VERSION ""

NS_ :

BS_:

BU_: WPC2 RLPSU DPSU APSU PSB SHVU_RR vHS_B2 FCS EMCU SLB ARS RCM CGW_CCU vDummy_HS_B ATS RLHV SGU PFSU ALBCU DSAU SWRC SHVU_FR RCS RRPSU BLTN_CAM SCM DLBCU OHCL RWPC RRHV WPC HOD ASAU

BO_ 1218 HU_USM_E_08: 8 CGW_CCU
 SG_ C_AVN_PTGHeightNValueSet : 13|3@1+ (1,0) [0|0] "" Vector__XXX
 SG_ CF_AVN_SCCMLReset : 16|2@1+ (1,0) [0|0] "" Vector__XXX
 SG_ C_TgltAwayCloseNValue : 18|2@1+ (1,0) [0|0] "" Vector__XXX
 SG_ C_HAnBNValueSet : 20|2@1+ (1,0) [0|0] "" Vector__XXX
 SG_ CF_AVN_RrSeatRemindNValueSet : 22|2@1+ (1,0) [0|0] "" Vector__XXX
 SG_ CF_AVN_DSWNValueSet : 24|2@1+ (1,0) [0|0] "" Vector__XXX
 SG_ CF_AVN_RRPSU_RLNValueSet : 26|3@1+ (1,0) [0|0] ""  APSU,RRPSU
 SG_ CF_AVN_APSUNValueSet : 29|3@1+ (1,0) [0|0] ""  APSU,ASAU
 SG_ CF_AVN_NCC_CameraNValueSet : 32|3@1+ (1,0) [0|0] "" Vector__XXX
 SG_ CF_AVN_RRPSU_RRNValueSet : 37|3@1+ (1,0) [0|0] ""  APSU,RRPSU
 SG_ CF_AVN_HtBlcAstNValueSet : 40|4@1+ (1,0) [0|0] ""  APSU,SHVU_FR
 SG_ CF_AVN_HtBlcDrvNValueSet : 44|4@1+ (1,0) [0|0] ""  APSU,SHVU_FR
 SG_ CF_AVN_SCCModeNValueSet : 48|2@1+ (1,0) [0|0] "" Vector__XXX
 SG_ CF_AVN_SCCMLChar1Set : 50|3@1+ (1,0) [0|0] "" Vector__XXX
 SG_ CF_AVN_UIPNValueSet : 54|2@1+ (1,0) [0|0] "" Vector__XXX
 SG_ CF_AVN_SCCMLChar2Set : 56|3@1+ (1,0) [0|0] "" Vector__XXX
 SG_ CF_AVN_SCCMLChar3Set : 59|3@1+ (1,0) [0|0] "" Vector__XXX
 SG_ CF_AVN_HDALCFuncNValueSet : 8|2@1+ (1,0) [0|0] "" Vector__XXX

BO_ 2323816451 CCU_CCS_01_00ms_3: 8 CGW_CCU

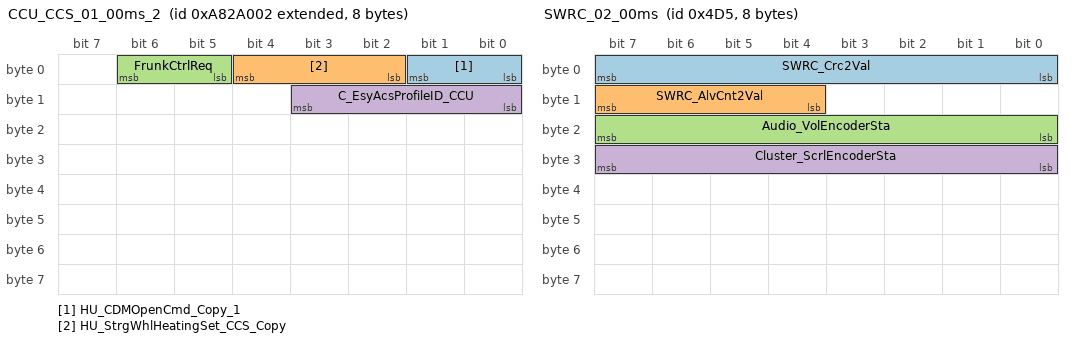
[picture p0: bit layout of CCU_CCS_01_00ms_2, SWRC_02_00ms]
BO_ 2323816450 CCU_CCS_01_00ms_2: 8 CGW_CCU
 SG_ HU_CDMOpenCmd_Copy_1 : 0|2@1+ (1,0) [0|0] "" Vector__XXX
 SG_ HU_StrgWhlHeatingSet_CCS_Copy : 2|3@1+ (1,0) [0|0] "" Vector__XXX
 SG_ FrunkCtrlReq : 5|2@1+ (1,0) [0|0] "" Vector__XXX
 SG_ C_EsyAcsProfileID_CCU : 8|4@1+ (1,0) [0|0] ""  DPSU

BO_ 2323816449 CCU_CCS_01_00ms_1: 8 CGW_CCU
 SG_ C_CtrlDrLockRlyCCS_Copy_2 : 0|2@1+ (1,0) [0|0] "" Vector__XXX
 SG_ C_TeleHeatingCmdIBOX_Copy_2 : 10|2@1+ (1,0) [0|0] "" Vector__XXX
 SG_ C_TeleStrgWhlHeatingCmdIBOX_Copy : 12|2@1+ (1,0) [0|0] "" Vector__XXX
 SG_ C_TeleDefoggerHeatingCmdIBOX_Cop : 14|2@1+ (1,0) [0|0] "" Vector__XXX
 SG_ C_TeleDrvSeatOpCmdIBOX_Copy_2 : 16|4@1+ (1,0) [0|0] ""  SHVU_FR,DPSU
 SG_ C_CtrlDrUnlockRlyCCS_Copy_2 : 2|2@1+ (1,0) [0|0] "" Vector__XXX
 SG_ C_TeleAstSeatOpCmdIBOX_Copy_2 : 20|4@1+ (1,0) [0|0] ""  APSU,SHVU_FR
 SG_ C_TeleRRSeatOpCmdIBOX_Copy_2 : 24|4@1+ (1,0) [0|0] ""  RRHV,SHVU_FR,SHVU_RR,RRPSU,ATS
 SG_ C_TeleRLSeatOpCmdIBOX_Copy_1 : 28|4@1+ (1,0) [0|0] ""  RLHV,SHVU_FR,SHVU_RR,RLPSU,ATS
 SG_ C_DrvWindowCmdAVN_Copy_2 : 38|4@1+ (1,0) [0|0] "" Vector__XXX
 SG_ C_HazardFromCCS_Copy_2 : 4|2@1+ (1,0) [0|0] "" Vector__XXX
 SG_ C_AstWindowCmdAVN_Copy_2 : 42|4@1+ (1,0) [0|0] "" Vector__XXX
 SG_ C_RRWindowCmdAVN_Copy_2 : 46|4@1+ (1,0) [0|0] "" Vector__XXX
 SG_ C_RLWindowCmdAVN_Copy_2 : 50|4@1+ (1,0) [0|0] "" Vector__XXX
 SG_ TailCtrlReq_Copy : 54|2@1+ (1,0) [0|0] "" Vector__XXX
 SG_ HazardCtrlReq_Copy : 56|2@1+ (1,0) [0|0] "" Vector__XXX
 SG_ HU_DATC_AirCleaningSet_Copy_1 : 58|2@1+ (1,0) [0|0] "" Vector__XXX
 SG_ C_PanicFromCCS_Copy_2 : 6|2@1+ (1,0) [0|0] "" Vector__XXX
 SG_ C_TeleFrontHeatingCmdIBOX_Copy_1 : 60|2@1+ (1,0) [0|0] "" Vector__XXX
 SG_ RAC_AirCleaningCtrlReq_Copy_1 : 62|2@1+ (1,0) [0|0] "" Vector__XXX
 SG_ C_PreCrankReq_Copy : 8|2@1+ (1,0) [0|0] "" Vector__XXX

BO_ 1227 PSM_01_00ms: 8 DPSU
 SG_ DrvIMS_MemoryP1Req : 0|2@1+ (1,0) [0|0] ""  CGW_CCU
 SG_ DrvIMS_PlyBckP2Req : 10|2@1+ (1,0) [0|0] ""  CGW_CCU
 SG_ DrvIMS_PlyBckP3Req : 12|2@1+ (1,0) [0|0] ""  CGW_CCU
 SG_ DrvIMS_PlyBckStpReq : 14|2@1+ (1,0) [0|0] ""  CGW_CCU
 SG_ SmrtIMS_PlyBckReq : 16|12@1+ (1,0) [0|0] ""  CGW_CCU
 SG_ DrvIMS_MemoryP2Req : 2|2@1+ (1,0) [0|0] ""  CGW_CCU
 SG_ PSM_IMSReq : 28|3@1+ (1,0) [0|0] ""  CGW_CCU
 SG_ SmrtIMS_ImgDBVal : 32|5@1+ (1,0) [0|0] ""  CGW_CCU
 SG_ SmrtIMS_PlyBckStpReq : 37|2@1+ (1,0) [0|0] ""  CGW_CCU
 SG_ DrvIMS_MemoryP3Req : 4|2@1+ (1,0) [0|0] ""  CGW_CCU
 SG_ SmrtIMS_EnterSwSta : 40|2@1+ (1,0) [0|0] ""  CGW_CCU
 SG_ DrvIMS_BzrReq : 42|2@1+ (1,0) [0|0] ""  CGW_CCU
 SG_ DrvIMS_ErrConWmgDis : 46|2@1+ (1,0) [0|0] ""  CGW_CCU
 SG_ PSM_DrvRlxReturn_Req : 48|3@1+ (1,0) [0|0] ""  CGW_CCU
 SG_ Drv_AutoRlxWrngDis : 51|3@1+ (1,0) [0|0] ""  CGW_CCU
 SG_ DrvIMS_MemorySetEnaSta : 6|2@1+ (1,0) [0|0] ""  CGW_CCU
 SG_ DrvIMS_PlyBckP1Req : 8|2@1+ (1,0) [0|0] ""  CGW_CCU

BO_ 2323816452 CCU_CCS_01_00ms_4: 8 CGW_CCU

BO_ 1237 SWRC_02_00ms: 8 SWRC
 SG_ SWRC_Crc2Val : 0|8@1+ (1,0) [0|0] "" Vector__XXX
 SG_ SWRC_AlvCnt2Val : 12|4@1+ (1,0) [0|0] "" Vector__XXX
 SG_ Audio_VolEncoderSta : 16|8@1+ (1,0) [0|0] ""  CGW_CCU
 SG_ Cluster_ScrlEncoderSta : 24|8@1+ (1,0) [0|0] ""  CGW_CCU

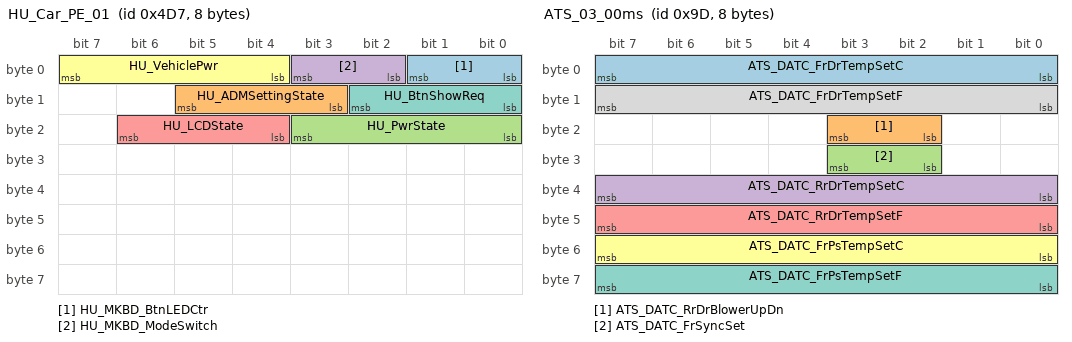
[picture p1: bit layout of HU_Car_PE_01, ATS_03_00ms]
BO_ 1239 HU_Car_PE_01: 8 CGW_CCU
 SG_ HU_MKBD_BtnLEDCtr : 0|2@1+ (1,0) [0|0] "" Vector__XXX
 SG_ HU_ADMSettingState : 11|3@1+ (1,0) [0|0] "" Vector__XXX
 SG_ HU_PwrState : 16|4@1+ (1,0) [0|0] ""  BLTN_CAM
 SG_ HU_MKBD_ModeSwitch : 2|2@1+ (1,0) [0|0] "" Vector__XXX
 SG_ HU_LCDState : 20|3@1+ (1,0) [0|0] "" Vector__XXX
 SG_ HU_VehiclePwr : 4|4@1+ (1,0) [0|0] ""  BLTN_CAM,SGU
 SG_ HU_BtnShowReq : 8|3@1+ (1,0) [0|0] ""  SWRC

BO_ 157 ATS_03_00ms: 8 ATS
 SG_ ATS_DATC_FrDrTempSetC : 0|8@1+ (0.5,14) [0|0] ""  CGW_CCU
 SG_ ATS_DATC_RrDrBlowerUpDn : 18|2@1+ (1,0) [0|0] ""  CGW_CCU
 SG_ ATS_DATC_FrSyncSet : 26|2@1+ (1,0) [0|0] ""  CGW_CCU
 SG_ ATS_DATC_RrDrTempSetC : 32|8@1+ (0.5,14) [0|0] ""  CGW_CCU
 SG_ ATS_DATC_RrDrTempSetF : 40|8@1+ (1,56) [0|0] ""  CGW_CCU
 SG_ ATS_DATC_FrPsTempSetC : 48|8@1+ (0.5,14) [0|0] ""  CGW_CCU
 SG_ ATS_DATC_FrPsTempSetF : 56|8@1+ (1,56) [0|0] ""  CGW_CCU
 SG_ ATS_DATC_FrDrTempSetF : 8|8@1+ (1,56) [0|0] ""  CGW_CCU

BO_ 158 ATS_02_00ms: 8 ATS
 SG_ ATS_DATC_FrDrBlowerSet : 12|4@1+ (1,0) [0|0] ""  CGW_CCU
 SG_ ATS_DATC_RrDrTempUpDn : 2|2@1+ (1,0) [0|0] ""  CGW_CCU
 SG_ ATS_DATC_RrDrBlowerSet : 20|4@1+ (1,0) [0|0] ""  CGW_CCU
 SG_ ATS_DATC_RrDrModeSet : 24|4@1+ (1,0) [0|0] ""  CGW_CCU
 SG_ ATS_DATC_FrDrModeSet : 28|4@1+ (1,0) [0|0] ""  CGW_CCU
 SG_ ATS_DATC_RrOnOffSet : 32|2@1+ (1,0) [0|0] "" Vector__XXX
 SG_ ATS_DATC_IntakeSet : 34|2@1+ (1,0) [0|0] ""  CGW_CCU
 SG_ ATS_DATC_OffReq : 36|2@1+ (1,0) [0|0] "" Vector__XXX
 SG_ ATS_DATC_FrDrAutoSet : 38|2@1+ (1,0) [0|0] ""  CGW_CCU
 SG_ ATS_DATC_FrPsTempUpDn : 4|2@1+ (1,0) [0|0] ""  CGW_CCU
 SG_ ATS_DATC_FrDefog : 42|2@1+ (1,0) [0|0] ""  CGW_CCU
 SG_ ATS_DATC_RrSyncSet : 44|2@1+ (1,0) [0|0] ""  CGW_CCU
 SG_ ATS_DATC_AcSet : 46|2@1+ (1,0) [0|0] ""  CGW_CCU
 SG_ ATS_DATC_AirCleaningSet : 56|2@1+ (1,0) [0|0] ""  CGW_CCU
 SG_ ATS_DATC_FrDrBlowerUpDn : 58|2@1+ (1,0) [0|0] ""  CGW_CCU
 SG_ ATS_DATC_FrDrTempUpDn : 6|2@1+ (1,0) [0|0] ""  CGW_CCU
 SG_ ATS_DATC_RrDrAutoSet : 62|2@1+ (1,0) [0|0] ""  CGW_CCU

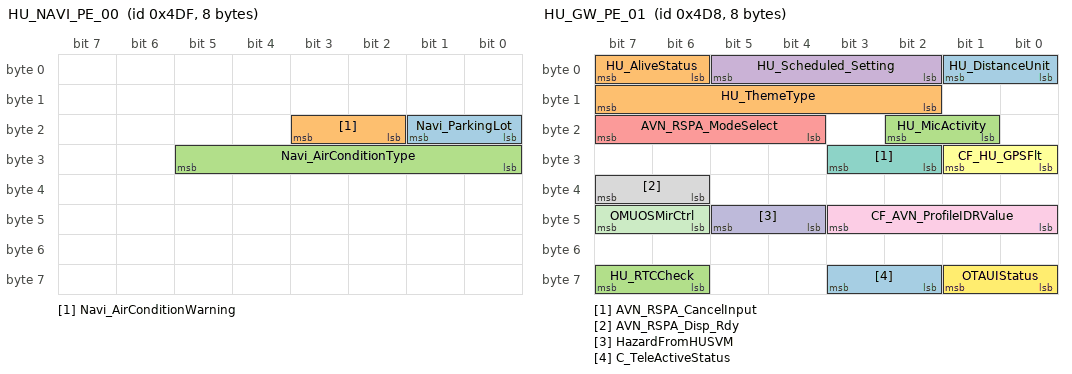
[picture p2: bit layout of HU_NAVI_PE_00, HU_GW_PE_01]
BO_ 1247 HU_NAVI_PE_00: 8 CGW_CCU
 SG_ Navi_ParkingLot : 16|2@1+ (1,0) [0|0] "" Vector__XXX
 SG_ Navi_AirConditionWarning : 18|2@1+ (1,0) [0|0] ""  RCM
 SG_ Navi_AirConditionType : 24|6@1+ (1,0) [0|0] "" Vector__XXX

BO_ 1240 HU_GW_PE_01: 8 CGW_CCU
 SG_ HU_DistanceUnit : 0|2@1+ (1,0) [0|0] "" Vector__XXX
 SG_ HU_ThemeType : 10|6@1+ (1,0) [0|0] ""  ATS,BLTN_CAM
 SG_ HU_MicActivity : 17|2@1+ (1,0) [0|0] "" Vector__XXX
 SG_ HU_Scheduled_Setting : 2|4@1+ (1,0) [0|0] "" Vector__XXX
 SG_ AVN_RSPA_ModeSelect : 20|4@1+ (1,0) [0|0] "" Vector__XXX
 SG_ CF_HU_GPSFlt : 24|2@1+ (1,0) [0|0] "" Vector__XXX
 SG_ AVN_RSPA_CancelInput : 26|2@1+ (1,0) [0|3] "" Vector__XXX
 SG_ AVN_RSPA_Disp_Rdy : 38|2@1+ (1,0) [0|0] "" Vector__XXX
 SG_ CF_AVN_ProfileIDRValue : 40|4@1+ (1,0) [0|0] ""  WPC,RWPC,DPSU,DLBCU,RCM,BLTN_CAM,SGU,WPC2
 SG_ HazardFromHUSVM : 44|2@1+ (1,0) [0|0] "" Vector__XXX
 SG_ OMUOSMirCtrl : 46|2@1+ (1,0) [0|0] "" Vector__XXX
 SG_ OTAUIStatus : 56|2@1+ (1,0) [0|0] "" Vector__XXX
 SG_ C_TeleActiveStatus : 58|2@1+ (1,0) [0|0] "" Vector__XXX
 SG_ HU_AliveStatus : 6|2@1+ (1,0) [0|0] "" Vector__XXX
 SG_ HU_RTCCheck : 62|2@1+ (1,0) [0|0] ""  APSU

BO_ 2424580353 DATC_12_200ms_1: 8 CGW_CCU
 SG_ DATC_Crc12Val : 0|16@1+ (1,0) [0|0] "" Vector__XXX
 SG_ DATC_AlvCnt12Val : 16|8@1+ (1,0) [0|0] "" Vector__XXX
 SG_ DATC_StrWhlHtrSwReq : 24|2@1+ (1,0) [0|0] "" Vector__XXX
 SG_ DATC_FRStHtrSwReq : 26|2@1+ (1,0) [0|0] ""  APSU,SHVU_FR,SHVU_RR,DPSU
 SG_ DATC_FRStVentSwReq : 28|2@1+ (1,0) [0|0] ""  APSU,SHVU_FR,SHVU_RR,DPSU
 SG_ DATC_RrDefSw : 30|2@1+ (1,0) [0|0] "" Vector__XXX
 SG_ DATC_FLStOpReq : 32|4@1+ (1,0) [0|0] ""  APSU,SHVU_FR,SHVU_RR,DPSU
 SG_ DATC_FRStOpReq : 36|4@1+ (1,0) [0|0] ""  APSU,SHVU_FR,SHVU_RR
 SG_ DATC_FLStHtrSwReq : 40|2@1+ (1,0) [0|0] ""  APSU,SHVU_FR,SHVU_RR,DPSU
 SG_ DATC_FLStVentSwReq : 42|2@1+ (1,0) [0|0] ""  APSU,SHVU_FR,SHVU_RR,DPSU
 SG_ DATC_FLStTmblrSwReq : 44|2@1+ (1,0) [0|0] ""  APSU,SHVU_FR
 SG_ DATC_FRStTmblrSwReq : 46|2@1+ (1,0) [0|0] ""  APSU,SHVU_FR
 SG_ DATC_RRStHtrSwReq : 48|2@1+ (1,0) [0|0] ""  RRHV,SHVU_FR,SHVU_RR,RRPSU
 SG_ DATC_RRStVentSwReq : 50|2@1+ (1,0) [0|0] ""  RRHV,SHVU_FR,SHVU_RR,RRPSU
 SG_ DATC_RLStHtrSwReq : 52|2@1+ (1,0) [0|0] ""  RLHV,SHVU_FR,SHVU_RR,RLPSU
 SG_ DATC_RLStVentSwReq : 54|2@1+ (1,0) [0|0] ""  RLHV,SHVU_FR,SHVU_RR,RLPSU
 SG_ DATC_FRWndShldHtSW : 56|2@1+ (1,0) [0|0] "" Vector__XXX
 SG_ DATC_WhistlelNoise : 58|2@1+ (1,0) [0|0] "" Vector__XXX
 SG_ DATC_WdwClsReq : 60|2@1+ (1,0) [0|0] "" Vector__XXX
 SG_ DATC_RRSyncDis : 62|2@1+ (1,0) [0|0] ""  ATS

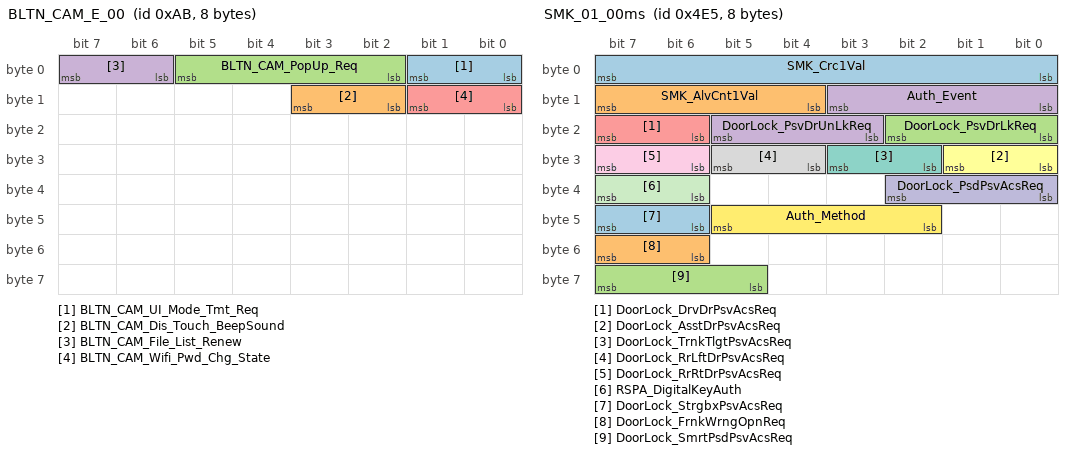
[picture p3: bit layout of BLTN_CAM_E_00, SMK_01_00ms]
BO_ 171 BLTN_CAM_E_00: 8 BLTN_CAM
 SG_ BLTN_CAM_UI_Mode_Tmt_Req : 0|2@1+ (1,0) [0|0] ""  CGW_CCU
 SG_ BLTN_CAM_Dis_Touch_BeepSound : 10|2@1+ (1,0) [0|0] "" Vector__XXX
 SG_ BLTN_CAM_PopUp_Req : 2|4@1+ (1,0) [0|0] ""  CGW_CCU
 SG_ BLTN_CAM_File_List_Renew : 6|2@1+ (1,0) [0|0] ""  CGW_CCU
 SG_ BLTN_CAM_Wifi_Pwd_Chg_State : 8|2@1+ (1,0) [0|0] ""  CGW_CCU

BO_ 1253 SMK_01_00ms: 8 CGW_CCU
 SG_ SMK_Crc1Val : 0|8@1+ (1,0) [0|0] "" Vector__XXX
 SG_ SMK_AlvCnt1Val : 12|4@1+ (1,0) [0|0] "" Vector__XXX
 SG_ DoorLock_PsvDrLkReq : 16|3@1+ (1,0) [0|0] "" Vector__XXX
 SG_ DoorLock_PsvDrUnLkReq : 19|3@1+ (1,0) [0|0] "" Vector__XXX
 SG_ DoorLock_DrvDrPsvAcsReq : 22|2@1+ (1,0) [0|0] "" Vector__XXX
 SG_ DoorLock_AsstDrPsvAcsReq : 24|2@1+ (1,0) [0|0] "" Vector__XXX
 SG_ DoorLock_TrnkTlgtPsvAcsReq : 26|2@1+ (1,0) [0|0] "" Vector__XXX
 SG_ DoorLock_RrLftDrPsvAcsReq : 28|2@1+ (1,0) [0|0] "" Vector__XXX
 SG_ DoorLock_RrRtDrPsvAcsReq : 30|2@1+ (1,0) [0|0] "" Vector__XXX
 SG_ DoorLock_PsdPsvAcsReq : 32|3@1+ (1,0) [0|0] "" Vector__XXX
 SG_ RSPA_DigitalKeyAuth : 38|2@1+ (1,0) [0|0] "" Vector__XXX
 SG_ Auth_Method : 42|4@1+ (1,0) [0|0] ""  DPSU
 SG_ DoorLock_StrgbxPsvAcsReq : 46|2@1+ (1,0) [0|0] "" Vector__XXX
 SG_ DoorLock_FrnkWrngOpnReq : 54|2@1+ (1,0) [0|0] "" Vector__XXX
 SG_ DoorLock_SmrtPsdPsvAcsReq : 61|3@1+ (1,0) [0|0] "" Vector__XXX
 SG_ Auth_Event : 8|4@1+ (1,0) [0|0] ""  DPSU

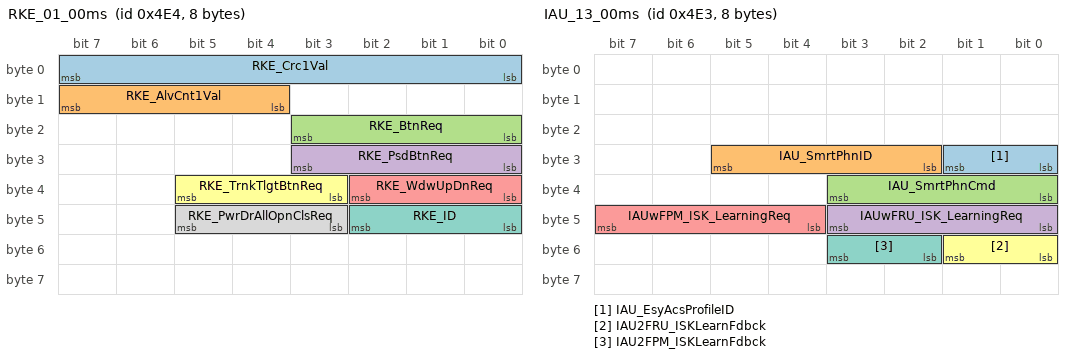
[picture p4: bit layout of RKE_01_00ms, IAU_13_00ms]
BO_ 1252 RKE_01_00ms: 8 CGW_CCU
 SG_ RKE_Crc1Val : 0|8@1+ (1,0) [0|0] "" Vector__XXX
 SG_ RKE_AlvCnt1Val : 12|4@1+ (1,0) [0|0] "" Vector__XXX
 SG_ RKE_BtnReq : 16|4@1+ (1,0) [0|0] ""  ATS
 SG_ RKE_PsdBtnReq : 24|4@1+ (1,0) [0|0] "" Vector__XXX
 SG_ RKE_WdwUpDnReq : 32|3@1+ (1,0) [0|0] ""  RCM
 SG_ RKE_TrnkTlgtBtnReq : 35|3@1+ (1,0) [0|0] "" Vector__XXX
 SG_ RKE_ID : 40|3@1+ (1,0) [0|0] "" Vector__XXX
 SG_ RKE_PwrDrAllOpnClsReq : 43|3@1+ (1,0) [0|0] "" Vector__XXX

BO_ 1251 IAU_13_00ms: 8 CGW_CCU
 SG_ IAU_EsyAcsProfileID : 24|2@1+ (1,0) [0|0] ""  DPSU
 SG_ IAU_SmrtPhnID : 26|4@1+ (1,0) [0|0] "" Vector__XXX
 SG_ IAU_SmrtPhnCmd : 32|4@1+ (1,0) [0|0] "" Vector__XXX
 SG_ IAUwFRU_ISK_LearningReq : 40|4@1+ (1,0) [0|0] "" Vector__XXX
 SG_ IAUwFPM_ISK_LearningReq : 44|4@1+ (1,0) [0|0] "" Vector__XXX
 SG_ IAU2FRU_ISKLearnFdbck : 48|2@1+ (1,0) [0|0] "" Vector__XXX
 SG_ IAU2FPM_ISKLearnFdbck : 50|2@1+ (1,0) [0|0] "" Vector__XXX

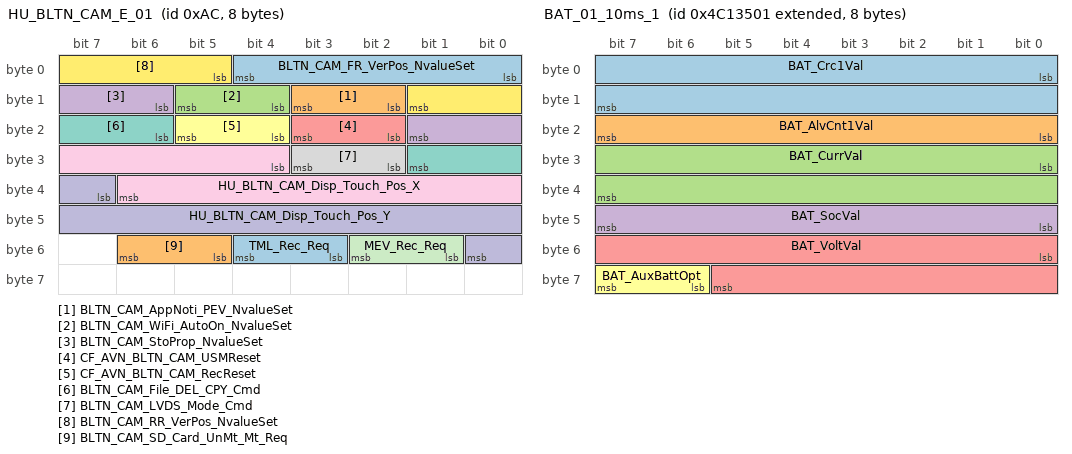
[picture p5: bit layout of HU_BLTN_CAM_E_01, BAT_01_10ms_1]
BO_ 172 HU_BLTN_CAM_E_01: 8 CGW_CCU
 SG_ BLTN_CAM_FR_VerPos_NvalueSet : 0|5@1+ (1,0) [0|0] ""  BLTN_CAM
 SG_ BLTN_CAM_AppNoti_PEV_NvalueSet : 10|2@1+ (1,0) [0|0] ""  BLTN_CAM
 SG_ BLTN_CAM_WiFi_AutoOn_NvalueSet : 12|2@1+ (1,0) [0|0] ""  BLTN_CAM
 SG_ BLTN_CAM_StoProp_NvalueSet : 14|4@1+ (1,0) [0|0] ""  BLTN_CAM
 SG_ CF_AVN_BLTN_CAM_USMReset : 18|2@1+ (1,0) [0|0] ""  BLTN_CAM
 SG_ CF_AVN_BLTN_CAM_RecReset : 20|2@1+ (1,0) [0|0] ""  BLTN_CAM
 SG_ BLTN_CAM_File_DEL_CPY_Cmd : 22|4@1+ (1,0) [0|0] ""  BLTN_CAM
 SG_ BLTN_CAM_LVDS_Mode_Cmd : 26|2@1+ (1,0) [0|0] ""  BLTN_CAM
 SG_ HU_BLTN_CAM_Disp_Touch_Pos_X : 28|11@1+ (1,0) [0|0] ""  BLTN_CAM
 SG_ HU_BLTN_CAM_Disp_Touch_Pos_Y : 39|10@1+ (1,0) [0|0] ""  BLTN_CAM
 SG_ MEV_Rec_Req : 49|2@1+ (1,0) [0|0] ""  BLTN_CAM
 SG_ BLTN_CAM_RR_VerPos_NvalueSet : 5|5@1+ (1,0) [0|0] ""  BLTN_CAM
 SG_ TML_Rec_Req : 51|2@1+ (1,0) [0|0] ""  BLTN_CAM
 SG_ BLTN_CAM_SD_Card_UnMt_Mt_Req : 53|2@1+ (1,0) [0|0] ""  BLTN_CAM

BO_ 2227254529 BAT_01_10ms_1: 8 CGW_CCU
 SG_ BAT_Crc1Val : 0|16@1+ (1,0) [0|0] "" Vector__XXX
 SG_ BAT_AlvCnt1Val : 16|8@1+ (1,0) [0|0] "" Vector__XXX
 SG_ BAT_CurrVal : 24|16@1+ (0.01,-327) [0|0] "A" Vector__XXX
 SG_ BAT_SocVal : 40|8@1+ (1,0) [0|0] "%"  BLTN_CAM
 SG_ BAT_VoltVal : 48|14@1+ (0.001,6) [0|0] "V" Vector__XXX
 SG_ BAT_AuxBattOpt : 62|2@1+ (1,0) [0|0] "" Vector__XXX

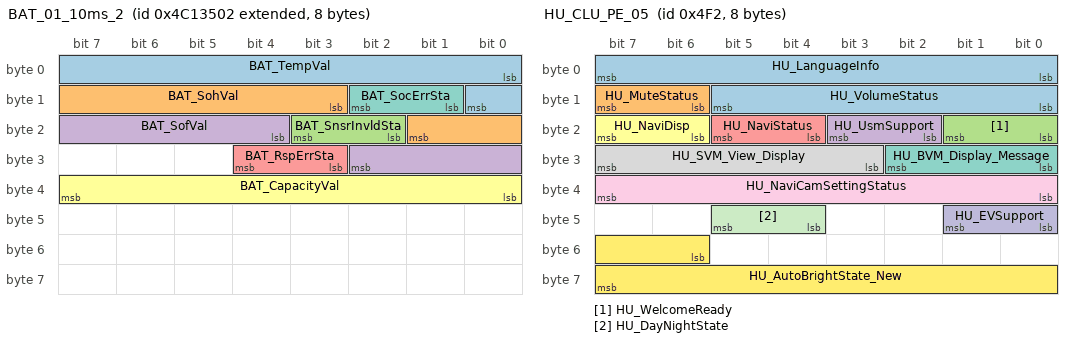
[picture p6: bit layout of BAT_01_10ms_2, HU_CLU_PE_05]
BO_ 2227254530 BAT_01_10ms_2: 8 CGW_CCU
 SG_ BAT_TempVal : 0|9@1+ (0.5,-40) [0|0] "¡É" Vector__XXX
 SG_ BAT_SohVal : 11|7@1+ (1,0) [0|0] "%" Vector__XXX
 SG_ BAT_SnsrInvldSta : 18|2@1+ (1,0) [0|0] "" Vector__XXX
 SG_ BAT_SofVal : 20|7@1+ (0.1,0) [0|0] "V" Vector__XXX
 SG_ BAT_RspErrSta : 27|2@1+ (1,0) [0|0] "" Vector__XXX
 SG_ BAT_CapacityVal : 32|8@1+ (1,0) [0|0] "" Vector__XXX
 SG_ BAT_SocErrSta : 9|2@1+ (1,0) [0|0] "" Vector__XXX

BO_ 1266 HU_CLU_PE_05: 8 CGW_CCU
 SG_ HU_LanguageInfo : 0|8@1+ (1,0) [0|0] ""  ATS,BLTN_CAM
 SG_ HU_MuteStatus : 14|2@1+ (1,0) [0|0] "" Vector__XXX
 SG_ HU_WelcomeReady : 16|2@1+ (1,0) [0|0] "" Vector__XXX
 SG_ HU_UsmSupport : 18|2@1+ (1,0) [0|0] "" Vector__XXX
 SG_ HU_NaviStatus : 20|2@1+ (1,0) [0|0] "" Vector__XXX
 SG_ HU_NaviDisp : 22|2@1+ (1,0) [0|0] "" Vector__XXX
 SG_ HU_BVM_Display_Message : 24|3@1+ (1,0) [0|0] "" Vector__XXX
 SG_ HU_SVM_View_Display : 27|5@1+ (1,0) [0|0] "" Vector__XXX
 SG_ HU_NaviCamSettingStatus : 32|8@1+ (1,0) [0|0] "" Vector__XXX
 SG_ HU_EVSupport : 40|2@1+ (1,0) [0|0] "" Vector__XXX
 SG_ HU_DayNightState : 44|2@1+ (1,0) [0|0] "" Vector__XXX
 SG_ HU_AutoBrightState_New : 54|10@1+ (1,0) [0|0] "" Vector__XXX
 SG_ HU_VolumeStatus : 8|6@1+ (1,0) [0|0] "" Vector__XXX

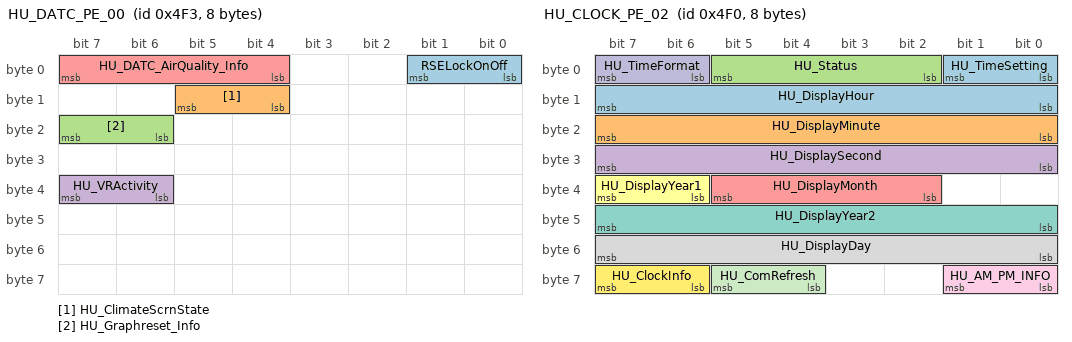
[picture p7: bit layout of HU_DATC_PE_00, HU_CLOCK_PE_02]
BO_ 1267 HU_DATC_PE_00: 8 CGW_CCU
 SG_ RSELockOnOff : 0|2@1+ (1,0) [0|0] ""  APSU,ATS
 SG_ HU_ClimateScrnState : 12|2@1+ (1,0) [0|0] "" Vector__XXX
 SG_ HU_Graphreset_Info : 22|2@1+ (1,0) [0|0] "" Vector__XXX
 SG_ HU_VRActivity : 38|2@1+ (1,0) [0|0] "" Vector__XXX
 SG_ HU_DATC_AirQuality_Info : 4|4@1+ (1,0) [0|0] "" Vector__XXX

BO_ 191 RL_SHVU_03_200ms: 8 RLHV
 SG_ RL_SHVU_DTCdisplay : 0|8@1+ (1,0) [0|0] ""  ATS
 SG_ RL_SHVU_DiagMode : 8|2@1+ (1,0) [0|0] ""  ATS

BO_ 1264 HU_CLOCK_PE_02: 8 CGW_CCU
 SG_ HU_TimeSetting : 0|2@1+ (1,0) [0|0] ""  ATS,BLTN_CAM
 SG_ HU_DisplayMinute : 16|8@1+ (1,0) [0|0] ""  ATS,BLTN_CAM
 SG_ HU_Status : 2|4@1+ (1,0) [0|0] ""  ATS,BLTN_CAM
 SG_ HU_DisplaySecond : 24|8@1+ (1,0) [0|0] ""  ATS,BLTN_CAM
 SG_ HU_DisplayMonth : 34|4@1+ (1,0) [0|0] ""  ATS,BLTN_CAM
 SG_ HU_DisplayYear1 : 38|2@1+ (1,0) [0|0] ""  ATS,BLTN_CAM
 SG_ HU_DisplayYear2 : 40|8@1+ (1,0) [0|0] ""  ATS,BLTN_CAM
 SG_ HU_DisplayDay : 48|8@1+ (1,0) [0|0] ""  ATS,BLTN_CAM
 SG_ HU_AM_PM_INFO : 56|2@1+ (1,0) [0|0] ""  ATS,BLTN_CAM
 SG_ HU_TimeFormat : 6|2@1+ (1,0) [0|0] ""  ATS,BLTN_CAM
 SG_ HU_ComRefresh : 60|2@1+ (1,0) [0|0] ""  ATS,BLTN_CAM
 SG_ HU_ClockInfo : 62|2@1+ (1,0) [0|0] ""  ATS,BLTN_CAM
 SG_ HU_DisplayHour : 8|8@1+ (1,0) [0|0] ""  ATS,BLTN_CAM

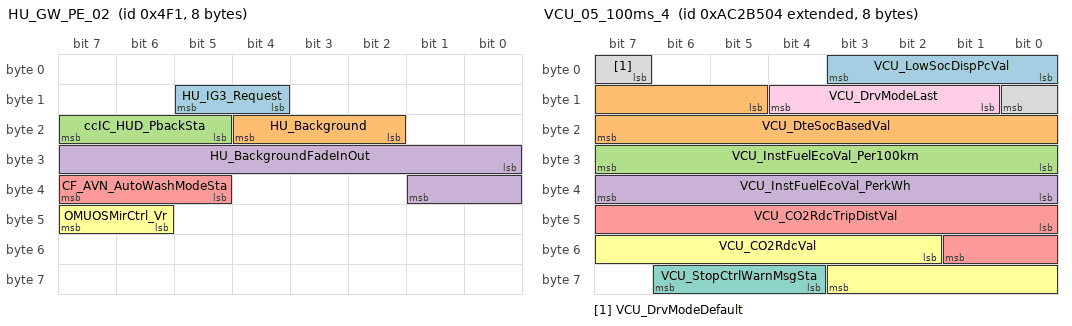
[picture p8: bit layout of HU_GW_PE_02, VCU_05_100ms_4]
BO_ 1265 HU_GW_PE_02: 8 CGW_CCU
 SG_ HU_IG3_Request : 12|2@1+ (1,0) [0|0] "" Vector__XXX
 SG_ HU_Background : 18|3@1+ (1,0) [0|0] ""  ATS,BLTN_CAM
 SG_ ccIC_HUD_PbackSta : 21|3@1+ (1,0) [0|0] ""  DPSU
 SG_ HU_BackgroundFadeInOut : 24|10@1+ (0.1,0) [0|0] "%"  ATS,BLTN_CAM
 SG_ CF_AVN_AutoWashModeSta : 37|3@1+ (1,0) [0|0] "" Vector__XXX
 SG_ OMUOSMirCtrl_Vr : 46|2@1+ (1,0) [0|0] "" Vector__XXX

BO_ 2328016132 VCU_05_100ms_4: 8 CGW_CCU
 SG_ VCU_LowSocDispPcVal : 0|4@1+ (1,0) [0|0] "" Vector__XXX
 SG_ VCU_DteSocBasedVal : 13|11@1+ (1,0) [0|0] "km" Vector__XXX
 SG_ VCU_InstFuelEcoVal_Per100km : 24|8@1+ (0.5,0) [0|126.5] "kWh/100km" Vector__XXX
 SG_ VCU_InstFuelEcoVal_PerkWh : 32|8@1+ (0.1,0) [0|25.5] "km/kWh" Vector__XXX
 SG_ VCU_CO2RdcTripDistVal : 40|10@1+ (1,0) [0|1023] "km" Vector__XXX
 SG_ VCU_CO2RdcVal : 50|10@1+ (100,0) [0|102300] "g" Vector__XXX
 SG_ VCU_StopCtrlWarnMsgSta : 60|3@1+ (1,0) [0|0] "" Vector__XXX
 SG_ VCU_DrvModeDefault : 7|2@1+ (1,0) [0|0] "" Vector__XXX
 SG_ VCU_DrvModeLast : 9|4@1+ (1,0) [0|0] "" Vector__XXX

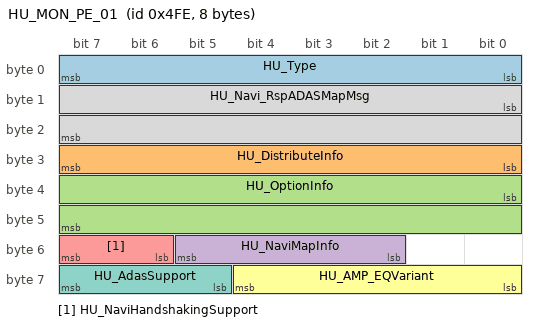
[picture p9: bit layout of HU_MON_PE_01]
BO_ 1278 HU_MON_PE_01: 8 CGW_CCU
 SG_ HU_Type : 0|8@1+ (1,0) [0|0] ""  BLTN_CAM
 SG_ HU_DistributeInfo : 24|8@1+ (1,0) [0|0] ""  BLTN_CAM
 SG_ HU_OptionInfo : 32|16@1+ (1,0) [0|0] ""  RCM,BLTN_CAM,WPC2
 SG_ HU_NaviMapInfo : 50|4@1+ (1,0) [0|0] "" Vector__XXX
 SG_ HU_NaviHandshakingSupport : 54|2@1+ (1,0) [0|0] "" Vector__XXX
 SG_ HU_AMP_EQVariant : 56|5@1+ (1,0) [0|0] "" Vector__XXX
 SG_ HU_AdasSupport : 61|3@1+ (1,0) [0|0] "" Vector__XXX
 SG_ HU_Navi_RspADASMapMsg : 8|16@1+ (1,0) [0|0] "" Vector__XXX

BO_TX_BU_ 191 : RLHV,SHVU_FR,SHVU_RR;
CM_ BO_ 1218 "[EC] On Event and On Change";
CM_ SG_ 1218 C_AVN_PTGHeightNValueSet "Power Tailgate(Trunk) Height Request Signal";
CM_ SG_ 1218 CF_AVN_SCCMLReset "Request for SCC-ML reset";
CM_ SG_ 1218 C_HAnBNValueSet "USM Request for Horn Feedback";
CM_ SG_ 1218 CF_AVN_RrSeatRemindNValueSet "USM Request for Rear Seat Remind function";
CM_ SG_ 1218 CF_AVN_DSWNValueSet "Request for driver state warning";
CM_ SG_ 1218 CF_AVN_RRPSU_RLNValueSet "Request for Seat easy access of rear left seat";
CM_ SG_ 1218 CF_AVN_APSUNValueSet "Request for easy access of passenger seat";
CM_ SG_ 1218 CF_AVN_NCC_CameraNValueSet "Request for Eco Vehicle NCC";
CM_ SG_ 1218 CF_AVN_RRPSU_RRNValueSet "Request for seat easy access of rear right seat";
CM_ SG_ 1218 CF_AVN_HtBlcAstNValueSet "Request for Passenger seat heater balance";
CM_ SG_ 1218 CF_AVN_HtBlcDrvNValueSet "Request for Driver seat heater balance";
CM_ SG_ 1218 CF_AVN_SCCModeNValueSet "This signal request for scc setting(Whether sccml or following driving mode)";
CM_ SG_ 1218 CF_AVN_SCCMLChar1Set "Request for scc-ml acceleration learning result change";
CM_ SG_ 1218 CF_AVN_UIPNValueSet "USM Request for Ultrasonic Intrusion Protection function";
CM_ SG_ 1218 CF_AVN_SCCMLChar2Set "Request for scc-ml distnace learning result change";
CM_ SG_ 1218 CF_AVN_SCCMLChar3Set "Request for scc-ml reaction learning result change";
CM_ SG_ 1218 CF_AVN_HDALCFuncNValueSet "Request for highway lane change assist";
CM_ BO_ 2323816451 "[EC] On Event and On Change";
CM_ BO_ 2323816450 "[EC] On Event and On Change";
CM_ SG_ 2323816450 HU_CDMOpenCmd_Copy_1 "Command for CDM open/close";
CM_ SG_ 2323816450 FrunkCtrlReq "This signal is request for controling Frunk.";
CM_ SG_ 2323816450 C_EsyAcsProfileID_CCU "This signal indicates the current detected profile ID by smartphone APP.
(The drv seat move to the easy access position of the detected profile ID when receive the signal)";
CM_ BO_ 2323816449 "[EC] On Event and On Change";
CM_ SG_ 2323816449 C_CtrlDrLockRlyCCS_Copy_2 "Command for Remote Door Lock";
CM_ SG_ 2323816449 C_TeleHeatingCmdIBOX_Copy_2 "'Command for Remote Heating

(Steering Wheel, Rear Window, Side Mirror)";
CM_ SG_ 2323816449 C_TeleStrgWhlHeatingCmdIBOX_Copy "'Command for Remote Heating
(Steering Wheel)";
CM_ SG_ 2323816449 C_TeleDefoggerHeatingCmdIBOX_Cop "'Command for Remote Heating
(Rear Window, Side Mirror)";
CM_ SG_ 2323816449 C_TeleDrvSeatOpCmdIBOX_Copy_2 "Command for Remote Seat Heat/Vent control (Driver)";
CM_ SG_ 2323816449 C_CtrlDrUnlockRlyCCS_Copy_2 "Command for Remote Door UnLock";
CM_ SG_ 2323816449 C_TeleAstSeatOpCmdIBOX_Copy_2 "Command for Remote Seat Heat/Vent control (Passenger)";
CM_ SG_ 2323816449 C_TeleRRSeatOpCmdIBOX_Copy_2 "Command for Remote Seat Heat/Vent control (Rear Right)";
CM_ SG_ 2323816449 C_TeleRLSeatOpCmdIBOX_Copy_1 "Command for Remote Seat Heat/Vent control (Rear Left)";
CM_ SG_ 2323816449 C_DrvWindowCmdAVN_Copy_2 "This signal indicates DRV Window Open/Close Command";
CM_ SG_ 2323816449 C_HazardFromCCS_Copy_2 "Command for Remote Hazard";
CM_ SG_ 2323816449 C_AstWindowCmdAVN_Copy_2 "This signal indicates AST Window Open/Close Command";
CM_ SG_ 2323816449 C_RRWindowCmdAVN_Copy_2 "This signal indicates RR Window Open/Close Command";
CM_ SG_ 2323816449 C_RLWindowCmdAVN_Copy_2 "This signal indicates RL Window Open/Close Command";
CM_ SG_ 2323816449 TailCtrlReq_Copy "This signal is for cotroling Tail lamp.";
CM_ SG_ 2323816449 HazardCtrlReq_Copy "This signal is request for controling Hazard lamp.";
CM_ SG_ 2323816449 HU_DATC_AirCleaningSet_Copy_1 "Air Cleaning System set";
CM_ SG_ 2323816449 C_PanicFromCCS_Copy_2 "Command for Remote Panic (Only for USA)";
CM_ SG_ 2323816449 C_TeleFrontHeatingCmdIBOX_Copy_1 "Command for Remote Heating (Front Window)";
CM_ SG_ 2323816449 RAC_AirCleaningCtrlReq_Copy_1 "RAC_Air Cleaning Control Request";
CM_ SG_ 2323816449 C_PreCrankReq_Copy "Command for B-CAN wake up singal (Need to send this signal before other remote commands)";
CM_ BO_ 1227 "[EC] On Event and On Change";
CM_ SG_ 1227 DrvIMS_MemoryP1Req "PSM_DriverSeatPositionMemoryP1Request";
CM_ SG_ 1227 DrvIMS_PlyBckP2Req "PSM_PlayBackP2Request";
CM_ SG_ 1227 DrvIMS_PlyBckP3Req "PSM_PlayBackP3Request";
CM_ SG_ 1227 DrvIMS_PlyBckStpReq "PSM_PlayBackStopRequest";
CM_ SG_ 1227 SmrtIMS_PlyBckReq "HCIMS_PlayBackRequest";
CM_ SG_ 1227 DrvIMS_MemoryP2Req "PSM_DriverSeatPositionMemoryP2Request";
CM_ SG_ 1227 SmrtIMS_ImgDBVal "Smart IMS image DB number";
CM_ SG_ 1227 SmrtIMS_PlyBckStpReq "HCIMS_Status";
CM_ SG_ 1227 DrvIMS_MemoryP3Req "PSM_DriverSeatPositionMemoryP3Request";
CM_ SG_ 1227 SmrtIMS_EnterSwSta "Smart IMS switch on using IMS switch";
CM_ SG_ 1227 DrvIMS_BzrReq "PSM_DriverSeatImsBuzzerRequest";
CM_ SG_ 1227 DrvIMS_ErrConWmgDis "Warning about IMS Mem/Play Error Condition";
CM_ SG_ 1227 Drv_AutoRlxWrngDis "Drive seat auto relax warning information for AVN display";
CM_ SG_ 1227 DrvIMS_MemorySetEnaSta "PSM_MemorySetEnableStatus";
CM_ SG_ 1227 DrvIMS_PlyBckP1Req "PSM_PlayBackP1Request";
CM_ BO_ 2323816452 "[EC] On Event and On Change";
CM_ BO_ 1237 "[EC] On Event and On Change";
CM_ SG_ 1237 SWRC_Crc2Val "SWRC_CyclicRedundancyCheck2Value";
CM_ SG_ 1237 SWRC_AlvCnt2Val "SWRC_AliveCounter2Value";
CM_ SG_ 1237 Audio_VolEncoderSta "Audio_VolumeScrollSwitchStatus";
CM_ SG_ 1237 Cluster_ScrlEncoderSta "Cluster_ScrollSwitchStatus";
CM_ BO_ 1239 "[PE] Periodic and On Event";
CM_ SG_ 1239 HU_ADMSettingState "Information for ADM(Accessry Delay Mode) Setting Vaule in HU / Made at 2021.1.25";
CM_ SG_ 1239 HU_MKBD_ModeSwitch "This signal is used for the 'AVNT/Climate Switching Keyboard' to switch the display of buttons.";
CM_ SG_ 1239 HU_VehiclePwr "Information for the H/U power status for ADM(Accessary Delay Mode)";
CM_ BO_ 157 "[EC] On Event and On Change";
CM_ SG_ 157 ATS_DATC_FrDrTempSetC "Front Driver side Temp Set (Celsius)";
CM_ SG_ 157 ATS_DATC_RrDrBlowerUpDn "Rear Driver side Blower Up Down";
CM_ SG_ 157 ATS_DATC_FrSyncSet "Front Sync Set";
CM_ SG_ 157 ATS_DATC_RrDrTempSetC "Rear Driver side Temp Set (Celsius)";
CM_ SG_ 157 ATS_DATC_RrDrTempSetF "Rear Driver side Temp Set (Fahrenheit)";
CM_ SG_ 157 ATS_DATC_FrPsTempSetC "Front Passenger side Temp Set (Celsius)";
CM_ SG_ 157 ATS_DATC_FrPsTempSetF "Front Passenger side Temp Set (Fahrenheit)";
CM_ SG_ 157 ATS_DATC_FrDrTempSetF "Front Driver side Temp Set (Fahrenheit)";
CM_ BO_ 158 "[EC] On Event and On Change";
CM_ SG_ 158 ATS_DATC_FrDrBlowerSet "Front Driver side Blower Set";
CM_ SG_ 158 ATS_DATC_RrDrTempUpDn "Rear Driver side Temp Up Down";
CM_ SG_ 158 ATS_DATC_RrDrBlowerSet "Rear Driver side Blower Up Down";
CM_ SG_ 158 ATS_DATC_RrDrModeSet "Rear Driver side Mode Set";
CM_ SG_ 158 ATS_DATC_FrDrModeSet "Front Driver side Mode Set";
CM_ SG_ 158 ATS_DATC_RrOnOffSet "Rear Climate On/Off Set";
CM_ SG_ 158 ATS_DATC_IntakeSet "Intake Set";
CM_ SG_ 158 ATS_DATC_OffReq "Front Climate Off Set";
CM_ SG_ 158 ATS_DATC_FrDrAutoSet "Front Driver side Auto Set";
CM_ SG_ 158 ATS_DATC_FrPsTempUpDn "Front Passenger side Temp Up Down";
CM_ SG_ 158 ATS_DATC_FrDefog "Front Defog set";
CM_ SG_ 158 ATS_DATC_RrSyncSet "Rear Sync Set";
CM_ SG_ 158 ATS_DATC_AcSet "Ac Set";
CM_ SG_ 158 ATS_DATC_AirCleaningSet "AirCleaning Set";
CM_ SG_ 158 ATS_DATC_FrDrBlowerUpDn "Front Driver Blower Up Down";
CM_ SG_ 158 ATS_DATC_FrDrTempUpDn "Front Driver side Temp Up Down";
CM_ SG_ 158 ATS_DATC_RrDrAutoSet "Rear Driver side Auto Set";
CM_ BO_ 1247 "[PE] Periodic and On Event";
CM_ SG_ 1247 Navi_ParkingLot "Parking Lot Information";
CM_ SG_ 1247 Navi_AirConditionWarning "this signal describe the circumstance and window state.";
CM_ SG_ 1247 Navi_AirConditionType "bit1 : Odour(On : 1, Off : 0)
bit2 : Tunnel(On : 1, Off : 0)
bit3 ~ 5 : Reserved";
CM_ BO_ 1240 "[PE] Periodic and On Event";
CM_ SG_ 1240 HU_DistanceUnit "Request to set CLU Distance Unit";
CM_ SG_ 1240 HU_MicActivity "HU send this signal to eCall for MIC using status.
eCall unit stop the diagonosis when received 0x1:Activated from HU
Otherwise, eCall unit keep diagnosis every 1 sec. and HU can not use MIC";
CM_ SG_ 1240 CF_HU_GPSFlt "Information of GPS Fault 

0x0: Normal
0x1 : Fault operation
0x2 : Reserved
0x3:Invalid";
CM_ SG_ 1240 AVN_RSPA_CancelInput "Request Signal to cancel RSPA function";
CM_ SG_ 1240 AVN_RSPA_Disp_Rdy "Signal to inform RSPA of AVN's display ready status
(RSPA È­¸é Ç¥½Ã °¡´É/ºÒ°¡´É »óÅÂ¸¦ ¾Ë¸®±â À§ÇÑ ½ÅÈ£)";
CM_ SG_ 1240 CF_AVN_ProfileIDRValue "This signal is User ID value in H/Unit.";
CM_ SG_ 1240 HazardFromHUSVM "This signal is for Hazard control";
CM_ SG_ 1240 OMUOSMirCtrl "This signal is for the OutSide Mirror Control (Fold or Unfold)";
CM_ SG_ 1240 OTAUIStatus "Information of the status of Head Unit";
CM_ SG_ 1240 C_TeleActiveStatus "This signal is for check TMS active status";
CM_ SG_ 1240 HU_AliveStatus "Information of the status of Head Unit
0x00 : Headunit is booting so, Headunit cant display any state
0x01 : Headunit is normal state, Headunit could display according to MM CAN  command.
0x02 : Headunit is doing their internal process, so Headunit cant communicate with other node.
For CLU/SCC/eCall
-AVN System transmission signal";
CM_ SG_ 1240 HU_RTCCheck "Checking whether RTC of AVN and HCU is operationg normally.";
CM_ BO_ 2424580353 "[PE] Periodic and On Event";
CM_ SG_ 2424580353 DATC_Crc12Val "DATC_CyclicRedundancyCheck12Value";
CM_ SG_ 2424580353 DATC_AlvCnt12Val "DATC_AliveCounter12Value";
CM_ SG_ 2424580353 DATC_StrWhlHtrSwReq "DATC_SteeringWheelHeaterSwitchRequest";
CM_ SG_ 2424580353 DATC_FRStHtrSwReq "DATC_FrontRightSeatHeaterSwitchRequest";
CM_ SG_ 2424580353 DATC_FRStVentSwReq "DATC_FrontRightSeatVentilationSwitchRequest";
CM_ SG_ 2424580353 DATC_RrDefSw "Rear Defog Switch";
CM_ SG_ 2424580353 DATC_FLStOpReq "DATC_FrontLeftSeatOperationRequest";
CM_ SG_ 2424580353 DATC_FRStOpReq "DATC_FrontRightSeatOperationRequest";
CM_ SG_ 2424580353 DATC_FLStHtrSwReq "DATC_FrontLeftSeatHeaterSwitchRequest";
CM_ SG_ 2424580353 DATC_FLStVentSwReq "DATC_FrontLefttSeatVentilationSwitchRequest";
CM_ SG_ 2424580353 DATC_FLStTmblrSwReq "DATC_FrontLefttSeatTumblerSwitchRequest";
CM_ SG_ 2424580353 DATC_FRStTmblrSwReq "DATC_FrontRightSeatTumblerSwitchRequest";
CM_ SG_ 2424580353 DATC_RRStHtrSwReq "DATC_RearRightSeatHeaterSwitchRequest";
CM_ SG_ 2424580353 DATC_RRStVentSwReq "DATC_RearRightSeatVentilationSwitchRequest";
CM_ SG_ 2424580353 DATC_RLStHtrSwReq "DATC_RearLeftSeatHeaterSwitchRequest";
CM_ SG_ 2424580353 DATC_RLStVentSwReq "DATC_RearLefttSeatVentilationSwitchRequest";
CM_ SG_ 2424580353 DATC_WdwClsReq "DATC_WindowCloseRequest";
CM_ SG_ 2424580353 DATC_RRSyncDis "DATC_RRSyncDisplay";
CM_ BO_ 171 "[EC] On Event and On Change";
CM_ SG_ 171 BLTN_CAM_UI_Mode_Tmt_Req "Built-in Cam UI Mode terminate request.";
CM_ SG_ 171 BLTN_CAM_Dis_Touch_BeepSound "Display Touch Beep Sound of valid space touch.";
CM_ SG_ 171 BLTN_CAM_PopUp_Req "Built-in Cam Operating and SD Card related Popup Request on HU Display.";
CM_ SG_ 171 BLTN_CAM_File_List_Renew "The Storage information is renewed inform to HU.";
CM_ SG_ 171 BLTN_CAM_Wifi_Pwd_Chg_State "The Response, when HU change Wifi Passowrd via SOME/IP";
CM_ BO_ 1253 "[EC] On Event and On Change";
CM_ SG_ 1253 SMK_Crc1Val "SMK_CyclicRedundancyCheck1Value";
CM_ SG_ 1253 SMK_AlvCnt1Val "SMK_AliveCounter1Value";
CM_ SG_ 1253 DoorLock_PsvDrLkReq "DoorLock_PassiveDoorLockRequest ##2G##SMK - SMKmsg01 - C_PassiveAccessLock";
CM_ SG_ 1253 DoorLock_PsvDrUnLkReq "DoorLock_PassiveDoorUnLockRequest ##2G##SMK - SMKmsg01 - C_PassiveAccessUnlock";
CM_ SG_ 1253 DoorLock_DrvDrPsvAcsReq "DoorLock_DriverDoorPassiveAccessRequest ##2G##SMK - SMKmsg01 - C_PassiveFrtDrv";
CM_ SG_ 1253 DoorLock_AsstDrPsvAcsReq "DoorLock_AssistDoorPassiveAccessRequest ##2G##SMK - SMKmsg01 - C_PassiveFrtAst";
CM_ SG_ 1253 DoorLock_TrnkTlgtPsvAcsReq "DoorLock_TrunkTailgatePassiveAccessRequest ##2G##SMK - SMKmsg01 - C_PassiveTrunkTg";
CM_ SG_ 1253 DoorLock_RrLftDrPsvAcsReq "DoorLock_RearLeftDoorPassiveAccessRequest ##2G##SMK - SMKmsg01 - C_PassiveRrDrv";
CM_ SG_ 1253 DoorLock_RrRtDrPsvAcsReq "DoorLock_RearRightDoorPassiveAccessRequest ##2G##SMK - SMKmsg01 - C_PassiveRrAst";
CM_ SG_ 1253 DoorLock_PsdPsvAcsReq "DoorLock_PowerSlidingDoorPassiveAccessRequest ##2G##SMK - SMKmsg01 - C_PassivePSD";
CM_ SG_ 1253 RSPA_DigitalKeyAuth "2G##SMK - SMKmsg01 - C_RSPADigitalKeyAuth";
CM_ SG_ 1253 Auth_Method "Authentication_Request ##2G##SMK - SMKmsg01 -C_SMK_AuthMethod";
CM_ SG_ 1253 DoorLock_StrgbxPsvAcsReq "DoorLock_StorageBoxPassiveAccessRequest";
CM_ BO_ 1252 "[EC] On Event and On Change";
CM_ SG_ 1252 RKE_Crc1Val "RKE_CyclicRedundancyCheck1Value";
CM_ SG_ 1252 RKE_AlvCnt1Val "RKE_AliveCounter1Value";
CM_ SG_ 1252 RKE_BtnReq "RemoteKey_ButtonRequest ##2G##BCM - BCMmsg01 - C_RKECmd";
CM_ SG_ 1252 RKE_PsdBtnReq "RemoteKey_PowerSlindingDoorButtonRequest ##2G##BCM - BCMmsg01 - C_RKEPSDCmd";
CM_ SG_ 1252 RKE_WdwUpDnReq "RemoteKey_WindowUpDownRequest ##2G##BCM - BCMmsg01 - C_WdwComfortCMDBCM";
CM_ SG_ 1252 RKE_TrnkTlgtBtnReq "RemoteKey_Trunk/TailgateButtonRequest ##2G##BCM - BCMmsg01 - C_TailgateTrunkRKECMD";
CM_ SG_ 1252 RKE_ID "RemoteKey_ID ##2G##BCM - BCMmsg01 - C_BCMRKEID";
CM_ BO_ 1251 "[EC] On Event and On Change";
CM_ BO_ 172 "[EC] On Event and On Change";
CM_ SG_ 172 BLTN_CAM_FR_VerPos_NvalueSet "Front Camera Vertical position setting value.";
CM_ SG_ 172 BLTN_CAM_AppNoti_PEV_NvalueSet "Parked Event notification to Connectivity Phone App. On/Off";
CM_ SG_ 172 BLTN_CAM_WiFi_AutoOn_NvalueSet "Wifi On/Off User setting";
CM_ SG_ 172 BLTN_CAM_StoProp_NvalueSet "Propotion of built-in Cam SD card Propotion set of the Recording Categories";
CM_ SG_ 172 CF_AVN_BLTN_CAM_USMReset "Buit-in Cam USM Reset Request.";
CM_ SG_ 172 CF_AVN_BLTN_CAM_RecReset "Buit-in Cam format(all file delete/Reset) Request.";
CM_ SG_ 172 BLTN_CAM_File_DEL_CPY_Cmd "Buit-in Cam operation control of copying and deleting.";
CM_ SG_ 172 BLTN_CAM_LVDS_Mode_Cmd "This Signal is for LVDS output commend to BLTN_CAM";
CM_ SG_ 172 HU_BLTN_CAM_Disp_Touch_Pos_X "X position of touch of display when BLTN-in CAM Engineer mode in";
CM_ SG_ 172 HU_BLTN_CAM_Disp_Touch_Pos_Y "Y position of touch of display when BLTN-in CAM Engineer mode in";
CM_ SG_ 172 MEV_Rec_Req "0x1(On) : MEV Record Request.";
CM_ SG_ 172 BLTN_CAM_RR_VerPos_NvalueSet "Rear Camera Vertical position setting value.";
CM_ SG_ 172 TML_Rec_Req "0x1 : Start Request, 0x2 : End Request";
CM_ SG_ 172 BLTN_CAM_SD_Card_UnMt_Mt_Req "0x0(Default), 0x1(UnMount Request), 0x2(Mount Request), 0x3(Invalid)";
CM_ BO_ 2227254529 "[P] Periodic";
CM_ SG_ 2227254529 BAT_Crc1Val "BAT_CyclicRedundancyCheck1Value";
CM_ SG_ 2227254529 BAT_AlvCnt1Val "BAT_AliveCounter1Value";
CM_ SG_ 2227254529 BAT_CurrVal "BAT_CurrentValue";
CM_ SG_ 2227254529 BAT_SocVal "BAT_StateOfChargeValue";
CM_ SG_ 2227254529 BAT_VoltVal "BAT_VoltageValue";
CM_ SG_ 2227254529 BAT_AuxBattOpt "12V Battery Option Value(LFP 12V Battery)";
CM_ BO_ 2227254530 "[P] Periodic";
CM_ SG_ 2227254530 BAT_TempVal "BAT_TemperatureValue";
CM_ SG_ 2227254530 BAT_SohVal "BAT_StateOfHealthValue";
CM_ SG_ 2227254530 BAT_SnsrInvldSta "BAT_SensorInvalidStatus";
CM_ SG_ 2227254530 BAT_SofVal "BAT_StateOfFunctionValue";
CM_ SG_ 2227254530 BAT_RspErrSta "BAT_ResponseErrorStatus";
CM_ SG_ 2227254530 BAT_CapacityVal "12V Battery Capacity Value";
CM_ SG_ 2227254530 BAT_SocErrSta "BAT_SoCErrorStatus";
CM_ BO_ 1266 "[PE] Periodic and On Event";
CM_ SG_ 1266 HU_LanguageInfo "Information for System Language (for Display Font)";
CM_ SG_ 1266 HU_MuteStatus "Information for System Mute Display";
CM_ SG_ 1266 HU_WelcomeReady "H/U playback ready signal to play welcome/goodbye animation video.";
CM_ SG_ 1266 HU_UsmSupport "Information whether HU can support USM or not";
CM_ SG_ 1266 HU_NaviStatus "Information for Navigation Status (Booting, Normal Operation, No SD card)
-AVN NAVI Transmission Signal";
CM_ SG_ 1266 HU_NaviDisp "Information for Navi Display status on Front Monitor";
CM_ SG_ 1266 HU_BVM_Display_Message "BVM Operation Message";
CM_ SG_ 1266 HU_SVM_View_Display "BVM View display to cluster";
CM_ SG_ 1266 HU_NaviCamSettingStatus "Information for Navi Camera alert setting status

+ Bit-coded field (On 1, Off 0)
   - bit 0 : Fixed Camera
   - bit 1 : Signal/Speed Violation Camera
   - bit 2 : Movable Camera
   - bit 3 : User Registration Fixed Camera
   - bit 4 : User Registration Signal/Speed Violation Camera
   - bit 5~6 : Reserved
-AVN NAVI Transmission Signal";
CM_ SG_ 1266 HU_EVSupport "Notification whether EV function support or not.";
CM_ SG_ 1266 HU_AutoBrightState_New "HU Display Brightness State(When automatically adjusted)";
CM_ SG_ 1266 HU_VolumeStatus "Information for AVN Volume";
CM_ BO_ 1267 "[PE] Periodic and On Event";
CM_ SG_ 1267 RSELockOnOff "Command for RSE Lock Requst from Head Unit";
CM_ SG_ 1267 HU_ClimateScrnState "AVNT Climate screen state";
CM_ SG_ 1267 HU_Graphreset_Info "Command for Hybrid Vehicle Fuel Economy Graph Reset Information
-Transmitting to Cluster when drivers agree 'Graph Reset'
-Keep the Value of Avergae Fuel Consumption and Line on the Graph";
CM_ SG_ 1267 HU_VRActivity "Information for Acitivity of VR (For All area)";
CM_ SG_ 1267 HU_DATC_AirQuality_Info "AirQuality Information";
CM_ BO_ 191 "[PE] Periodic and On Event";
CM_ SG_ 191 RL_SHVU_DTCdisplay "0x00: DTC is not exist(Fail is not exist)/0x01:IGN2 Fuse Open Detection/0x02:Switch Input Detection at Same Time/0x03:NTC/Heating wire Open Detection/0x04:NTC+/NTC- Terminal Short Detection/0x05:NTC+/Heater+ Terminal Short Detection/0x06:NTC+/Heater-, Heater+/Heater-, Heater+/NTC- Terminal Short Detection/0x07:NTC+/Heater- Wiring Short Detection/0x08:NTC+/Heater-, Heater+/Heater-, Heater+/NTC- Wiring Short Detection/0x09:Target Temperature Dissatisfied/0x0A:Blower+/Blower- Short, Blower+/Blower Speed, Blower-/Blower Speed Wiring Short Detection/0x0B:Blower+/Blower RPM, Blower-/Blower RPM, Blower Speed/Blower RPM Short Detection/0x0C:Blower+, Blower-, Blower Speed Signal open Detection/0x0D:Blower RPM signal Open Detection/0x0E~0xFD:Unused/0xFE:No Display/0xFF:Invalid";
CM_ SG_ 191 RL_SHVU_DiagMode "0x0:Default/0x1:DTC Mode/0x2:Normal Mode/0x3:Invalid";
CM_ BO_ 1264 "[PE] Periodic and On Event";
CM_ SG_ 1264 HU_TimeSetting "Information for current time setting";
CM_ SG_ 1264 HU_DisplayMinute "Information for time display in Minute unit";
CM_ SG_ 1264 HU_Status "Information for H/U status
Transmitted on H/U status changing";
CM_ SG_ 1264 HU_DisplaySecond "Information for time display in Second unit";
CM_ SG_ 1264 HU_DisplayMonth "Information for Month";
CM_ SG_ 1264 HU_DisplayYear1 "Information for Year (XXOO)
XX : HU_DisplayYear1
OO: HU_DisplayYear2";
CM_ SG_ 1264 HU_DisplayYear2 "Information for Year (XXOO)
XX : HU_DisplayYear1
OO: HU_DisplayYear2";
CM_ SG_ 1264 HU_DisplayDay "Information for Day";
CM_ SG_ 1264 HU_AM_PM_INFO "Information for AM/PM";
CM_ SG_ 1264 HU_TimeFormat "Information for time format
Digital CLOCK only";
CM_ SG_ 1264 HU_DisplayHour "Information for time display in Hour unit";
CM_ BO_ 1265 "[PE] Periodic and On Event";
CM_ SG_ 1265 HU_IG3_Request "IG3 wake up and sleep request for EV/PHEV";
CM_ SG_ 1265 HU_Background "HU Backgound image info";
CM_ SG_ 1265 ccIC_HUD_PbackSta "Status signal for HUD interoperation with IMS";
CM_ SG_ 1265 HU_BackgroundFadeInOut "HU Background Fade in/out info - (HEX * Factor) %";
CM_ SG_ 1265 OMUOSMirCtrl_Vr "This signal is for the OutSide Mirror Control (Fold or Unfold)";
CM_ BO_ 2328016132 "[P] Periodic";
CM_ SG_ 2328016132 VCU_LowSocDispPcVal "VCU_LowSocDisplayPercentValue";
CM_ SG_ 2328016132 VCU_DteSocBasedVal "VCU_DteSocBasedValue";
CM_ SG_ 2328016132 VCU_InstFuelEcoVal_Per100km "VCU_InstantFuelEconomy(kWh/100km) ##2G##VCU - VCU5 - CR_Vcu_FuelEco_KP100km";
CM_ SG_ 2328016132 VCU_InstFuelEcoVal_PerkWh "VCU_InstantFuelEconomyValue_(km/kWh) ##2G##VCU - VCU5 - CR_Vcu_FuelEco_KPK";
CM_ SG_ 2328016132 VCU_CO2RdcTripDistVal "VCU_CO2ReductionTripDistanceValue ##2G##VCU - VCU4 - CF_Vcu_CO2RdcTripDist";
CM_ SG_ 2328016132 VCU_CO2RdcVal "VCU_CO2ReductionValue ##2G##VCU - VCU4 - CF_Vcu_CO2Rdc";
CM_ SG_ 2328016132 VCU_StopCtrlWarnMsgSta "i-Pedal Warning Message Status";
CM_ SG_ 2328016132 VCU_DrvModeDefault "Drive Mode(Default Mode) Value for Cluster Display(EV)";
CM_ SG_ 2328016132 VCU_DrvModeLast "This signal is the drive mode that needs to maintain on restart";
CM_ BO_ 1278 "[PE] Periodic and On Event";
CM_ SG_ 1278 HU_Type "Information for H/U Platform type
- Integrated AVN 1.0 use different value depends on development company (Mobis:0x68/LG:0x70)
- Integrated AVN 1.0 Mobis is developed based on Display Audio
- Integrated AVN 1.0 LG is developed based on Compact AVN

Information for China OPIO Platform
- 0xFC: China OPIO w/o CLU interface (most of phase1)
- 0xFD: China OPIO w/CLU interface (parts of phase1, phase2)

Information for Audio Platform Type
- 0x43 : Audio 4.0 Value";
CM_ SG_ 1278 HU_DistributeInfo "Region :Europe/North America/
Vehicle Type : RHD/LHD
Positionning information";
CM_ SG_ 1278 HU_OptionInfo "Information of H/U functions";
CM_ SG_ 1278 HU_NaviMapInfo "Information about map data  used in Navigation";
CM_ SG_ 1278 HU_NaviHandshakingSupport "This is a signal to send whether handshaking logic is applied related to Navigation's 'Map based ADAS' specification";
CM_ SG_ 1278 HU_AMP_EQVariant "Set EQ Variant for various vehicle cases.
During the AMP initializing process, This signal should be sent before AMP unmute.
This signal is only needed for models that have variant EQ for vehicle types. (Hatchback, Wagon, Hybrid etc..)
Models that doesn¡¯t have variant EQ for vehicle types shouldn¡¯t have this signal.";
CM_ SG_ 1278 HU_AdasSupport "Information about ADAS support
-Classify between General Map and Precise Map Transmission Function
-AVN System Transmission Signal";
CM_ SG_ 1278 HU_Navi_RspADASMapMsg "HU_ResponseADASMapMessage";
BA_DEF_ BO_  "DiagState" ENUM  "No","Yes";
BA_DEF_ BO_  "DiagResponse" ENUM  "No","Yes";
BA_DEF_ BO_  "DiagRequest" ENUM  "No","Yes";
BA_DEF_ BO_  "TpMessage" ENUM  "No","Yes";
BA_DEF_ BO_  "UsrMsgIDSforwardDeviation" INT 0 100;
BA_DEF_ BO_  "UsrMsgIDSbackwardDeviation" INT 50 1000;
BA_DEF_ BO_  "GenMsgCycleTime" INT 0 2000;
BA_DEF_ BO_  "GenMsgStartDelayTime" INT 0 2000;
BA_DEF_ BO_  "GenMsgSendType" ENUM  "Cyclic","NoMsgSendType";
BA_DEF_ BO_  "GenMsgCycleTimeFast" INT 0 500;
BA_DEF_ BO_  "GenMsgDelayTime" INT 0 20;
BA_DEF_ BO_  "GenMsgILSupport" ENUM  "No","Yes";
BA_DEF_ BO_  "GenMsgNrOfRepetition" INT 0 3;
BA_DEF_ BO_  "NmMessage" ENUM  "No","Yes";
BA_DEF_ BO_  "NWM-Botschaft" ENUM  "No","Yes";
BA_DEF_ BO_  "TpTxIndex" INT 0 65535;
BA_DEF_ BO_  "VFrameFormat" ENUM  "StandardCAN","ExtendedCAN","reserved","reserved","reserved","reserved","reserved","reserved","reserved","reserved","reserved","reserved","reserved","reserved","StandardCAN_FD","ExtendedCAN_FD";
BA_DEF_ SG_  "UserSigValidity" ENUM  "B+","ACC","IG","IG1","IG2","IG3","IG1 or IG2","IG1 or IG3","Undef";
BA_DEF_ SG_  "TimeoutValue" STRING ;
BA_DEF_ SG_  "UsrSigPurpose" ENUM  "Undef","FN","DIAG","DIAG(Req)","DIAG(Res)","DIAG(Phy)","DEV","CCP(Req)","CCP(Res)","NM","TP";
BA_DEF_ SG_  "GenSigStartValue" INT 0 1215752192;
BA_DEF_ SG_  "NetworkRequest" ENUM  "Yes","No";
BA_DEF_ SG_  "NetworkRequestHoldingTime" INT 0 65535;
BA_DEF_ SG_  "Description" STRING ;
BA_DEF_ SG_  "Version" STRING ;
BA_DEF_ SG_  "GenSigEnvVarType" ENUM  "Int","Float","Undef";
BA_DEF_ SG_  "GenSigSendType" ENUM  "Cyclic","OnWrite","OnWriteWithRepetition","OnChange","OnChangeWithRepetition","IfActive","IfActiveWithRepetition","NoSigSendType","OnChangeAndIfActive","OnChangeAndIfActiveWithRepetition";
BA_DEF_ SG_  "GwSigLatencyTime" INT 0 65536;
BA_DEF_ SG_  "GwSigMissingSourceType" ENUM  "Undef","OldValue","DefaultValue","InitialValue";
BA_DEF_ SG_  "NWM-WakeupAllowed" ENUM  "<n.a.>";
BA_DEF_ SG_  "RoutingFactor" INT 1 1215752192;
BA_DEF_ SG_  "SystemSignalLongSymbol" STRING ;
BA_DEF_REL_ BU_SG_REL_  "GenSigTimeoutTime" INT 0 7000;
BA_DEF_DEF_  "DiagState" "No";
BA_DEF_DEF_  "DiagResponse" "No";
BA_DEF_DEF_  "DiagRequest" "No";
BA_DEF_DEF_  "TpMessage" "No";
BA_DEF_DEF_  "UsrMsgIDSforwardDeviation" 10;
BA_DEF_DEF_  "UsrMsgIDSbackwardDeviation" 100;
BA_DEF_DEF_  "GenMsgCycleTime" 200;
BA_DEF_DEF_  "GenMsgStartDelayTime" 0;
BA_DEF_DEF_  "GenMsgSendType" "NoMsgSendType";
BA_DEF_DEF_  "GenMsgCycleTimeFast" 40;
BA_DEF_DEF_  "GenMsgDelayTime" 20;
BA_DEF_DEF_  "GenMsgILSupport" "Yes";
BA_DEF_DEF_  "GenMsgNrOfRepetition" 3;
BA_DEF_DEF_  "NmMessage" "No";
BA_DEF_DEF_  "NWM-Botschaft" "No";
BA_DEF_DEF_  "TpTxIndex" 0;
BA_DEF_DEF_  "VFrameFormat" "StandardCAN";
BA_DEF_DEF_  "UserSigValidity" "IG";
BA_DEF_DEF_  "TimeoutValue" "";
BA_DEF_DEF_  "UsrSigPurpose" "FN";
BA_DEF_DEF_  "GenSigStartValue" 0;
BA_DEF_DEF_  "NetworkRequest" "No";
BA_DEF_DEF_  "NetworkRequestHoldingTime" 0;
BA_DEF_DEF_  "Description" "";
BA_DEF_DEF_  "Version" "";
BA_DEF_DEF_  "GenSigEnvVarType" "Undef";
BA_DEF_DEF_  "GenSigSendType" "NoSigSendType";
BA_DEF_DEF_  "GwSigLatencyTime" 40;
BA_DEF_DEF_  "GwSigMissingSourceType" "Undef";
BA_DEF_DEF_  "NWM-WakeupAllowed" "<n.a.>";
BA_DEF_DEF_  "RoutingFactor" 1;
BA_DEF_DEF_REL_ "GenSigTimeoutTime" 500;
BA_DEF_DEF_  "SystemSignalLongSymbol" "";
BA_ "GenMsgCycleTime" BO_ 1218 0;
BA_ "VFrameFormat" BO_ 2323816451 1;
BA_ "GenMsgCycleTime" BO_ 2323816451 0;
BA_ "VFrameFormat" BO_ 2323816450 1;
BA_ "GenMsgCycleTime" BO_ 2323816450 0;
BA_ "VFrameFormat" BO_ 2323816449 1;
BA_ "GenMsgCycleTime" BO_ 2323816449 0;
BA_ "GenMsgCycleTime" BO_ 1227 0;
BA_ "VFrameFormat" BO_ 2323816452 1;
BA_ "GenMsgCycleTime" BO_ 2323816452 0;
BA_ "GenMsgCycleTime" BO_ 1237 0;
BA_ "GenMsgSendType" BO_ 1239 0;
BA_ "GenMsgCycleTime" BO_ 157 0;
BA_ "GenMsgCycleTime" BO_ 158 0;
BA_ "GenMsgSendType" BO_ 1247 0;
BA_ "GenMsgSendType" BO_ 1240 0;
BA_ "VFrameFormat" BO_ 2424580353 1;
BA_ "GenMsgSendType" BO_ 2424580353 0;
BA_ "GenMsgCycleTime" BO_ 171 0;
BA_ "GenMsgCycleTime" BO_ 1253 0;
BA_ "GenMsgCycleTime" BO_ 1252 0;
BA_ "GenMsgCycleTime" BO_ 1251 0;
BA_ "GenMsgCycleTime" BO_ 172 0;
BA_ "VFrameFormat" BO_ 2227254529 1;
BA_ "GenMsgNrOfRepetition" BO_ 2227254529 0;
BA_ "GenMsgCycleTimeFast" BO_ 2227254529 0;
BA_ "GenMsgCycleTime" BO_ 2227254529 50;
BA_ "GenMsgSendType" BO_ 2227254529 0;
BA_ "VFrameFormat" BO_ 2227254530 1;
BA_ "GenMsgNrOfRepetition" BO_ 2227254530 0;
BA_ "GenMsgCycleTimeFast" BO_ 2227254530 0;
BA_ "GenMsgCycleTime" BO_ 2227254530 50;
BA_ "GenMsgSendType" BO_ 2227254530 0;
BA_ "GenMsgCycleTime" BO_ 1266 1000;
BA_ "GenMsgSendType" BO_ 1266 0;
BA_ "GenMsgCycleTime" BO_ 1267 1000;
BA_ "GenMsgSendType" BO_ 1267 0;
BA_ "GenMsgSendType" BO_ 191 0;
BA_ "GenMsgCycleTime" BO_ 1264 1000;
BA_ "GenMsgSendType" BO_ 1264 0;
BA_ "GenMsgCycleTime" BO_ 1265 1000;
BA_ "GenMsgSendType" BO_ 1265 0;
BA_ "VFrameFormat" BO_ 2328016132 1;
BA_ "GenMsgNrOfRepetition" BO_ 2328016132 0;
BA_ "GenMsgCycleTimeFast" BO_ 2328016132 0;
BA_ "GenMsgSendType" BO_ 2328016132 0;
BA_ "GenMsgCycleTime" BO_ 1278 2000;
BA_ "GenMsgSendType" BO_ 1278 0;
BA_ "Version" SG_ 1218 C_AVN_PTGHeightNValueSet "19.02.07";
BA_ "UserSigValidity" SG_ 1218 C_AVN_PTGHeightNValueSet 3;
BA_ "GenSigSendType" SG_ 1218 C_AVN_PTGHeightNValueSet 4;
BA_ "Description" SG_ 1218 C_AVN_PTGHeightNValueSet "18.08.09_";
BA_ "Version" SG_ 1218 CF_AVN_SCCMLReset "18.09.04";
BA_ "UserSigValidity" SG_ 1218 CF_AVN_SCCMLReset 3;
BA_ "GenSigSendType" SG_ 1218 CF_AVN_SCCMLReset 4;
BA_ "Description" SG_ 1218 CF_AVN_SCCMLReset "18.08.09_";
BA_ "Version" SG_ 1218 C_TgltAwayCloseNValue "19.01.10";
BA_ "UserSigValidity" SG_ 1218 C_TgltAwayCloseNValue 3;
BA_ "GenSigSendType" SG_ 1218 C_TgltAwayCloseNValue 4;
BA_ "Description" SG_ 1218 C_TgltAwayCloseNValue "USM Request for Tailgate Away Close";
BA_ "Version" SG_ 1218 C_HAnBNValueSet "18.09.04";
BA_ "UserSigValidity" SG_ 1218 C_HAnBNValueSet 3;
BA_ "GenSigSendType" SG_ 1218 C_HAnBNValueSet 4;
BA_ "Description" SG_ 1218 C_HAnBNValueSet "18.08.09_";
BA_ "Version" SG_ 1218 CF_AVN_RrSeatRemindNValueSet "18.09.04";
BA_ "UserSigValidity" SG_ 1218 CF_AVN_RrSeatRemindNValueSet 3;
BA_ "GenSigSendType" SG_ 1218 CF_AVN_RrSeatRemindNValueSet 4;
BA_ "Description" SG_ 1218 CF_AVN_RrSeatRemindNValueSet "18.08.09_";
BA_ "Version" SG_ 1218 CF_AVN_DSWNValueSet "18.09.04";
BA_ "UserSigValidity" SG_ 1218 CF_AVN_DSWNValueSet 3;
BA_ "GenSigSendType" SG_ 1218 CF_AVN_DSWNValueSet 4;
BA_ "Description" SG_ 1218 CF_AVN_DSWNValueSet "18.08.09_";
BA_ "Version" SG_ 1218 CF_AVN_RRPSU_RLNValueSet "18.09.04";
BA_ "UserSigValidity" SG_ 1218 CF_AVN_RRPSU_RLNValueSet 3;
BA_ "GenSigSendType" SG_ 1218 CF_AVN_RRPSU_RLNValueSet 4;
BA_ "Description" SG_ 1218 CF_AVN_RRPSU_RLNValueSet "18.08.09_";
BA_ "Version" SG_ 1218 CF_AVN_APSUNValueSet "18.09.04";
BA_ "UserSigValidity" SG_ 1218 CF_AVN_APSUNValueSet 3;
BA_ "GenSigSendType" SG_ 1218 CF_AVN_APSUNValueSet 4;
BA_ "Description" SG_ 1218 CF_AVN_APSUNValueSet "18.08.09_";
BA_ "Version" SG_ 1218 CF_AVN_NCC_CameraNValueSet "18.09.04";
BA_ "UserSigValidity" SG_ 1218 CF_AVN_NCC_CameraNValueSet 3;
BA_ "GenSigSendType" SG_ 1218 CF_AVN_NCC_CameraNValueSet 4;
BA_ "Description" SG_ 1218 CF_AVN_NCC_CameraNValueSet "18.08.09_";
BA_ "Version" SG_ 1218 CF_AVN_RRPSU_RRNValueSet "18.09.04";
BA_ "UserSigValidity" SG_ 1218 CF_AVN_RRPSU_RRNValueSet 3;
BA_ "GenSigSendType" SG_ 1218 CF_AVN_RRPSU_RRNValueSet 4;
BA_ "Description" SG_ 1218 CF_AVN_RRPSU_RRNValueSet "18.08.09_";
BA_ "Version" SG_ 1218 CF_AVN_HtBlcAstNValueSet "18.09.04";
BA_ "UserSigValidity" SG_ 1218 CF_AVN_HtBlcAstNValueSet 3;
BA_ "GenSigSendType" SG_ 1218 CF_AVN_HtBlcAstNValueSet 4;
BA_ "Description" SG_ 1218 CF_AVN_HtBlcAstNValueSet "18.08.09_";
BA_ "Version" SG_ 1218 CF_AVN_HtBlcDrvNValueSet "18.09.04";
BA_ "UserSigValidity" SG_ 1218 CF_AVN_HtBlcDrvNValueSet 3;
BA_ "GenSigSendType" SG_ 1218 CF_AVN_HtBlcDrvNValueSet 4;
BA_ "Description" SG_ 1218 CF_AVN_HtBlcDrvNValueSet "18.08.09_";
BA_ "Version" SG_ 1218 CF_AVN_SCCModeNValueSet "18.12.03";
BA_ "UserSigValidity" SG_ 1218 CF_AVN_SCCModeNValueSet 3;
BA_ "GenSigStartValue" SG_ 1218 CF_AVN_SCCModeNValueSet 3;
BA_ "GenSigSendType" SG_ 1218 CF_AVN_SCCModeNValueSet 4;
BA_ "Description" SG_ 1218 CF_AVN_SCCModeNValueSet "18.12.03_";
BA_ "Version" SG_ 1218 CF_AVN_SCCMLChar1Set "19.11.05";
BA_ "UserSigValidity" SG_ 1218 CF_AVN_SCCMLChar1Set 3;
BA_ "GenSigSendType" SG_ 1218 CF_AVN_SCCMLChar1Set 4;
BA_ "Version" SG_ 1218 CF_AVN_UIPNValueSet "18.10.06";
BA_ "UserSigValidity" SG_ 1218 CF_AVN_UIPNValueSet 3;
BA_ "GenSigSendType" SG_ 1218 CF_AVN_UIPNValueSet 4;
BA_ "Description" SG_ 1218 CF_AVN_UIPNValueSet "18.10.01_";
BA_ "Version" SG_ 1218 CF_AVN_SCCMLChar2Set "19.11.05";
BA_ "UserSigValidity" SG_ 1218 CF_AVN_SCCMLChar2Set 3;
BA_ "GenSigSendType" SG_ 1218 CF_AVN_SCCMLChar2Set 4;
BA_ "Version" SG_ 1218 CF_AVN_SCCMLChar3Set "19.11.05";
BA_ "UserSigValidity" SG_ 1218 CF_AVN_SCCMLChar3Set 3;
BA_ "GenSigSendType" SG_ 1218 CF_AVN_SCCMLChar3Set 4;
BA_ "Version" SG_ 1218 CF_AVN_HDALCFuncNValueSet "18.09.04";
BA_ "UserSigValidity" SG_ 1218 CF_AVN_HDALCFuncNValueSet 3;
BA_ "GenSigSendType" SG_ 1218 CF_AVN_HDALCFuncNValueSet 4;
BA_ "Description" SG_ 1218 CF_AVN_HDALCFuncNValueSet "18.08.09_";
BA_ "Version" SG_ 2323816450 HU_CDMOpenCmd_Copy_1 "20.09.00";
BA_ "UserSigValidity" SG_ 2323816450 HU_CDMOpenCmd_Copy_1 7;
BA_ "GenSigSendType" SG_ 2323816450 HU_CDMOpenCmd_Copy_1 4;
BA_ "Description" SG_ 2323816450 HU_CDMOpenCmd_Copy_1 "Command for CDM open/close";
BA_ "Version" SG_ 2323816450 HU_StrgWhlHeatingSet_CCS_Copy "21.05.02";
BA_ "UserSigValidity" SG_ 2323816450 HU_StrgWhlHeatingSet_CCS_Copy 0;
BA_ "GenSigStartValue" SG_ 2323816450 HU_StrgWhlHeatingSet_CCS_Copy 7;
BA_ "GenSigSendType" SG_ 2323816450 HU_StrgWhlHeatingSet_CCS_Copy 4;
BA_ "Description" SG_ 2323816450 HU_StrgWhlHeatingSet_CCS_Copy "steering wheel heating control by step1/2";
BA_ "Version" SG_ 2323816450 FrunkCtrlReq "22.03.02";
BA_ "NetworkRequestHoldingTime" SG_ 2323816450 FrunkCtrlReq 2000;
BA_ "NetworkRequest" SG_ 2323816450 FrunkCtrlReq 0;
BA_ "UserSigValidity" SG_ 2323816450 FrunkCtrlReq 0;
BA_ "GenSigSendType" SG_ 2323816450 FrunkCtrlReq 4;
BA_ "Description" SG_ 2323816450 FrunkCtrlReq "This signal is request for controling Frunk.";
BA_ "Version" SG_ 2323816450 C_EsyAcsProfileID_CCU "20.09.00";
BA_ "UserSigValidity" SG_ 2323816450 C_EsyAcsProfileID_CCU 0;
BA_ "GenSigSendType" SG_ 2323816450 C_EsyAcsProfileID_CCU 4;
BA_ "Version" SG_ 2323816449 C_CtrlDrLockRlyCCS_Copy_2 "20.08.07";
BA_ "NetworkRequestHoldingTime" SG_ 2323816449 C_CtrlDrLockRlyCCS_Copy_2 2000;
BA_ "NetworkRequest" SG_ 2323816449 C_CtrlDrLockRlyCCS_Copy_2 0;
BA_ "UserSigValidity" SG_ 2323816449 C_CtrlDrLockRlyCCS_Copy_2 0;
BA_ "GenSigSendType" SG_ 2323816449 C_CtrlDrLockRlyCCS_Copy_2 4;
BA_ "Version" SG_ 2323816449 C_TeleHeatingCmdIBOX_Copy_2 "20.08.07";
BA_ "NetworkRequestHoldingTime" SG_ 2323816449 C_TeleHeatingCmdIBOX_Copy_2 2000;
BA_ "NetworkRequest" SG_ 2323816449 C_TeleHeatingCmdIBOX_Copy_2 0;
BA_ "UserSigValidity" SG_ 2323816449 C_TeleHeatingCmdIBOX_Copy_2 0;
BA_ "GenSigStartValue" SG_ 2323816449 C_TeleHeatingCmdIBOX_Copy_2 3;
BA_ "GenSigSendType" SG_ 2323816449 C_TeleHeatingCmdIBOX_Copy_2 4;
BA_ "Version" SG_ 2323816449 C_TeleStrgWhlHeatingCmdIBOX_Copy "20.08.07";
BA_ "NetworkRequestHoldingTime" SG_ 2323816449 C_TeleStrgWhlHeatingCmdIBOX_Copy 2000;
BA_ "NetworkRequest" SG_ 2323816449 C_TeleStrgWhlHeatingCmdIBOX_Copy 0;
BA_ "UserSigValidity" SG_ 2323816449 C_TeleStrgWhlHeatingCmdIBOX_Copy 0;
BA_ "GenSigStartValue" SG_ 2323816449 C_TeleStrgWhlHeatingCmdIBOX_Copy 3;
BA_ "GenSigSendType" SG_ 2323816449 C_TeleStrgWhlHeatingCmdIBOX_Copy 4;
BA_ "SystemSignalLongSymbol" SG_ 2323816449 C_TeleStrgWhlHeatingCmdIBOX_Copy "C_TeleStrgWhlHeatingCmdIBOX_Copy_2";
BA_ "Version" SG_ 2323816449 C_TeleDefoggerHeatingCmdIBOX_Cop "20.08.07";
BA_ "NetworkRequestHoldingTime" SG_ 2323816449 C_TeleDefoggerHeatingCmdIBOX_Cop 2000;
BA_ "NetworkRequest" SG_ 2323816449 C_TeleDefoggerHeatingCmdIBOX_Cop 0;
BA_ "UserSigValidity" SG_ 2323816449 C_TeleDefoggerHeatingCmdIBOX_Cop 0;
BA_ "GenSigStartValue" SG_ 2323816449 C_TeleDefoggerHeatingCmdIBOX_Cop 3;
BA_ "GenSigSendType" SG_ 2323816449 C_TeleDefoggerHeatingCmdIBOX_Cop 4;
BA_ "SystemSignalLongSymbol" SG_ 2323816449 C_TeleDefoggerHeatingCmdIBOX_Cop "C_TeleDefoggerHeatingCmdIBOX_Copy_2";
BA_ "Version" SG_ 2323816449 C_TeleDrvSeatOpCmdIBOX_Copy_2 "20.08.07";
BA_ "UserSigValidity" SG_ 2323816449 C_TeleDrvSeatOpCmdIBOX_Copy_2 3;
BA_ "GenSigSendType" SG_ 2323816449 C_TeleDrvSeatOpCmdIBOX_Copy_2 4;
BA_ "Version" SG_ 2323816449 C_CtrlDrUnlockRlyCCS_Copy_2 "20.08.07";
BA_ "NetworkRequestHoldingTime" SG_ 2323816449 C_CtrlDrUnlockRlyCCS_Copy_2 2000;
BA_ "NetworkRequest" SG_ 2323816449 C_CtrlDrUnlockRlyCCS_Copy_2 0;
BA_ "UserSigValidity" SG_ 2323816449 C_CtrlDrUnlockRlyCCS_Copy_2 0;
BA_ "GenSigSendType" SG_ 2323816449 C_CtrlDrUnlockRlyCCS_Copy_2 4;
BA_ "Version" SG_ 2323816449 C_TeleAstSeatOpCmdIBOX_Copy_2 "20.08.07";
BA_ "UserSigValidity" SG_ 2323816449 C_TeleAstSeatOpCmdIBOX_Copy_2 3;
BA_ "GenSigSendType" SG_ 2323816449 C_TeleAstSeatOpCmdIBOX_Copy_2 4;
BA_ "Version" SG_ 2323816449 C_TeleRRSeatOpCmdIBOX_Copy_2 "20.08.07";
BA_ "UserSigValidity" SG_ 2323816449 C_TeleRRSeatOpCmdIBOX_Copy_2 3;
BA_ "GenSigSendType" SG_ 2323816449 C_TeleRRSeatOpCmdIBOX_Copy_2 4;
BA_ "Version" SG_ 2323816449 C_TeleRLSeatOpCmdIBOX_Copy_1 "20.08.07";
BA_ "UserSigValidity" SG_ 2323816449 C_TeleRLSeatOpCmdIBOX_Copy_1 3;
BA_ "GenSigSendType" SG_ 2323816449 C_TeleRLSeatOpCmdIBOX_Copy_1 4;
BA_ "Version" SG_ 2323816449 C_DrvWindowCmdAVN_Copy_2 "20.08.07";
BA_ "UserSigValidity" SG_ 2323816449 C_DrvWindowCmdAVN_Copy_2 0;
BA_ "GenSigStartValue" SG_ 2323816449 C_DrvWindowCmdAVN_Copy_2 15;
BA_ "GenSigSendType" SG_ 2323816449 C_DrvWindowCmdAVN_Copy_2 4;
BA_ "Version" SG_ 2323816449 C_HazardFromCCS_Copy_2 "20.08.07";
BA_ "NetworkRequestHoldingTime" SG_ 2323816449 C_HazardFromCCS_Copy_2 2000;
BA_ "NetworkRequest" SG_ 2323816449 C_HazardFromCCS_Copy_2 0;
BA_ "UserSigValidity" SG_ 2323816449 C_HazardFromCCS_Copy_2 0;
BA_ "GenSigSendType" SG_ 2323816449 C_HazardFromCCS_Copy_2 4;
BA_ "Version" SG_ 2323816449 C_AstWindowCmdAVN_Copy_2 "20.08.07";
BA_ "UserSigValidity" SG_ 2323816449 C_AstWindowCmdAVN_Copy_2 0;
BA_ "GenSigStartValue" SG_ 2323816449 C_AstWindowCmdAVN_Copy_2 15;
BA_ "GenSigSendType" SG_ 2323816449 C_AstWindowCmdAVN_Copy_2 4;
BA_ "Version" SG_ 2323816449 C_RRWindowCmdAVN_Copy_2 "20.08.07";
BA_ "UserSigValidity" SG_ 2323816449 C_RRWindowCmdAVN_Copy_2 0;
BA_ "GenSigStartValue" SG_ 2323816449 C_RRWindowCmdAVN_Copy_2 15;
BA_ "GenSigSendType" SG_ 2323816449 C_RRWindowCmdAVN_Copy_2 4;
BA_ "Version" SG_ 2323816449 C_RLWindowCmdAVN_Copy_2 "20.08.07";
BA_ "UserSigValidity" SG_ 2323816449 C_RLWindowCmdAVN_Copy_2 0;
BA_ "GenSigStartValue" SG_ 2323816449 C_RLWindowCmdAVN_Copy_2 15;
BA_ "GenSigSendType" SG_ 2323816449 C_RLWindowCmdAVN_Copy_2 4;
BA_ "Version" SG_ 2323816449 TailCtrlReq_Copy "20.08.07";
BA_ "UserSigValidity" SG_ 2323816449 TailCtrlReq_Copy 0;
BA_ "GenSigSendType" SG_ 2323816449 TailCtrlReq_Copy 4;
BA_ "Description" SG_ 2323816449 TailCtrlReq_Copy "This signal is for cotroling Tail lamp.";
BA_ "Version" SG_ 2323816449 HazardCtrlReq_Copy "20.08.07";
BA_ "UserSigValidity" SG_ 2323816449 HazardCtrlReq_Copy 0;
BA_ "GenSigSendType" SG_ 2323816449 HazardCtrlReq_Copy 4;
BA_ "Description" SG_ 2323816449 HazardCtrlReq_Copy "This signal is request for controling Hazard lamp.";
BA_ "Version" SG_ 2323816449 HU_DATC_AirCleaningSet_Copy_1 "20.08.07";
BA_ "UserSigValidity" SG_ 2323816449 HU_DATC_AirCleaningSet_Copy_1 3;
BA_ "GenSigStartValue" SG_ 2323816449 HU_DATC_AirCleaningSet_Copy_1 3;
BA_ "GenSigSendType" SG_ 2323816449 HU_DATC_AirCleaningSet_Copy_1 4;
BA_ "Version" SG_ 2323816449 C_PanicFromCCS_Copy_2 "20.08.07";
BA_ "NetworkRequestHoldingTime" SG_ 2323816449 C_PanicFromCCS_Copy_2 2000;
BA_ "NetworkRequest" SG_ 2323816449 C_PanicFromCCS_Copy_2 0;
BA_ "UserSigValidity" SG_ 2323816449 C_PanicFromCCS_Copy_2 0;
BA_ "GenSigSendType" SG_ 2323816449 C_PanicFromCCS_Copy_2 4;
BA_ "Version" SG_ 2323816449 C_TeleFrontHeatingCmdIBOX_Copy_1 "20.08.07";
BA_ "NetworkRequestHoldingTime" SG_ 2323816449 C_TeleFrontHeatingCmdIBOX_Copy_1 2000;
BA_ "NetworkRequest" SG_ 2323816449 C_TeleFrontHeatingCmdIBOX_Copy_1 0;
BA_ "UserSigValidity" SG_ 2323816449 C_TeleFrontHeatingCmdIBOX_Copy_1 0;
BA_ "GenSigStartValue" SG_ 2323816449 C_TeleFrontHeatingCmdIBOX_Copy_1 3;
BA_ "GenSigSendType" SG_ 2323816449 C_TeleFrontHeatingCmdIBOX_Copy_1 4;
BA_ "Description" SG_ 2323816449 C_TeleFrontHeatingCmdIBOX_Copy_1 "Command for Remote Heating (Front Window)";
BA_ "Version" SG_ 2323816449 RAC_AirCleaningCtrlReq_Copy_1 "20.09.00";
BA_ "UserSigValidity" SG_ 2323816449 RAC_AirCleaningCtrlReq_Copy_1 3;
BA_ "GenSigSendType" SG_ 2323816449 RAC_AirCleaningCtrlReq_Copy_1 4;
BA_ "Description" SG_ 2323816449 RAC_AirCleaningCtrlReq_Copy_1 "CCS Module(Telematics unit) transmits this signal to control the air cleaning when the remote air-condition is request.";
BA_ "Version" SG_ 2323816449 C_PreCrankReq_Copy "20.08.07";
BA_ "NetworkRequest" SG_ 2323816449 C_PreCrankReq_Copy 0;
BA_ "UserSigValidity" SG_ 2323816449 C_PreCrankReq_Copy 0;
BA_ "GenSigSendType" SG_ 2323816449 C_PreCrankReq_Copy 4;
BA_ "Version" SG_ 1227 DrvIMS_MemoryP1Req "17.11.00";
BA_ "NetworkRequestHoldingTime" SG_ 1227 DrvIMS_MemoryP1Req 5000;
BA_ "NetworkRequest" SG_ 1227 DrvIMS_MemoryP1Req 0;
BA_ "UserSigValidity" SG_ 1227 DrvIMS_MemoryP1Req 0;
BA_ "GenSigSendType" SG_ 1227 DrvIMS_MemoryP1Req 4;
BA_ "Description" SG_ 1227 DrvIMS_MemoryP1Req "-(Old)C_MEMP1CMD";
BA_ "Version" SG_ 1227 DrvIMS_PlyBckP2Req "17.11.00";
BA_ "NetworkRequestHoldingTime" SG_ 1227 DrvIMS_PlyBckP2Req 5000;
BA_ "NetworkRequest" SG_ 1227 DrvIMS_PlyBckP2Req 0;
BA_ "UserSigValidity" SG_ 1227 DrvIMS_PlyBckP2Req 0;
BA_ "GenSigSendType" SG_ 1227 DrvIMS_PlyBckP2Req 4;
BA_ "Version" SG_ 1227 DrvIMS_PlyBckP3Req "17.11.00";
BA_ "NetworkRequestHoldingTime" SG_ 1227 DrvIMS_PlyBckP3Req 5000;
BA_ "NetworkRequest" SG_ 1227 DrvIMS_PlyBckP3Req 0;
BA_ "UserSigValidity" SG_ 1227 DrvIMS_PlyBckP3Req 0;
BA_ "GenSigSendType" SG_ 1227 DrvIMS_PlyBckP3Req 4;
BA_ "Description" SG_ 1227 DrvIMS_PlyBckP3Req "PLAY IMS3";
BA_ "Version" SG_ 1227 DrvIMS_PlyBckStpReq "17.11.00";
BA_ "NetworkRequestHoldingTime" SG_ 1227 DrvIMS_PlyBckStpReq 5000;
BA_ "NetworkRequest" SG_ 1227 DrvIMS_PlyBckStpReq 0;
BA_ "UserSigValidity" SG_ 1227 DrvIMS_PlyBckStpReq 0;
BA_ "GenSigSendType" SG_ 1227 DrvIMS_PlyBckStpReq 4;
BA_ "Description" SG_ 1227 DrvIMS_PlyBckStpReq "This signal is used to stop during playback";
BA_ "Version" SG_ 1227 SmrtIMS_PlyBckReq "21.07.05";
BA_ "NetworkRequestHoldingTime" SG_ 1227 SmrtIMS_PlyBckReq 5000;
BA_ "NetworkRequest" SG_ 1227 SmrtIMS_PlyBckReq 0;
BA_ "UserSigValidity" SG_ 1227 SmrtIMS_PlyBckReq 0;
BA_ "GenSigSendType" SG_ 1227 SmrtIMS_PlyBckReq 4;
BA_ "Description" SG_ 1227 SmrtIMS_PlyBckReq "Signal for Health Care IMS Playback DB Number";
BA_ "Version" SG_ 1227 DrvIMS_MemoryP2Req "17.11.00";
BA_ "NetworkRequestHoldingTime" SG_ 1227 DrvIMS_MemoryP2Req 5000;
BA_ "NetworkRequest" SG_ 1227 DrvIMS_MemoryP2Req 0;
BA_ "UserSigValidity" SG_ 1227 DrvIMS_MemoryP2Req 0;
BA_ "GenSigSendType" SG_ 1227 DrvIMS_MemoryP2Req 4;
BA_ "Description" SG_ 1227 DrvIMS_MemoryP2Req "-(Old)C_MEMP2CMD";
BA_ "Version" SG_ 1227 PSM_IMSReq "21.02.02";
BA_ "NetworkRequestHoldingTime" SG_ 1227 PSM_IMSReq 5000;
BA_ "NetworkRequest" SG_ 1227 PSM_IMSReq 0;
BA_ "UserSigValidity" SG_ 1227 PSM_IMSReq 0;
BA_ "GenSigSendType" SG_ 1227 PSM_IMSReq 4;
BA_ "Description" SG_ 1227 PSM_IMSReq "IMS request";
BA_ "Version" SG_ 1227 SmrtIMS_ImgDBVal "17.11.00";
BA_ "NetworkRequestHoldingTime" SG_ 1227 SmrtIMS_ImgDBVal 5000;
BA_ "NetworkRequest" SG_ 1227 SmrtIMS_ImgDBVal 0;
BA_ "UserSigValidity" SG_ 1227 SmrtIMS_ImgDBVal 0;
BA_ "GenSigSendType" SG_ 1227 SmrtIMS_ImgDBVal 4;
BA_ "Description" SG_ 1227 SmrtIMS_ImgDBVal "-(Old)C_SmartIMSImageDB";
BA_ "Version" SG_ 1227 SmrtIMS_PlyBckStpReq "17.11.00";
BA_ "NetworkRequestHoldingTime" SG_ 1227 SmrtIMS_PlyBckStpReq 5000;
BA_ "NetworkRequest" SG_ 1227 SmrtIMS_PlyBckStpReq 0;
BA_ "UserSigValidity" SG_ 1227 SmrtIMS_PlyBckStpReq 0;
BA_ "GenSigSendType" SG_ 1227 SmrtIMS_PlyBckStpReq 4;
BA_ "Description" SG_ 1227 SmrtIMS_PlyBckStpReq "Health Care IMS On/Off Flag";
BA_ "Version" SG_ 1227 DrvIMS_MemoryP3Req "17.11.00";
BA_ "NetworkRequestHoldingTime" SG_ 1227 DrvIMS_MemoryP3Req 5000;
BA_ "NetworkRequest" SG_ 1227 DrvIMS_MemoryP3Req 0;
BA_ "UserSigValidity" SG_ 1227 DrvIMS_MemoryP3Req 0;
BA_ "GenSigSendType" SG_ 1227 DrvIMS_MemoryP3Req 4;
BA_ "Description" SG_ 1227 DrvIMS_MemoryP3Req "Memory IMS3";
BA_ "Version" SG_ 1227 SmrtIMS_EnterSwSta "17.11.00";
BA_ "NetworkRequestHoldingTime" SG_ 1227 SmrtIMS_EnterSwSta 5000;
BA_ "NetworkRequest" SG_ 1227 SmrtIMS_EnterSwSta 0;
BA_ "UserSigValidity" SG_ 1227 SmrtIMS_EnterSwSta 0;
BA_ "GenSigSendType" SG_ 1227 SmrtIMS_EnterSwSta 4;
BA_ "Description" SG_ 1227 SmrtIMS_EnterSwSta "-(Old)C_SmartIMSOn";
BA_ "Version" SG_ 1227 DrvIMS_BzrReq "17.11.00";
BA_ "NetworkRequestHoldingTime" SG_ 1227 DrvIMS_BzrReq 5000;
BA_ "NetworkRequest" SG_ 1227 DrvIMS_BzrReq 0;
BA_ "UserSigValidity" SG_ 1227 DrvIMS_BzrReq 0;
BA_ "GenSigSendType" SG_ 1227 DrvIMS_BzrReq 4;
BA_ "Description" SG_ 1227 DrvIMS_BzrReq "IMS ºÎÁ®À½À» Å¬·¯½ºÅÍ ½ºÇÇÄ¿¿¡¼­ Ãâ·ÂÇÏ±â À§ÇÑ ½Ã±×³Î";
BA_ "Version" SG_ 1227 DrvIMS_ErrConWmgDis "18.07.01";
BA_ "NetworkRequestHoldingTime" SG_ 1227 DrvIMS_ErrConWmgDis 5000;
BA_ "NetworkRequest" SG_ 1227 DrvIMS_ErrConWmgDis 0;
BA_ "UserSigValidity" SG_ 1227 DrvIMS_ErrConWmgDis 0;
BA_ "GenSigSendType" SG_ 1227 DrvIMS_ErrConWmgDis 4;
BA_ "Description" SG_ 1227 DrvIMS_ErrConWmgDis "IMS ±â¾ï/Àç»ý Á¶°Ç ¿¡·¯ Ãâ·Â ½Ã±×³Î";
BA_ "Version" SG_ 1227 PSM_DrvRlxReturn_Req "20.07.02";
BA_ "NetworkRequestHoldingTime" SG_ 1227 PSM_DrvRlxReturn_Req 5000;
BA_ "NetworkRequest" SG_ 1227 PSM_DrvRlxReturn_Req 0;
BA_ "UserSigValidity" SG_ 1227 PSM_DrvRlxReturn_Req 0;
BA_ "GenSigSendType" SG_ 1227 PSM_DrvRlxReturn_Req 4;
BA_ "Description" SG_ 1227 PSM_DrvRlxReturn_Req "one touch relax play and return";
BA_ "Version" SG_ 1227 Drv_AutoRlxWrngDis "21.06.10";
BA_ "NetworkRequestHoldingTime" SG_ 1227 Drv_AutoRlxWrngDis 5000;
BA_ "NetworkRequest" SG_ 1227 Drv_AutoRlxWrngDis 0;
BA_ "UserSigValidity" SG_ 1227 Drv_AutoRlxWrngDis 1;
BA_ "GenSigSendType" SG_ 1227 Drv_AutoRlxWrngDis 4;
BA_ "Version" SG_ 1227 DrvIMS_MemorySetEnaSta "17.11.00";
BA_ "NetworkRequestHoldingTime" SG_ 1227 DrvIMS_MemorySetEnaSta 5000;
BA_ "NetworkRequest" SG_ 1227 DrvIMS_MemorySetEnaSta 0;
BA_ "UserSigValidity" SG_ 1227 DrvIMS_MemorySetEnaSta 0;
BA_ "GenSigSendType" SG_ 1227 DrvIMS_MemorySetEnaSta 4;
BA_ "Description" SG_ 1227 DrvIMS_MemorySetEnaSta "-(Old)C_MEMENB";
BA_ "Version" SG_ 1227 DrvIMS_PlyBckP1Req "17.11.00";
BA_ "NetworkRequestHoldingTime" SG_ 1227 DrvIMS_PlyBckP1Req 5000;
BA_ "NetworkRequest" SG_ 1227 DrvIMS_PlyBckP1Req 0;
BA_ "UserSigValidity" SG_ 1227 DrvIMS_PlyBckP1Req 0;
BA_ "GenSigSendType" SG_ 1227 DrvIMS_PlyBckP1Req 4;
BA_ "Version" SG_ 1237 SWRC_Crc2Val "19.11.02";
BA_ "UserSigValidity" SG_ 1237 SWRC_Crc2Val 0;
BA_ "GenSigStartValue" SG_ 1237 SWRC_Crc2Val 255;
BA_ "GenSigSendType" SG_ 1237 SWRC_Crc2Val 4;
BA_ "Description" SG_ 1237 SWRC_Crc2Val "The data area for CRC calculation is based on the data length (DLC) of the message DB.

The CRC shall be calculated over the entire data block (excluding the CRC bytes) including the user data, alive counter and Data ID 

 

- CRC Polynomial (0x1D) , Ini";
BA_ "Version" SG_ 1237 SWRC_AlvCnt2Val "19.11.02";
BA_ "UserSigValidity" SG_ 1237 SWRC_AlvCnt2Val 0;
BA_ "GenSigSendType" SG_ 1237 SWRC_AlvCnt2Val 4;
BA_ "Description" SG_ 1237 SWRC_AlvCnt2Val "For the first transmission request for a data element the counter shall be initialized with 0 and shall be incremented by 1

for every subsequent send request. When the counter reaches the maximum value(0xE), then it shall restart with 0 for the next sen";
BA_ "Version" SG_ 1237 Audio_VolEncoderSta "19.11.02";
BA_ "NetworkRequestHoldingTime" SG_ 1237 Audio_VolEncoderSta 5000;
BA_ "NetworkRequest" SG_ 1237 Audio_VolEncoderSta 0;
BA_ "UserSigValidity" SG_ 1237 Audio_VolEncoderSta 0;
BA_ "GenSigSendType" SG_ 1237 Audio_VolEncoderSta 4;
BA_ "Description" SG_ 1237 Audio_VolEncoderSta "Audio Volume switch

MM-CAN Gateway needed";
BA_ "Version" SG_ 1237 Cluster_ScrlEncoderSta "19.11.02";
BA_ "NetworkRequestHoldingTime" SG_ 1237 Cluster_ScrlEncoderSta 5000;
BA_ "NetworkRequest" SG_ 1237 Cluster_ScrlEncoderSta 0;
BA_ "UserSigValidity" SG_ 1237 Cluster_ScrlEncoderSta 0;
BA_ "GenSigSendType" SG_ 1237 Cluster_ScrlEncoderSta 4;
BA_ "Description" SG_ 1237 Cluster_ScrlEncoderSta "Cluster Trip Switch";
BA_ "Version" SG_ 1239 HU_MKBD_BtnLEDCtr "19.07.05";
BA_ "UserSigValidity" SG_ 1239 HU_MKBD_BtnLEDCtr 0;
BA_ "GenSigStartValue" SG_ 1239 HU_MKBD_BtnLEDCtr 3;
BA_ "GenSigSendType" SG_ 1239 HU_MKBD_BtnLEDCtr 4;
BA_ "Description" SG_ 1239 HU_MKBD_BtnLEDCtr "MKBD Button LED Backlight control signal (Hidden Light Button)";
BA_ "Version" SG_ 1239 HU_ADMSettingState "21.01.07";
BA_ "NetworkRequestHoldingTime" SG_ 1239 HU_ADMSettingState 5000;
BA_ "NetworkRequest" SG_ 1239 HU_ADMSettingState 0;
BA_ "UserSigValidity" SG_ 1239 HU_ADMSettingState 0;
BA_ "GenSigSendType" SG_ 1239 HU_ADMSettingState 4;
BA_ "Description" SG_ 1239 HU_ADMSettingState "The signal transfers ADM Setting Value(On/Off) from HU to other module.";
BA_ "Version" SG_ 1239 HU_PwrState "22.05.02";
BA_ "UserSigValidity" SG_ 1239 HU_PwrState 0;
BA_ "GenSigSendType" SG_ 1239 HU_PwrState 4;
BA_ "Description" SG_ 1239 HU_PwrState "Information for the H/U power status



* Do not use HU_VehiclePwr (@HU_Car_PE_01) in new ECU or Logic related with HU power state";
BA_ "Version" SG_ 1239 HU_MKBD_ModeSwitch "20.12.04";
BA_ "UserSigValidity" SG_ 1239 HU_MKBD_ModeSwitch 1;
BA_ "GenSigStartValue" SG_ 1239 HU_MKBD_ModeSwitch 3;
BA_ "GenSigSendType" SG_ 1239 HU_MKBD_ModeSwitch 4;
BA_ "Description" SG_ 1239 HU_MKBD_ModeSwitch "This signal is used for the 'AVNT/Climate Switching Keyboard' to switch the display of buttons.";
BA_ "Version" SG_ 1239 HU_LCDState "22.05.02";
BA_ "UserSigValidity" SG_ 1239 HU_LCDState 0;
BA_ "GenSigSendType" SG_ 1239 HU_LCDState 4;
BA_ "Description" SG_ 1239 HU_LCDState "Information for H/U LCD (Monitor) On/Off Status";
BA_ "Version" SG_ 1239 HU_VehiclePwr "21.01.01";
BA_ "NetworkRequestHoldingTime" SG_ 1239 HU_VehiclePwr 5000;
BA_ "NetworkRequest" SG_ 1239 HU_VehiclePwr 0;
BA_ "UserSigValidity" SG_ 1239 HU_VehiclePwr 0;
BA_ "GenSigSendType" SG_ 1239 HU_VehiclePwr 4;
BA_ "Version" SG_ 1239 HU_BtnShowReq "19.11.01";
BA_ "NetworkRequestHoldingTime" SG_ 1239 HU_BtnShowReq 5000;
BA_ "NetworkRequest" SG_ 1239 HU_BtnShowReq 0;
BA_ "UserSigValidity" SG_ 1239 HU_BtnShowReq 0;
BA_ "GenSigStartValue" SG_ 1239 HU_BtnShowReq 7;
BA_ "GenSigSendType" SG_ 1239 HU_BtnShowReq 4;
BA_ "Description" SG_ 1239 HU_BtnShowReq "This signal indicates requesting turn on/off button light for H/Unit related buttons.";
BA_ "Version" SG_ 157 ATS_DATC_FrDrTempSetC "19.12.08";
BA_ "UserSigValidity" SG_ 157 ATS_DATC_FrDrTempSetC 3;
BA_ "GenSigStartValue" SG_ 157 ATS_DATC_FrDrTempSetC 255;
BA_ "GenSigSendType" SG_ 157 ATS_DATC_FrDrTempSetC 4;
BA_ "Description" SG_ 157 ATS_DATC_FrDrTempSetC "Àü¼® ¿îÀü¼® Ãø ¼³Á¤¿Âµµ°ª(¼·¾¾) ¼³Á¤";
BA_ "Version" SG_ 157 ATS_DATC_RrDrBlowerUpDn "19.12.08";
BA_ "UserSigValidity" SG_ 157 ATS_DATC_RrDrBlowerUpDn 3;
BA_ "GenSigSendType" SG_ 157 ATS_DATC_RrDrBlowerUpDn 4;
BA_ "Description" SG_ 157 ATS_DATC_RrDrBlowerUpDn "ÈÄ¼® ¿îÀü¼® Ãø ºí·Î¿ö Áõ°¨ ¼³Á¤";
BA_ "Version" SG_ 157 ATS_DATC_FrSyncSet "19.12.08";
BA_ "UserSigValidity" SG_ 157 ATS_DATC_FrSyncSet 3;
BA_ "GenSigSendType" SG_ 157 ATS_DATC_FrSyncSet 4;
BA_ "Description" SG_ 157 ATS_DATC_FrSyncSet "Àü¼® SYNC ¼³Á¤";
BA_ "Version" SG_ 157 ATS_DATC_RrDrTempSetC "19.12.08";
BA_ "UserSigValidity" SG_ 157 ATS_DATC_RrDrTempSetC 3;
BA_ "GenSigStartValue" SG_ 157 ATS_DATC_RrDrTempSetC 255;
BA_ "GenSigSendType" SG_ 157 ATS_DATC_RrDrTempSetC 4;
BA_ "Description" SG_ 157 ATS_DATC_RrDrTempSetC "ÈÄ¼® ¿îÀü¼® Ãø ¼³Á¤¿Âµµ°ª(¼·¾¾) ¼³Á¤";
BA_ "Version" SG_ 157 ATS_DATC_RrDrTempSetF "19.12.08";
BA_ "UserSigValidity" SG_ 157 ATS_DATC_RrDrTempSetF 3;
BA_ "GenSigStartValue" SG_ 157 ATS_DATC_RrDrTempSetF 255;
BA_ "GenSigSendType" SG_ 157 ATS_DATC_RrDrTempSetF 4;
BA_ "Description" SG_ 157 ATS_DATC_RrDrTempSetF "ÈÄ¼® ¿îÀü¼® Ãø ¼³Á¤¿Âµµ°ª(È­¾¾) ¼³Á¤";
BA_ "Version" SG_ 157 ATS_DATC_FrPsTempSetC "19.12.08";
BA_ "UserSigValidity" SG_ 157 ATS_DATC_FrPsTempSetC 3;
BA_ "GenSigStartValue" SG_ 157 ATS_DATC_FrPsTempSetC 255;
BA_ "GenSigSendType" SG_ 157 ATS_DATC_FrPsTempSetC 4;
BA_ "Description" SG_ 157 ATS_DATC_FrPsTempSetC "Àü¼® Á¶¼ö¼® Ãø ¼³Á¤¿Âµµ°ª(¼·¾¾) ¼³Á¤";
BA_ "Version" SG_ 157 ATS_DATC_FrPsTempSetF "19.12.08";
BA_ "UserSigValidity" SG_ 157 ATS_DATC_FrPsTempSetF 3;
BA_ "GenSigStartValue" SG_ 157 ATS_DATC_FrPsTempSetF 255;
BA_ "GenSigSendType" SG_ 157 ATS_DATC_FrPsTempSetF 4;
BA_ "Description" SG_ 157 ATS_DATC_FrPsTempSetF "Àü¼® Á¶¼ö¼® Ãø ¼³Á¤¿Âµµ°ª(È­¾¾) ¼³Á¤";
BA_ "Version" SG_ 157 ATS_DATC_FrDrTempSetF "19.12.08";
BA_ "UserSigValidity" SG_ 157 ATS_DATC_FrDrTempSetF 3;
BA_ "GenSigStartValue" SG_ 157 ATS_DATC_FrDrTempSetF 255;
BA_ "GenSigSendType" SG_ 157 ATS_DATC_FrDrTempSetF 4;
BA_ "Description" SG_ 157 ATS_DATC_FrDrTempSetF "Àü¼® ¿îÀü¼® Ãø ¼³Á¤¿Âµµ°ª(È­¾¾) ¼³Á¤";
BA_ "Version" SG_ 158 ATS_DATC_FrDrBlowerSet "19.12.08";
BA_ "UserSigValidity" SG_ 158 ATS_DATC_FrDrBlowerSet 3;
BA_ "GenSigStartValue" SG_ 158 ATS_DATC_FrDrBlowerSet 15;
BA_ "GenSigSendType" SG_ 158 ATS_DATC_FrDrBlowerSet 4;
BA_ "Description" SG_ 158 ATS_DATC_FrDrBlowerSet "Àü¼® ¿îÀü¼® Ãø ºí·Î¿ö ´Ü¼ö ¼³Á¤";
BA_ "Version" SG_ 158 ATS_DATC_RrDrTempUpDn "19.12.08";
BA_ "UserSigValidity" SG_ 158 ATS_DATC_RrDrTempUpDn 3;
BA_ "GenSigSendType" SG_ 158 ATS_DATC_RrDrTempUpDn 4;
BA_ "Description" SG_ 158 ATS_DATC_RrDrTempUpDn "ÈÄ¼® ¿îÀü¼® Ãø ¼³Á¤¿Âµµ Áõ°¨ ¼³Á¤";
BA_ "Version" SG_ 158 ATS_DATC_RrDrBlowerSet "19.12.08";
BA_ "UserSigValidity" SG_ 158 ATS_DATC_RrDrBlowerSet 3;
BA_ "GenSigStartValue" SG_ 158 ATS_DATC_RrDrBlowerSet 15;
BA_ "GenSigSendType" SG_ 158 ATS_DATC_RrDrBlowerSet 4;
BA_ "Description" SG_ 158 ATS_DATC_RrDrBlowerSet "ÈÄ¼® ¿îÀü¼® Ãø ºí·Î¿ö Áõ°¨ ¼³Á¤";
BA_ "Version" SG_ 158 ATS_DATC_RrDrModeSet "19.12.08";
BA_ "UserSigValidity" SG_ 158 ATS_DATC_RrDrModeSet 3;
BA_ "GenSigStartValue" SG_ 158 ATS_DATC_RrDrModeSet 15;
BA_ "GenSigSendType" SG_ 158 ATS_DATC_RrDrModeSet 4;
BA_ "Description" SG_ 158 ATS_DATC_RrDrModeSet "ÈÄ¼® ¿îÀü¼® Ãø ¸ðµå ¼³Á¤";
BA_ "Version" SG_ 158 ATS_DATC_FrDrModeSet "19.12.08";
BA_ "UserSigValidity" SG_ 158 ATS_DATC_FrDrModeSet 3;
BA_ "GenSigSendType" SG_ 158 ATS_DATC_FrDrModeSet 4;
BA_ "Description" SG_ 158 ATS_DATC_FrDrModeSet "Àü¼® ¿îÀü¼® Ãø ¸ðµå ¼³Á¤";
BA_ "Version" SG_ 158 ATS_DATC_RrOnOffSet "19.12.08";
BA_ "UserSigValidity" SG_ 158 ATS_DATC_RrOnOffSet 3;
BA_ "GenSigStartValue" SG_ 158 ATS_DATC_RrOnOffSet 3;
BA_ "GenSigSendType" SG_ 158 ATS_DATC_RrOnOffSet 4;
BA_ "Description" SG_ 158 ATS_DATC_RrOnOffSet "ÈÄ¼® °øÁ¶ ¿Â¿ÀÇÁ ¼³Á¤";
BA_ "Version" SG_ 158 ATS_DATC_IntakeSet "19.12.08";
BA_ "UserSigValidity" SG_ 158 ATS_DATC_IntakeSet 3;
BA_ "GenSigStartValue" SG_ 158 ATS_DATC_IntakeSet 3;
BA_ "GenSigSendType" SG_ 158 ATS_DATC_IntakeSet 4;
BA_ "Description" SG_ 158 ATS_DATC_IntakeSet "³»¿Ü±â ¼³Á¤";
BA_ "Version" SG_ 158 ATS_DATC_OffReq "19.12.08";
BA_ "UserSigValidity" SG_ 158 ATS_DATC_OffReq 3;
BA_ "GenSigSendType" SG_ 158 ATS_DATC_OffReq 4;
BA_ "Description" SG_ 158 ATS_DATC_OffReq "Àü¼® °øÁ¶ ¿ÀÇÁ ¼³Á¤";
BA_ "Version" SG_ 158 ATS_DATC_FrDrAutoSet "19.12.08";
BA_ "UserSigValidity" SG_ 158 ATS_DATC_FrDrAutoSet 3;
BA_ "GenSigSendType" SG_ 158 ATS_DATC_FrDrAutoSet 4;
BA_ "Description" SG_ 158 ATS_DATC_FrDrAutoSet "Àü¼® ¿îÀü¼® Ãø AUTO ¼³Á¤";
BA_ "Version" SG_ 158 ATS_DATC_FrPsTempUpDn "19.12.08";
BA_ "UserSigValidity" SG_ 158 ATS_DATC_FrPsTempUpDn 3;
BA_ "GenSigSendType" SG_ 158 ATS_DATC_FrPsTempUpDn 4;
BA_ "Description" SG_ 158 ATS_DATC_FrPsTempUpDn "Àü¼® Á¶¼ö¼® Ãø ¼³Á¤¿Âµµ Áõ°¨ ¼³Á¤";
BA_ "Version" SG_ 158 ATS_DATC_FrDefog "19.12.08";
BA_ "UserSigValidity" SG_ 158 ATS_DATC_FrDefog 3;
BA_ "GenSigStartValue" SG_ 158 ATS_DATC_FrDefog 3;
BA_ "GenSigSendType" SG_ 158 ATS_DATC_FrDefog 4;
BA_ "Description" SG_ 158 ATS_DATC_FrDefog "Àü¼® DEF ¼³Á¤";
BA_ "Version" SG_ 158 ATS_DATC_RrSyncSet "19.12.08";
BA_ "UserSigValidity" SG_ 158 ATS_DATC_RrSyncSet 3;
BA_ "GenSigSendType" SG_ 158 ATS_DATC_RrSyncSet 4;
BA_ "Description" SG_ 158 ATS_DATC_RrSyncSet "ÈÄ¼® SYNC ¼³Á¤";
BA_ "Version" SG_ 158 ATS_DATC_AcSet "19.12.08";
BA_ "UserSigValidity" SG_ 158 ATS_DATC_AcSet 3;
BA_ "GenSigStartValue" SG_ 158 ATS_DATC_AcSet 3;
BA_ "GenSigSendType" SG_ 158 ATS_DATC_AcSet 4;
BA_ "Description" SG_ 158 ATS_DATC_AcSet "AC ¼³Á¤";
BA_ "Version" SG_ 158 ATS_DATC_AirCleaningSet "19.12.08";
BA_ "UserSigValidity" SG_ 158 ATS_DATC_AirCleaningSet 3;
BA_ "GenSigStartValue" SG_ 158 ATS_DATC_AirCleaningSet 3;
BA_ "GenSigSendType" SG_ 158 ATS_DATC_AirCleaningSet 4;
BA_ "Description" SG_ 158 ATS_DATC_AirCleaningSet "°ø±âÃ»Á¤¸ðµå ¼³Á¤";
BA_ "Version" SG_ 158 ATS_DATC_FrDrBlowerUpDn "19.12.08";
BA_ "UserSigValidity" SG_ 158 ATS_DATC_FrDrBlowerUpDn 3;
BA_ "GenSigSendType" SG_ 158 ATS_DATC_FrDrBlowerUpDn 4;
BA_ "Description" SG_ 158 ATS_DATC_FrDrBlowerUpDn "Àü¼® ¿îÀü¼® Ãø ºí·Î¿ö Áõ°¨ ¼³Á¤";
BA_ "Version" SG_ 158 ATS_DATC_FrDrTempUpDn "19.12.08";
BA_ "UserSigValidity" SG_ 158 ATS_DATC_FrDrTempUpDn 3;
BA_ "GenSigSendType" SG_ 158 ATS_DATC_FrDrTempUpDn 4;
BA_ "Description" SG_ 158 ATS_DATC_FrDrTempUpDn "Àü¼® ¿îÀü¼® Ãø ¼³Á¤¿Âµµ Áõ°¨ ¼³Á¤";
BA_ "Version" SG_ 158 ATS_DATC_RrDrAutoSet "19.12.08";
BA_ "UserSigValidity" SG_ 158 ATS_DATC_RrDrAutoSet 3;
BA_ "GenSigStartValue" SG_ 158 ATS_DATC_RrDrAutoSet 3;
BA_ "GenSigSendType" SG_ 158 ATS_DATC_RrDrAutoSet 4;
BA_ "Description" SG_ 158 ATS_DATC_RrDrAutoSet "ÈÄ¼® ¿îÀü¼® Ãø AUTO ¼³Á¤";
BA_ "Version" SG_ 1247 Navi_ParkingLot "18.09.04";
BA_ "UserSigValidity" SG_ 1247 Navi_ParkingLot 3;
BA_ "GenSigSendType" SG_ 1247 Navi_ParkingLot 4;
BA_ "Description" SG_ 1247 Navi_ParkingLot "18.08.09_";
BA_ "Version" SG_ 1247 Navi_AirConditionWarning "18.09.04";
BA_ "UserSigValidity" SG_ 1247 Navi_AirConditionWarning 3;
BA_ "GenSigStartValue" SG_ 1247 Navi_AirConditionWarning 3;
BA_ "GenSigSendType" SG_ 1247 Navi_AirConditionWarning 4;
BA_ "Description" SG_ 1247 Navi_AirConditionWarning "18.08.09_";
BA_ "Version" SG_ 1247 Navi_AirConditionType "18.09.04";
BA_ "UserSigValidity" SG_ 1247 Navi_AirConditionType 3;
BA_ "GenSigStartValue" SG_ 1247 Navi_AirConditionType 63;
BA_ "GenSigSendType" SG_ 1247 Navi_AirConditionType 4;
BA_ "Description" SG_ 1247 Navi_AirConditionType "18.08.09_";
BA_ "Version" SG_ 1240 HU_DistanceUnit "19.02.08";
BA_ "NetworkRequest" SG_ 1240 HU_DistanceUnit 0;
BA_ "UserSigValidity" SG_ 1240 HU_DistanceUnit 1;
BA_ "GenSigStartValue" SG_ 1240 HU_DistanceUnit 3;
BA_ "GenSigSendType" SG_ 1240 HU_DistanceUnit 4;
BA_ "Description" SG_ 1240 HU_DistanceUnit "16.12.02_J.H.J. DR Request";
BA_ "Version" SG_ 1240 HU_ThemeType "20.09.00";
BA_ "UserSigValidity" SG_ 1240 HU_ThemeType 0;
BA_ "GenSigStartValue" SG_ 1240 HU_ThemeType 15;
BA_ "GenSigSendType" SG_ 1240 HU_ThemeType 4;
BA_ "Description" SG_ 1240 HU_ThemeType "This signal indicates current H/Unit GUI theme value. 

 

Detail value -GUI Theme matching table, refer to attachement and ES SPEC";
BA_ "Version" SG_ 1240 HU_MicActivity "19.02.08";
BA_ "UserSigValidity" SG_ 1240 HU_MicActivity 0;
BA_ "GenSigStartValue" SG_ 1240 HU_MicActivity 3;
BA_ "GenSigSendType" SG_ 1240 HU_MicActivity 4;
BA_ "Description" SG_ 1240 HU_MicActivity "16.06.02_";
BA_ "Version" SG_ 1240 HU_Scheduled_Setting "19.05.02";
BA_ "UserSigValidity" SG_ 1240 HU_Scheduled_Setting 3;
BA_ "GenSigSendType" SG_ 1240 HU_Scheduled_Setting 4;
BA_ "Description" SG_ 1240 HU_Scheduled_Setting "Information of scheduled update charge setting

The signal means that scheduled update charaging information send to BMS for BMS SOC control";
BA_ "Version" SG_ 1240 AVN_RSPA_ModeSelect "19.08.08";
BA_ "UserSigValidity" SG_ 1240 AVN_RSPA_ModeSelect 0;
BA_ "GenSigStartValue" SG_ 1240 AVN_RSPA_ModeSelect 15;
BA_ "GenSigSendType" SG_ 1240 AVN_RSPA_ModeSelect 4;
BA_ "Description" SG_ 1240 AVN_RSPA_ModeSelect "Signal for User's RSPA¥± mode setting

RSPA¥± ¸ðµå ¼±ÅÃ ¸Þ´º CCP Focus ¹× CCP Confirm or Touch °á°ú";
BA_ "Version" SG_ 1240 CF_HU_GPSFlt "20.02.02";
BA_ "UserSigValidity" SG_ 1240 CF_HU_GPSFlt 0;
BA_ "TimeoutValue" SG_ 1240 CF_HU_GPSFlt "0x2";
BA_ "GenSigStartValue" SG_ 1240 CF_HU_GPSFlt 2;
BA_ "GenSigSendType" SG_ 1240 CF_HU_GPSFlt 4;
BA_ "Version" SG_ 1240 AVN_RSPA_CancelInput "19.05.03";
BA_ "UserSigValidity" SG_ 1240 AVN_RSPA_CancelInput 0;
BA_ "GenSigSendType" SG_ 1240 AVN_RSPA_CancelInput 4;
BA_ "Version" SG_ 1240 AVN_RSPA_Disp_Rdy "19.05.03";
BA_ "UserSigValidity" SG_ 1240 AVN_RSPA_Disp_Rdy 0;
BA_ "GenSigStartValue" SG_ 1240 AVN_RSPA_Disp_Rdy 3;
BA_ "GenSigSendType" SG_ 1240 AVN_RSPA_Disp_Rdy 4;
BA_ "Version" SG_ 1240 CF_AVN_ProfileIDRValue "18.09.04";
BA_ "UserSigValidity" SG_ 1240 CF_AVN_ProfileIDRValue 0;
BA_ "GenSigStartValue" SG_ 1240 CF_AVN_ProfileIDRValue 15;
BA_ "GenSigSendType" SG_ 1240 CF_AVN_ProfileIDRValue 4;
BA_ "Description" SG_ 1240 CF_AVN_ProfileIDRValue "18.08.22_This signal is only used in User Profile applied H/Unit";
BA_ "Version" SG_ 1240 HazardFromHUSVM "18.09.04";
BA_ "UserSigValidity" SG_ 1240 HazardFromHUSVM 0;
BA_ "GenSigStartValue" SG_ 1240 HazardFromHUSVM 3;
BA_ "GenSigSendType" SG_ 1240 HazardFromHUSVM 4;
BA_ "Description" SG_ 1240 HazardFromHUSVM "18.08.22_This signal is for the 'Premium AVNT6 && SVM&& ConnectedCarService' vehicle only";
BA_ "Version" SG_ 1240 OMUOSMirCtrl "18.09.04";
BA_ "UserSigValidity" SG_ 1240 OMUOSMirCtrl 0;
BA_ "GenSigStartValue" SG_ 1240 OMUOSMirCtrl 3;
BA_ "GenSigSendType" SG_ 1240 OMUOSMirCtrl 4;
BA_ "Description" SG_ 1240 OMUOSMirCtrl "18.08.22_This signal is for the 'Premium AVNT 6.0&&SVM&&ConnectedCarService' vehicle only";
BA_ "Version" SG_ 1240 OTAUIStatus "21.03.02";
BA_ "UserSigValidity" SG_ 1240 OTAUIStatus 0;
BA_ "GenSigSendType" SG_ 1240 OTAUIStatus 4;
BA_ "Description" SG_ 1240 OTAUIStatus "0x00 : Headunit is booting so, Headunit can't display any state

0x01 : Headunit is normal state, Headunit could display according to CCU command.";
BA_ "Version" SG_ 1240 C_TeleActiveStatus "19.04.06";
BA_ "UserSigValidity" SG_ 1240 C_TeleActiveStatus 0;
BA_ "GenSigStartValue" SG_ 1240 C_TeleActiveStatus 3;
BA_ "GenSigSendType" SG_ 1240 C_TeleActiveStatus 4;
BA_ "Version" SG_ 1240 HU_AliveStatus "19.02.08";
BA_ "NetworkRequest" SG_ 1240 HU_AliveStatus 0;
BA_ "UserSigValidity" SG_ 1240 HU_AliveStatus 0;
BA_ "GenSigStartValue" SG_ 1240 HU_AliveStatus 3;
BA_ "GenSigSendType" SG_ 1240 HU_AliveStatus 4;
BA_ "Description" SG_ 1240 HU_AliveStatus "18.08.22_";
BA_ "Version" SG_ 1240 HU_RTCCheck "20.02.02";
BA_ "UserSigValidity" SG_ 1240 HU_RTCCheck 3;
BA_ "TimeoutValue" SG_ 1240 HU_RTCCheck "0x3";
BA_ "GenSigStartValue" SG_ 1240 HU_RTCCheck 3;
BA_ "GenSigSendType" SG_ 1240 HU_RTCCheck 4;
BA_ "Version" SG_ 2424580353 DATC_Crc12Val "21.09.03";
BA_ "UserSigValidity" SG_ 2424580353 DATC_Crc12Val 3;
BA_ "GenSigStartValue" SG_ 2424580353 DATC_Crc12Val 65535;
BA_ "GenSigSendType" SG_ 2424580353 DATC_Crc12Val 4;
BA_ "Description" SG_ 2424580353 DATC_Crc12Val "The data area for CRC calculation is based on the data length (DLC) of the message DB.

The CRC shall be calculated over the entire data block (excluding the CRC bytes) including the user data, alive counter and Data ID



- CRC Polynomial (0x1021) , Ini";
BA_ "Version" SG_ 2424580353 DATC_AlvCnt12Val "21.09.03";
BA_ "UserSigValidity" SG_ 2424580353 DATC_AlvCnt12Val 3;
BA_ "GenSigSendType" SG_ 2424580353 DATC_AlvCnt12Val 4;
BA_ "Description" SG_ 2424580353 DATC_AlvCnt12Val "For the first transmission request for a data element the counter shall be initialized with 0 and shall be incremented by 1 for every subsequent send request. 

When the counter reaches the maximum value(0xFF), then it shall restart with 0 for the next s";
BA_ "Version" SG_ 2424580353 DATC_StrWhlHtrSwReq "17.11.00";
BA_ "UserSigValidity" SG_ 2424580353 DATC_StrWhlHtrSwReq 7;
BA_ "GenSigSendType" SG_ 2424580353 DATC_StrWhlHtrSwReq 4;
BA_ "Description" SG_ 2424580353 DATC_StrWhlHtrSwReq "Steering Wheel heater S/W";
BA_ "Version" SG_ 2424580353 DATC_FRStHtrSwReq "17.11.00";
BA_ "UserSigValidity" SG_ 2424580353 DATC_FRStHtrSwReq 7;
BA_ "GenSigSendType" SG_ 2424580353 DATC_FRStHtrSwReq 4;
BA_ "Description" SG_ 2424580353 DATC_FRStHtrSwReq "Front Right Seat heater S/W";
BA_ "Version" SG_ 2424580353 DATC_FRStVentSwReq "17.11.00";
BA_ "UserSigValidity" SG_ 2424580353 DATC_FRStVentSwReq 7;
BA_ "GenSigSendType" SG_ 2424580353 DATC_FRStVentSwReq 4;
BA_ "Description" SG_ 2424580353 DATC_FRStVentSwReq "Front Right Seat cooler S/W";
BA_ "Version" SG_ 2424580353 DATC_RrDefSw "19.04.06";
BA_ "UserSigValidity" SG_ 2424580353 DATC_RrDefSw 3;
BA_ "GenSigSendType" SG_ 2424580353 DATC_RrDefSw 4;
BA_ "Description" SG_ 2424580353 DATC_RrDefSw "Rear Defog Switch";
BA_ "Version" SG_ 2424580353 DATC_FLStOpReq "17.11.00";
BA_ "UserSigValidity" SG_ 2424580353 DATC_FLStOpReq 7;
BA_ "GenSigSendType" SG_ 2424580353 DATC_FLStOpReq 4;
BA_ "Description" SG_ 2424580353 DATC_FLStOpReq "Left Seat warmer / Ventilation Operation request";
BA_ "Version" SG_ 2424580353 DATC_FRStOpReq "17.11.00";
BA_ "UserSigValidity" SG_ 2424580353 DATC_FRStOpReq 7;
BA_ "GenSigSendType" SG_ 2424580353 DATC_FRStOpReq 4;
BA_ "Description" SG_ 2424580353 DATC_FRStOpReq "Right Seat Warmer / Ventilation Operation request";
BA_ "Version" SG_ 2424580353 DATC_FLStHtrSwReq "17.11.00";
BA_ "UserSigValidity" SG_ 2424580353 DATC_FLStHtrSwReq 7;
BA_ "GenSigSendType" SG_ 2424580353 DATC_FLStHtrSwReq 4;
BA_ "Description" SG_ 2424580353 DATC_FLStHtrSwReq "Front Left Seat heater S/W";
BA_ "Version" SG_ 2424580353 DATC_FLStVentSwReq "17.11.00";
BA_ "UserSigValidity" SG_ 2424580353 DATC_FLStVentSwReq 7;
BA_ "GenSigSendType" SG_ 2424580353 DATC_FLStVentSwReq 4;
BA_ "Description" SG_ 2424580353 DATC_FLStVentSwReq "Front Left Seat cooler S/W";
BA_ "Version" SG_ 2424580353 DATC_FLStTmblrSwReq "18.01.07";
BA_ "UserSigValidity" SG_ 2424580353 DATC_FLStTmblrSwReq 3;
BA_ "GenSigSendType" SG_ 2424580353 DATC_FLStTmblrSwReq 4;
BA_ "Description" SG_ 2424580353 DATC_FLStTmblrSwReq "Front Left Seat cooler S/W";
BA_ "Version" SG_ 2424580353 DATC_FRStTmblrSwReq "18.01.07";
BA_ "UserSigValidity" SG_ 2424580353 DATC_FRStTmblrSwReq 3;
BA_ "GenSigSendType" SG_ 2424580353 DATC_FRStTmblrSwReq 4;
BA_ "Description" SG_ 2424580353 DATC_FRStTmblrSwReq "Front Left Seat cooler S/W";
BA_ "Version" SG_ 2424580353 DATC_RRStHtrSwReq "18.03.05";
BA_ "UserSigValidity" SG_ 2424580353 DATC_RRStHtrSwReq 7;
BA_ "GenSigSendType" SG_ 2424580353 DATC_RRStHtrSwReq 4;
BA_ "Description" SG_ 2424580353 DATC_RRStHtrSwReq "This signal indicate DATC Rear Right Seat Heater Switch Request";
BA_ "Version" SG_ 2424580353 DATC_RRStVentSwReq "18.03.05";
BA_ "UserSigValidity" SG_ 2424580353 DATC_RRStVentSwReq 7;
BA_ "GenSigSendType" SG_ 2424580353 DATC_RRStVentSwReq 4;
BA_ "Description" SG_ 2424580353 DATC_RRStVentSwReq "This signal indicates DATC Rear Right Seat Ventilation Switch Request";
BA_ "Version" SG_ 2424580353 DATC_RLStHtrSwReq "19.06.00";
BA_ "UserSigValidity" SG_ 2424580353 DATC_RLStHtrSwReq 7;
BA_ "GenSigSendType" SG_ 2424580353 DATC_RLStHtrSwReq 4;
BA_ "Description" SG_ 2424580353 DATC_RLStHtrSwReq "This signal indicates DATC Rear Left Seat Heater Switch Request";
BA_ "Version" SG_ 2424580353 DATC_RLStVentSwReq "18.03.05";
BA_ "UserSigValidity" SG_ 2424580353 DATC_RLStVentSwReq 7;
BA_ "GenSigSendType" SG_ 2424580353 DATC_RLStVentSwReq 4;
BA_ "Description" SG_ 2424580353 DATC_RLStVentSwReq "This signal indicates DATC Rear Left Seat Ventilation Switch Request";
BA_ "Version" SG_ 2424580353 DATC_FRWndShldHtSW "19.04.06";
BA_ "UserSigValidity" SG_ 2424580353 DATC_FRWndShldHtSW 3;
BA_ "GenSigSendType" SG_ 2424580353 DATC_FRWndShldHtSW 4;
BA_ "Description" SG_ 2424580353 DATC_FRWndShldHtSW "Front windshield glass heating switch

(Russia / Canada regions applied)";
BA_ "Version" SG_ 2424580353 DATC_WhistlelNoise "19.04.06";
BA_ "UserSigValidity" SG_ 2424580353 DATC_WhistlelNoise 3;
BA_ "GenSigSendType" SG_ 2424580353 DATC_WhistlelNoise 4;
BA_ "Description" SG_ 2424580353 DATC_WhistlelNoise "This signal is to prevent whistle noise from the door glass

(Fresh & Blower more than 4 Step condition)";
BA_ "Version" SG_ 2424580353 DATC_WdwClsReq "19.07.06";
BA_ "UserSigValidity" SG_ 2424580353 DATC_WdwClsReq 7;
BA_ "GenSigSendType" SG_ 2424580353 DATC_WdwClsReq 4;
BA_ "Description" SG_ 2424580353 DATC_WdwClsReq "This signal indicates Window Close Request.

(This signal is used for Closing Control of Window when AirClean Switch is selecting)";
BA_ "Version" SG_ 2424580353 DATC_RRSyncDis "19.12.00";
BA_ "UserSigValidity" SG_ 2424580353 DATC_RRSyncDis 7;
BA_ "GenSigSendType" SG_ 2424580353 DATC_RRSyncDis 4;
BA_ "Description" SG_ 2424580353 DATC_RRSyncDis "This signal indicates SYNC Graphic On & Off.

This signal occurs when Rear SYNC switch(button) is selected either manually or automatically.";
BA_ "Version" SG_ 171 BLTN_CAM_UI_Mode_Tmt_Req "21.05.02";
BA_ "UserSigValidity" SG_ 171 BLTN_CAM_UI_Mode_Tmt_Req 1;
BA_ "GenSigSendType" SG_ 171 BLTN_CAM_UI_Mode_Tmt_Req 4;
BA_ "Description" SG_ 171 BLTN_CAM_UI_Mode_Tmt_Req "Built-in Cam UI Mode terminate request.";
BA_ "Version" SG_ 171 BLTN_CAM_Dis_Touch_BeepSound "21.05.02";
BA_ "UserSigValidity" SG_ 171 BLTN_CAM_Dis_Touch_BeepSound 1;
BA_ "GenSigSendType" SG_ 171 BLTN_CAM_Dis_Touch_BeepSound 4;
BA_ "Description" SG_ 171 BLTN_CAM_Dis_Touch_BeepSound "Display Touch Beep Sound of valid space touch.";
BA_ "Version" SG_ 171 BLTN_CAM_PopUp_Req "22.05.02";
BA_ "UserSigValidity" SG_ 171 BLTN_CAM_PopUp_Req 0;
BA_ "GenSigSendType" SG_ 171 BLTN_CAM_PopUp_Req 4;
BA_ "Description" SG_ 171 BLTN_CAM_PopUp_Req "Built-in Cam Operating and SD Card related Popup Request on HU Display.";
BA_ "Version" SG_ 171 BLTN_CAM_File_List_Renew "21.05.02";
BA_ "UserSigValidity" SG_ 171 BLTN_CAM_File_List_Renew 1;
BA_ "GenSigSendType" SG_ 171 BLTN_CAM_File_List_Renew 4;
BA_ "Description" SG_ 171 BLTN_CAM_File_List_Renew "The Storage information is renewed inform to HU.";
BA_ "Version" SG_ 171 BLTN_CAM_Wifi_Pwd_Chg_State "21.05.04";
BA_ "UserSigValidity" SG_ 171 BLTN_CAM_Wifi_Pwd_Chg_State 1;
BA_ "GenSigSendType" SG_ 171 BLTN_CAM_Wifi_Pwd_Chg_State 4;
BA_ "Description" SG_ 171 BLTN_CAM_Wifi_Pwd_Chg_State "The Response, when HU change Wifi Passowrd via SOME/IP";
BA_ "Version" SG_ 1253 SMK_Crc1Val "21.09.03";
BA_ "UserSigValidity" SG_ 1253 SMK_Crc1Val 0;
BA_ "GenSigSendType" SG_ 1253 SMK_Crc1Val 4;
BA_ "Description" SG_ 1253 SMK_Crc1Val "The data area for CRC calculation is based on the data length (DLC) of the message DB.

The CRC shall be calculated over the entire data block (excluding the CRC bytes) including the user data, alive counter and Data ID 

 

- CRC Polynomial (0x1D) , Ini";
BA_ "Version" SG_ 1253 SMK_AlvCnt1Val "21.09.03";
BA_ "UserSigValidity" SG_ 1253 SMK_AlvCnt1Val 0;
BA_ "GenSigSendType" SG_ 1253 SMK_AlvCnt1Val 4;
BA_ "Description" SG_ 1253 SMK_AlvCnt1Val "For the first transmission request for a data element the counter shall be initialized with 0 and shall be incremented by 1

for every subsequent send request. When the counter reaches the maximum value(0xE), then it shall restart with 0 for the next sen";
BA_ "Version" SG_ 1253 DoorLock_PsvDrLkReq "17.12.00";
BA_ "UserSigValidity" SG_ 1253 DoorLock_PsvDrLkReq 0;
BA_ "GenSigSendType" SG_ 1253 DoorLock_PsvDrLkReq 4;
BA_ "Version" SG_ 1253 DoorLock_PsvDrUnLkReq "17.12.00";
BA_ "UserSigValidity" SG_ 1253 DoorLock_PsvDrUnLkReq 0;
BA_ "GenSigSendType" SG_ 1253 DoorLock_PsvDrUnLkReq 4;
BA_ "Version" SG_ 1253 DoorLock_DrvDrPsvAcsReq "17.12.00";
BA_ "UserSigValidity" SG_ 1253 DoorLock_DrvDrPsvAcsReq 0;
BA_ "GenSigSendType" SG_ 1253 DoorLock_DrvDrPsvAcsReq 4;
BA_ "Description" SG_ 1253 DoorLock_DrvDrPsvAcsReq "-(Old)C_P_FL";
BA_ "Version" SG_ 1253 DoorLock_AsstDrPsvAcsReq "17.12.00";
BA_ "UserSigValidity" SG_ 1253 DoorLock_AsstDrPsvAcsReq 0;
BA_ "GenSigSendType" SG_ 1253 DoorLock_AsstDrPsvAcsReq 4;
BA_ "Description" SG_ 1253 DoorLock_AsstDrPsvAcsReq "-(Old)C_P_FR";
BA_ "Version" SG_ 1253 DoorLock_TrnkTlgtPsvAcsReq "17.12.00";
BA_ "UserSigValidity" SG_ 1253 DoorLock_TrnkTlgtPsvAcsReq 0;
BA_ "GenSigSendType" SG_ 1253 DoorLock_TrnkTlgtPsvAcsReq 4;
BA_ "Description" SG_ 1253 DoorLock_TrnkTlgtPsvAcsReq "-(Old)C_PassiveTrunk_TG";
BA_ "Version" SG_ 1253 DoorLock_RrLftDrPsvAcsReq "17.12.00";
BA_ "UserSigValidity" SG_ 1253 DoorLock_RrLftDrPsvAcsReq 0;
BA_ "GenSigSendType" SG_ 1253 DoorLock_RrLftDrPsvAcsReq 4;
BA_ "Description" SG_ 1253 DoorLock_RrLftDrPsvAcsReq "-(Old)C_P_RL";
BA_ "Version" SG_ 1253 DoorLock_RrRtDrPsvAcsReq "17.12.00";
BA_ "UserSigValidity" SG_ 1253 DoorLock_RrRtDrPsvAcsReq 0;
BA_ "GenSigSendType" SG_ 1253 DoorLock_RrRtDrPsvAcsReq 4;
BA_ "Description" SG_ 1253 DoorLock_RrRtDrPsvAcsReq "-(Old)C_P_RR";
BA_ "Version" SG_ 1253 DoorLock_PsdPsvAcsReq "17.12.00";
BA_ "UserSigValidity" SG_ 1253 DoorLock_PsdPsvAcsReq 0;
BA_ "GenSigSendType" SG_ 1253 DoorLock_PsdPsvAcsReq 4;
BA_ "Description" SG_ 1253 DoorLock_PsdPsvAcsReq "-Fob Asnswer for each LH/RH PSD LF searching";
BA_ "Version" SG_ 1253 RSPA_DigitalKeyAuth "19.07.02";
BA_ "UserSigValidity" SG_ 1253 RSPA_DigitalKeyAuth 0;
BA_ "GenSigSendType" SG_ 1253 RSPA_DigitalKeyAuth 4;
BA_ "Description" SG_ 1253 RSPA_DigitalKeyAuth "Authenticaion by Digital key in RSPA mode";
BA_ "Version" SG_ 1253 Auth_Method "20.03.07";
BA_ "NetworkRequestHoldingTime" SG_ 1253 Auth_Method 5000;
BA_ "NetworkRequest" SG_ 1253 Auth_Method 0;
BA_ "UserSigValidity" SG_ 1253 Auth_Method 0;
BA_ "GenSigSendType" SG_ 1253 Auth_Method 4;
BA_ "Description" SG_ 1253 Auth_Method "This signal is for a send Authentication result and authentication method.

- Fob, TP, Fingerprint, NFC(Digital Key, Card Key), BLE, Face Recognition, Digital key Passive";
BA_ "Version" SG_ 1253 DoorLock_StrgbxPsvAcsReq "20.07.05";
BA_ "UserSigValidity" SG_ 1253 DoorLock_StrgbxPsvAcsReq 0;
BA_ "GenSigSendType" SG_ 1253 DoorLock_StrgbxPsvAcsReq 4;
BA_ "Version" SG_ 1253 DoorLock_FrnkWrngOpnReq "21.09.07";
BA_ "UserSigValidity" SG_ 1253 DoorLock_FrnkWrngOpnReq 0;
BA_ "GenSigSendType" SG_ 1253 DoorLock_FrnkWrngOpnReq 4;
BA_ "Description" SG_ 1253 DoorLock_FrnkWrngOpnReq "This signal is SMK Frunk Warning Open request";
BA_ "Version" SG_ 1253 DoorLock_SmrtPsdPsvAcsReq "19.01.10";
BA_ "UserSigValidity" SG_ 1253 DoorLock_SmrtPsdPsvAcsReq 0;
BA_ "GenSigSendType" SG_ 1253 DoorLock_SmrtPsdPsvAcsReq 4;
BA_ "Description" SG_ 1253 DoorLock_SmrtPsdPsvAcsReq "Smart Sliding Door Open Command";
BA_ "Version" SG_ 1253 Auth_Event "20.03.07";
BA_ "NetworkRequestHoldingTime" SG_ 1253 Auth_Event 5000;
BA_ "NetworkRequest" SG_ 1253 Auth_Event 0;
BA_ "UserSigValidity" SG_ 1253 Auth_Event 0;
BA_ "GenSigSendType" SG_ 1253 Auth_Event 4;
BA_ "Description" SG_ 1253 Auth_Event "This signal is for a send Authentication event";
BA_ "Version" SG_ 1252 RKE_Crc1Val "21.09.03";
BA_ "UserSigValidity" SG_ 1252 RKE_Crc1Val 0;
BA_ "GenSigSendType" SG_ 1252 RKE_Crc1Val 4;
BA_ "Description" SG_ 1252 RKE_Crc1Val "The data area for CRC calculation is based on the data length (DLC) of the message DB.

The CRC shall be calculated over the entire data block (excluding the CRC bytes) including the user data, alive counter and Data ID 

 

- CRC Polynomial (0x1D) , Ini";
BA_ "Version" SG_ 1252 RKE_AlvCnt1Val "21.09.03";
BA_ "UserSigValidity" SG_ 1252 RKE_AlvCnt1Val 0;
BA_ "GenSigSendType" SG_ 1252 RKE_AlvCnt1Val 4;
BA_ "Description" SG_ 1252 RKE_AlvCnt1Val "For the first transmission request for a data element the counter shall be initialized with 0 and shall be incremented by 1

for every subsequent send request. When the counter reaches the maximum value(0xE), then it shall restart with 0 for the next sen";
BA_ "Version" SG_ 1252 RKE_BtnReq "20.12.00";
BA_ "NetworkRequestHoldingTime" SG_ 1252 RKE_BtnReq 5000;
BA_ "NetworkRequest" SG_ 1252 RKE_BtnReq 0;
BA_ "UserSigValidity" SG_ 1252 RKE_BtnReq 0;
BA_ "GenSigSendType" SG_ 1252 RKE_BtnReq 4;
BA_ "Description" SG_ 1252 RKE_BtnReq "Remote Key Button Request from Folding Key or Smart Key";
BA_ "Version" SG_ 1252 RKE_PsdBtnReq "17.12.00";
BA_ "NetworkRequestHoldingTime" SG_ 1252 RKE_PsdBtnReq 5000;
BA_ "NetworkRequest" SG_ 1252 RKE_PsdBtnReq 0;
BA_ "UserSigValidity" SG_ 1252 RKE_PsdBtnReq 0;
BA_ "GenSigSendType" SG_ 1252 RKE_PsdBtnReq 4;
BA_ "Description" SG_ 1252 RKE_PsdBtnReq "Remote Key Power Sliding Door Button Request from Folding Key or Smart Key";
BA_ "Version" SG_ 1252 RKE_WdwUpDnReq "17.12.00";
BA_ "NetworkRequestHoldingTime" SG_ 1252 RKE_WdwUpDnReq 5000;
BA_ "NetworkRequest" SG_ 1252 RKE_WdwUpDnReq 0;
BA_ "UserSigValidity" SG_ 1252 RKE_WdwUpDnReq 0;
BA_ "GenSigSendType" SG_ 1252 RKE_WdwUpDnReq 4;
BA_ "Description" SG_ 1252 RKE_WdwUpDnReq "Remote Key Window Up and Down Request from Folding Key or Smart Key";
BA_ "Version" SG_ 1252 RKE_TrnkTlgtBtnReq "18.07.01";
BA_ "NetworkRequestHoldingTime" SG_ 1252 RKE_TrnkTlgtBtnReq 5000;
BA_ "NetworkRequest" SG_ 1252 RKE_TrnkTlgtBtnReq 0;
BA_ "UserSigValidity" SG_ 1252 RKE_TrnkTlgtBtnReq 0;
BA_ "GenSigSendType" SG_ 1252 RKE_TrnkTlgtBtnReq 4;
BA_ "Description" SG_ 1252 RKE_TrnkTlgtBtnReq "This signal for Tailgate or Trunk open CMD

While RKE Tailgate(Trunk) Button push, This Signal Tx On

While Tailgate(Trunk) Button released, This Signal Tx Off";
BA_ "Version" SG_ 1252 RKE_ID "17.12.00";
BA_ "UserSigValidity" SG_ 1252 RKE_ID 0;
BA_ "GenSigSendType" SG_ 1252 RKE_ID 4;
BA_ "Description" SG_ 1252 RKE_ID "Remote Key Window Up and Down Request from Folding Key or Smart Key



Folding key or smart key ID for recently received RF frame";
BA_ "Version" SG_ 1252 RKE_PwrDrAllOpnClsReq "19.04.04";
BA_ "NetworkRequestHoldingTime" SG_ 1252 RKE_PwrDrAllOpnClsReq 5000;
BA_ "NetworkRequest" SG_ 1252 RKE_PwrDrAllOpnClsReq 0;
BA_ "UserSigValidity" SG_ 1252 RKE_PwrDrAllOpnClsReq 0;
BA_ "GenSigSendType" SG_ 1252 RKE_PwrDrAllOpnClsReq 4;
BA_ "Description" SG_ 1252 RKE_PwrDrAllOpnClsReq "Remote Key Button Signal for PSD and PTG opening or closing together";
BA_ "Version" SG_ 1251 IAU_EsyAcsProfileID "18.08.12";
BA_ "NetworkRequestHoldingTime" SG_ 1251 IAU_EsyAcsProfileID 5;
BA_ "NetworkRequest" SG_ 1251 IAU_EsyAcsProfileID 0;
BA_ "UserSigValidity" SG_ 1251 IAU_EsyAcsProfileID 0;
BA_ "GenSigSendType" SG_ 1251 IAU_EsyAcsProfileID 4;
BA_ "Description" SG_ 1251 IAU_EsyAcsProfileID "This signal indicate the current detected profile ID by NFC.

(The drv seat move to the easy access position of the detected profile ID when receive the signal)";
BA_ "Version" SG_ 1251 IAU_SmrtPhnID "20.04.06";
BA_ "NetworkRequestHoldingTime" SG_ 1251 IAU_SmrtPhnID 5;
BA_ "NetworkRequest" SG_ 1251 IAU_SmrtPhnID 0;
BA_ "UserSigValidity" SG_ 1251 IAU_SmrtPhnID 0;
BA_ "GenSigSendType" SG_ 1251 IAU_SmrtPhnID 4;
BA_ "Description" SG_ 1251 IAU_SmrtPhnID "SmartPhone ID with BLE Connection";
BA_ "Version" SG_ 1251 IAU_SmrtPhnCmd "19.08.08";
BA_ "NetworkRequestHoldingTime" SG_ 1251 IAU_SmrtPhnCmd 5;
BA_ "NetworkRequest" SG_ 1251 IAU_SmrtPhnCmd 0;
BA_ "UserSigValidity" SG_ 1251 IAU_SmrtPhnCmd 0;
BA_ "GenSigSendType" SG_ 1251 IAU_SmrtPhnCmd 4;
BA_ "Description" SG_ 1251 IAU_SmrtPhnCmd "SmartPhone RKE Command Indi";
BA_ "Version" SG_ 1251 IAUwFRU_ISK_LearningReq "20.05.02";
BA_ "NetworkRequestHoldingTime" SG_ 1251 IAUwFRU_ISK_LearningReq 5;
BA_ "NetworkRequest" SG_ 1251 IAUwFRU_ISK_LearningReq 0;
BA_ "UserSigValidity" SG_ 1251 IAUwFRU_ISK_LearningReq 0;
BA_ "GenSigSendType" SG_ 1251 IAUwFRU_ISK_LearningReq 4;
BA_ "Description" SG_ 1251 IAUwFRU_ISK_LearningReq "This signal is to request ISK learning to FRU";
BA_ "Version" SG_ 1251 IAUwFPM_ISK_LearningReq "20.05.02";
BA_ "NetworkRequestHoldingTime" SG_ 1251 IAUwFPM_ISK_LearningReq 5;
BA_ "NetworkRequest" SG_ 1251 IAUwFPM_ISK_LearningReq 0;
BA_ "UserSigValidity" SG_ 1251 IAUwFPM_ISK_LearningReq 0;
BA_ "GenSigSendType" SG_ 1251 IAUwFPM_ISK_LearningReq 4;
BA_ "Description" SG_ 1251 IAUwFPM_ISK_LearningReq "This signal is to request ISK learning to FPM";
BA_ "Version" SG_ 1251 IAU2FRU_ISKLearnFdbck "20.04.05";
BA_ "NetworkRequestHoldingTime" SG_ 1251 IAU2FRU_ISKLearnFdbck 5;
BA_ "NetworkRequest" SG_ 1251 IAU2FRU_ISKLearnFdbck 0;
BA_ "UserSigValidity" SG_ 1251 IAU2FRU_ISKLearnFdbck 0;
BA_ "GenSigSendType" SG_ 1251 IAU2FRU_ISKLearnFdbck 4;
BA_ "Description" SG_ 1251 IAU2FRU_ISKLearnFdbck "This isgnla is learning feedback";
BA_ "Version" SG_ 1251 IAU2FPM_ISKLearnFdbck "20.04.05";
BA_ "NetworkRequestHoldingTime" SG_ 1251 IAU2FPM_ISKLearnFdbck 5;
BA_ "NetworkRequest" SG_ 1251 IAU2FPM_ISKLearnFdbck 0;
BA_ "UserSigValidity" SG_ 1251 IAU2FPM_ISKLearnFdbck 0;
BA_ "GenSigSendType" SG_ 1251 IAU2FPM_ISKLearnFdbck 4;
BA_ "Description" SG_ 1251 IAU2FPM_ISKLearnFdbck "This signal is learning feedback";
BA_ "Version" SG_ 172 BLTN_CAM_FR_VerPos_NvalueSet "22.07.06";
BA_ "UserSigValidity" SG_ 172 BLTN_CAM_FR_VerPos_NvalueSet 0;
BA_ "GenSigSendType" SG_ 172 BLTN_CAM_FR_VerPos_NvalueSet 4;
BA_ "Description" SG_ 172 BLTN_CAM_FR_VerPos_NvalueSet "Front Camera Vertical position setting value.";
BA_ "Version" SG_ 172 BLTN_CAM_AppNoti_PEV_NvalueSet "21.05.02";
BA_ "UserSigValidity" SG_ 172 BLTN_CAM_AppNoti_PEV_NvalueSet 0;
BA_ "GenSigSendType" SG_ 172 BLTN_CAM_AppNoti_PEV_NvalueSet 4;
BA_ "Description" SG_ 172 BLTN_CAM_AppNoti_PEV_NvalueSet "Parked Event notification to Connectivity Phone App. On/Off";
BA_ "Version" SG_ 172 BLTN_CAM_WiFi_AutoOn_NvalueSet "21.05.02";
BA_ "UserSigValidity" SG_ 172 BLTN_CAM_WiFi_AutoOn_NvalueSet 0;
BA_ "GenSigSendType" SG_ 172 BLTN_CAM_WiFi_AutoOn_NvalueSet 4;
BA_ "Description" SG_ 172 BLTN_CAM_WiFi_AutoOn_NvalueSet "Wifi On/Off User setting";
BA_ "Version" SG_ 172 BLTN_CAM_StoProp_NvalueSet "21.05.02";
BA_ "UserSigValidity" SG_ 172 BLTN_CAM_StoProp_NvalueSet 0;
BA_ "GenSigSendType" SG_ 172 BLTN_CAM_StoProp_NvalueSet 4;
BA_ "Description" SG_ 172 BLTN_CAM_StoProp_NvalueSet "Propotion of built-in Cam SD card Propotion set of the Recording Categories";
BA_ "Version" SG_ 172 CF_AVN_BLTN_CAM_USMReset "21.05.02";
BA_ "UserSigValidity" SG_ 172 CF_AVN_BLTN_CAM_USMReset 0;
BA_ "GenSigSendType" SG_ 172 CF_AVN_BLTN_CAM_USMReset 4;
BA_ "Description" SG_ 172 CF_AVN_BLTN_CAM_USMReset "Buit-in Cam USM Reset Request.";
BA_ "Version" SG_ 172 CF_AVN_BLTN_CAM_RecReset "21.05.02";
BA_ "UserSigValidity" SG_ 172 CF_AVN_BLTN_CAM_RecReset 0;
BA_ "GenSigSendType" SG_ 172 CF_AVN_BLTN_CAM_RecReset 4;
BA_ "Description" SG_ 172 CF_AVN_BLTN_CAM_RecReset "Buit-in Cam format(all file delete/Reset) Request.";
BA_ "Version" SG_ 172 BLTN_CAM_File_DEL_CPY_Cmd "21.05.02";
BA_ "UserSigValidity" SG_ 172 BLTN_CAM_File_DEL_CPY_Cmd 0;
BA_ "GenSigSendType" SG_ 172 BLTN_CAM_File_DEL_CPY_Cmd 4;
BA_ "Description" SG_ 172 BLTN_CAM_File_DEL_CPY_Cmd "Buit-in Cam operation control of copying and deleting.";
BA_ "Version" SG_ 172 BLTN_CAM_LVDS_Mode_Cmd "21.05.02";
BA_ "UserSigValidity" SG_ 172 BLTN_CAM_LVDS_Mode_Cmd 0;
BA_ "GenSigSendType" SG_ 172 BLTN_CAM_LVDS_Mode_Cmd 4;
BA_ "Description" SG_ 172 BLTN_CAM_LVDS_Mode_Cmd "This Signal is for LVDS output commend to BLTN_CAM";
BA_ "Version" SG_ 172 HU_BLTN_CAM_Disp_Touch_Pos_X "21.05.02";
BA_ "UserSigValidity" SG_ 172 HU_BLTN_CAM_Disp_Touch_Pos_X 0;
BA_ "GenSigSendType" SG_ 172 HU_BLTN_CAM_Disp_Touch_Pos_X 4;
BA_ "Description" SG_ 172 HU_BLTN_CAM_Disp_Touch_Pos_X "X position of touch of display when BLTN-in CAM Engineer mode in";
BA_ "Version" SG_ 172 HU_BLTN_CAM_Disp_Touch_Pos_Y "21.05.02";
BA_ "UserSigValidity" SG_ 172 HU_BLTN_CAM_Disp_Touch_Pos_Y 0;
BA_ "GenSigSendType" SG_ 172 HU_BLTN_CAM_Disp_Touch_Pos_Y 4;
BA_ "Description" SG_ 172 HU_BLTN_CAM_Disp_Touch_Pos_Y "Y position of touch of display when BLTN-in CAM Engineer mode in";
BA_ "Version" SG_ 172 MEV_Rec_Req "22.04.02";
BA_ "UserSigValidity" SG_ 172 MEV_Rec_Req 0;
BA_ "GenSigSendType" SG_ 172 MEV_Rec_Req 4;
BA_ "Description" SG_ 172 MEV_Rec_Req "HU ¡æ BLTN_CAM Manual Event Record request.";
BA_ "Version" SG_ 172 BLTN_CAM_RR_VerPos_NvalueSet "22.07.06";
BA_ "UserSigValidity" SG_ 172 BLTN_CAM_RR_VerPos_NvalueSet 0;
BA_ "GenSigSendType" SG_ 172 BLTN_CAM_RR_VerPos_NvalueSet 4;
BA_ "Description" SG_ 172 BLTN_CAM_RR_VerPos_NvalueSet "Rear Camera Vertical position setting value.";
BA_ "Version" SG_ 172 TML_Rec_Req "22.04.02";
BA_ "UserSigValidity" SG_ 172 TML_Rec_Req 0;
BA_ "GenSigSendType" SG_ 172 TML_Rec_Req 4;
BA_ "Description" SG_ 172 TML_Rec_Req "HU ¡æ BLTN_CAM Time lapse Start and End Request.";
BA_ "Version" SG_ 172 BLTN_CAM_SD_Card_UnMt_Mt_Req "22.05.02";
BA_ "UserSigValidity" SG_ 172 BLTN_CAM_SD_Card_UnMt_Mt_Req 0;
BA_ "GenSigSendType" SG_ 172 BLTN_CAM_SD_Card_UnMt_Mt_Req 4;
BA_ "Description" SG_ 172 BLTN_CAM_SD_Card_UnMt_Mt_Req "Built-in Cam Unmount and Mount Request.";
BA_ "Version" SG_ 2227254529 BAT_Crc1Val "21.09.03";
BA_ "RoutingFactor" SG_ 2227254529 BAT_Crc1Val 5;
BA_ "UserSigValidity" SG_ 2227254529 BAT_Crc1Val 7;
BA_ "GenSigStartValue" SG_ 2227254529 BAT_Crc1Val 65535;
BA_ "Description" SG_ 2227254529 BAT_Crc1Val "The data area for CRC calculation is based on the data length (DLC) of the message DB.

The CRC shall be calculated over the entire data block (excluding the CRC bytes) including the user data, alive counter and Data ID



- CRC Polynomial (0x1021) , Ini";
BA_ "Version" SG_ 2227254529 BAT_AlvCnt1Val "21.09.03";
BA_ "RoutingFactor" SG_ 2227254529 BAT_AlvCnt1Val 5;
BA_ "UserSigValidity" SG_ 2227254529 BAT_AlvCnt1Val 7;
BA_ "Description" SG_ 2227254529 BAT_AlvCnt1Val "For the first transmission request for a data element the counter shall be initialized with 0 and shall be incremented by 1 for every subsequent send request. 

When the counter reaches the maximum value(0xFF), then it shall restart with 0 for the next s";
BA_ "Version" SG_ 2227254529 BAT_CurrVal "17.11.00";
BA_ "RoutingFactor" SG_ 2227254529 BAT_CurrVal 5;
BA_ "UserSigValidity" SG_ 2227254529 BAT_CurrVal 7;
BA_ "GenSigStartValue" SG_ 2227254529 BAT_CurrVal 65535;
BA_ "Description" SG_ 2227254529 BAT_CurrVal "[For 12V Lithium Battery vehicle model]

This is Battery current as measured by battery sensor.

This value is  

   - IRANGE : 1 (medium current)

   - Resolution : 10mA";
BA_ "Version" SG_ 2227254529 BAT_SocVal "19.01.00";
BA_ "RoutingFactor" SG_ 2227254529 BAT_SocVal 5;
BA_ "UserSigValidity" SG_ 2227254529 BAT_SocVal 7;
BA_ "Description" SG_ 2227254529 BAT_SocVal "[For 12V Lithium Battery vehicle model]

This signal is battery State of Charge as calculated by battery sensor.";
BA_ "Version" SG_ 2227254529 BAT_VoltVal "17.11.00";
BA_ "RoutingFactor" SG_ 2227254529 BAT_VoltVal 5;
BA_ "UserSigValidity" SG_ 2227254529 BAT_VoltVal 7;
BA_ "GenSigStartValue" SG_ 2227254529 BAT_VoltVal 16383;
BA_ "Description" SG_ 2227254529 BAT_VoltVal "[For 12V Lithium Battery vehicle model]

This is the actual battery voltage as measured on the battery pole by battery sensor.

The Resolution is 1mV.";
BA_ "Version" SG_ 2227254529 BAT_AuxBattOpt "21.10.05";
BA_ "RoutingFactor" SG_ 2227254529 BAT_AuxBattOpt 5;
BA_ "UserSigValidity" SG_ 2227254529 BAT_AuxBattOpt 7;
BA_ "Description" SG_ 2227254529 BAT_AuxBattOpt "12V Battery Option Value(LFP 12V Battery)";
BA_ "Version" SG_ 2227254530 BAT_TempVal "20.03.05";
BA_ "RoutingFactor" SG_ 2227254530 BAT_TempVal 5;
BA_ "UserSigValidity" SG_ 2227254530 BAT_TempVal 7;
BA_ "GenSigStartValue" SG_ 2227254530 BAT_TempVal 511;
BA_ "Description" SG_ 2227254530 BAT_TempVal "This is actual battery electrolyte temperature value by battery sensor.

The value is calculated by a Battery Temperature Model, depending on measured temperature of the battery pole.

The resolution is 0.5¡É.";
BA_ "Version" SG_ 2227254530 BAT_SohVal "17.11.00";
BA_ "RoutingFactor" SG_ 2227254530 BAT_SohVal 5;
BA_ "UserSigValidity" SG_ 2227254530 BAT_SohVal 7;
BA_ "GenSigStartValue" SG_ 2227254530 BAT_SohVal 127;
BA_ "Description" SG_ 2227254530 BAT_SohVal "[For 12V Lithium Battery vehicle model]

This signal is battery State of Health(SOH) as calculated by battery sensor.

This value shows reduction rate of nominal capacity.

This value can be used for diagnosis information of application system.";
BA_ "Version" SG_ 2227254530 BAT_SnsrInvldSta "17.11.00";
BA_ "RoutingFactor" SG_ 2227254530 BAT_SnsrInvldSta 5;
BA_ "UserSigValidity" SG_ 2227254530 BAT_SnsrInvldSta 7;
BA_ "GenSigStartValue" SG_ 2227254530 BAT_SnsrInvldSta 1;
BA_ "Description" SG_ 2227254530 BAT_SnsrInvldSta "[For 12V Lithium Battery vehicle model]

This bit is Battery Sensor Invalid flag and setting condition is depending on Battery Sensor self diagnosis information.

 BS Invalid = 0 : BS is Valid Condition

 BS Invalid = 1 : BS is Invalid Condition";
BA_ "Version" SG_ 2227254530 BAT_SofVal "17.11.00";
BA_ "RoutingFactor" SG_ 2227254530 BAT_SofVal 5;
BA_ "UserSigValidity" SG_ 2227254530 BAT_SofVal 7;
BA_ "GenSigStartValue" SG_ 2227254530 BAT_SofVal 127;
BA_ "Description" SG_ 2227254530 BAT_SofVal "[For 12V Lithium Battery vehicle model]

This signal is battery State of Function(SOF) as calculated by battery sensor.

This value shows information about the battery ability to crank the engine (both of warm & cold cranking).

This value is prediction ";
BA_ "Version" SG_ 2227254530 BAT_RspErrSta "17.11.00";
BA_ "RoutingFactor" SG_ 2227254530 BAT_RspErrSta 5;
BA_ "UserSigValidity" SG_ 2227254530 BAT_RspErrSta 7;
BA_ "GenSigStartValue" SG_ 2227254530 BAT_RspErrSta 1;
BA_ "Description" SG_ 2227254530 BAT_RspErrSta "[For 12V Lithium Battery vehicle model]

Battery Sensor shall send one status bit signal, Response_Error. Response_Error shall be set whenever a frame received by the node or a frame transmitted by the node contains an error in the response field.

Respo";
BA_ "Version" SG_ 2227254530 BAT_CapacityVal "21.07.06";
BA_ "RoutingFactor" SG_ 2227254530 BAT_CapacityVal 5;
BA_ "UserSigValidity" SG_ 2227254530 BAT_CapacityVal 7;
BA_ "Description" SG_ 2227254530 BAT_CapacityVal "12V Battery Capacity Value";
BA_ "Version" SG_ 2227254530 BAT_SocErrSta "19.01.00";
BA_ "RoutingFactor" SG_ 2227254530 BAT_SocErrSta 5;
BA_ "UserSigValidity" SG_ 2227254530 BAT_SocErrSta 7;
BA_ "GenSigStartValue" SG_ 2227254530 BAT_SocErrSta 1;
BA_ "Description" SG_ 2227254530 BAT_SocErrSta "[For 12V Lithium Battery vehicle model]

This bit is flags for indication whether battery SOC detection value is plausible or not by battery sensor.

If it is set to value 0, then it means battery SOC is normal state.

If it is set to value 1, then it me";
BA_ "Version" SG_ 1266 HU_LanguageInfo "21.06.12";
BA_ "NetworkRequestHoldingTime" SG_ 1266 HU_LanguageInfo 5000;
BA_ "NetworkRequest" SG_ 1266 HU_LanguageInfo 0;
BA_ "UserSigValidity" SG_ 1266 HU_LanguageInfo 1;
BA_ "GenSigStartValue" SG_ 1266 HU_LanguageInfo 255;
BA_ "GenSigSendType" SG_ 1266 HU_LanguageInfo 4;
BA_ "Version" SG_ 1266 HU_MuteStatus "18.04.02";
BA_ "NetworkRequest" SG_ 1266 HU_MuteStatus 0;
BA_ "UserSigValidity" SG_ 1266 HU_MuteStatus 1;
BA_ "GenSigStartValue" SG_ 1266 HU_MuteStatus 3;
BA_ "GenSigSendType" SG_ 1266 HU_MuteStatus 4;
BA_ "Description" SG_ 1266 HU_MuteStatus "16.03.03_";
BA_ "Version" SG_ 1266 HU_WelcomeReady "22.07.05";
BA_ "UserSigValidity" SG_ 1266 HU_WelcomeReady 0;
BA_ "GenSigSendType" SG_ 1266 HU_WelcomeReady 4;
BA_ "Description" SG_ 1266 HU_WelcomeReady "H/U playback ready signal to play welcome/goodbye animation video.";
BA_ "Version" SG_ 1266 HU_UsmSupport "18.04.02";
BA_ "UserSigValidity" SG_ 1266 HU_UsmSupport 1;
BA_ "GenSigStartValue" SG_ 1266 HU_UsmSupport 3;
BA_ "GenSigSendType" SG_ 1266 HU_UsmSupport 4;
BA_ "Description" SG_ 1266 HU_UsmSupport "17.04.06_";
BA_ "Version" SG_ 1266 HU_NaviStatus "18.11.01";
BA_ "NetworkRequest" SG_ 1266 HU_NaviStatus 0;
BA_ "UserSigValidity" SG_ 1266 HU_NaviStatus 1;
BA_ "GenSigSendType" SG_ 1266 HU_NaviStatus 4;
BA_ "Description" SG_ 1266 HU_NaviStatus "18.11.00_";
BA_ "Version" SG_ 1266 HU_NaviDisp "18.04.02";
BA_ "NetworkRequest" SG_ 1266 HU_NaviDisp 0;
BA_ "UserSigValidity" SG_ 1266 HU_NaviDisp 1;
BA_ "GenSigStartValue" SG_ 1266 HU_NaviDisp 3;
BA_ "GenSigSendType" SG_ 1266 HU_NaviDisp 4;
BA_ "Description" SG_ 1266 HU_NaviDisp "16.03.03_";
BA_ "Version" SG_ 1266 HU_BVM_Display_Message "18.09.02";
BA_ "UserSigValidity" SG_ 1266 HU_BVM_Display_Message 3;
BA_ "GenSigStartValue" SG_ 1266 HU_BVM_Display_Message 7;
BA_ "GenSigSendType" SG_ 1266 HU_BVM_Display_Message 4;
BA_ "Description" SG_ 1266 HU_BVM_Display_Message "18.08.09_BVM Operation Message";
BA_ "Version" SG_ 1266 HU_SVM_View_Display "18.04.02";
BA_ "UserSigValidity" SG_ 1266 HU_SVM_View_Display 3;
BA_ "GenSigStartValue" SG_ 1266 HU_SVM_View_Display 31;
BA_ "GenSigSendType" SG_ 1266 HU_SVM_View_Display 4;
BA_ "Description" SG_ 1266 HU_SVM_View_Display "18.04.00_This signal indicates on/off BVM view on the cluster";
BA_ "Version" SG_ 1266 HU_NaviCamSettingStatus "18.09.02";
BA_ "NetworkRequest" SG_ 1266 HU_NaviCamSettingStatus 0;
BA_ "UserSigValidity" SG_ 1266 HU_NaviCamSettingStatus 1;
BA_ "GenSigStartValue" SG_ 1266 HU_NaviCamSettingStatus 255;
BA_ "GenSigSendType" SG_ 1266 HU_NaviCamSettingStatus 4;
BA_ "Description" SG_ 1266 HU_NaviCamSettingStatus "18.08.09_";
BA_ "Version" SG_ 1266 HU_EVSupport "19.08.06";
BA_ "UserSigValidity" SG_ 1266 HU_EVSupport 7;
BA_ "GenSigStartValue" SG_ 1266 HU_EVSupport 3;
BA_ "GenSigSendType" SG_ 1266 HU_EVSupport 4;
BA_ "Description" SG_ 1266 HU_EVSupport "Notification whether EV function support or not.";
BA_ "Version" SG_ 1266 HU_DayNightState "20.11.00";
BA_ "UserSigValidity" SG_ 1266 HU_DayNightState 0;
BA_ "GenSigSendType" SG_ 1266 HU_DayNightState 4;
BA_ "Description" SG_ 1266 HU_DayNightState "HU(AVNT) display day and night time state (When automatically adjusted)";
BA_ "Version" SG_ 1266 HU_AutoBrightState_New "20.09.01";
BA_ "UserSigValidity" SG_ 1266 HU_AutoBrightState_New 0;
BA_ "GenSigSendType" SG_ 1266 HU_AutoBrightState_New 4;
BA_ "Description" SG_ 1266 HU_AutoBrightState_New "HU Display Brightness State(When automatically adjusted)";
BA_ "Version" SG_ 1266 HU_VolumeStatus "18.04.02";
BA_ "NetworkRequest" SG_ 1266 HU_VolumeStatus 0;
BA_ "UserSigValidity" SG_ 1266 HU_VolumeStatus 1;
BA_ "GenSigStartValue" SG_ 1266 HU_VolumeStatus 63;
BA_ "GenSigSendType" SG_ 1266 HU_VolumeStatus 4;
BA_ "Description" SG_ 1266 HU_VolumeStatus "16.03.03_";
BA_ "Version" SG_ 1267 RSELockOnOff "19.11.11";
BA_ "NetworkRequestHoldingTime" SG_ 1267 RSELockOnOff 5000;
BA_ "NetworkRequest" SG_ 1267 RSELockOnOff 0;
BA_ "UserSigValidity" SG_ 1267 RSELockOnOff 1;
BA_ "GenSigStartValue" SG_ 1267 RSELockOnOff 3;
BA_ "GenSigSendType" SG_ 1267 RSELockOnOff 4;
BA_ "Version" SG_ 1267 HU_ClimateScrnState "22.07.05";
BA_ "UserSigValidity" SG_ 1267 HU_ClimateScrnState 7;
BA_ "GenSigStartValue" SG_ 1267 HU_ClimateScrnState 3;
BA_ "GenSigSendType" SG_ 1267 HU_ClimateScrnState 4;
BA_ "Description" SG_ 1267 HU_ClimateScrnState "AVNT Climate screen state";
BA_ "Version" SG_ 1267 HU_Graphreset_Info "18.09.04";
BA_ "UserSigValidity" SG_ 1267 HU_Graphreset_Info 1;
BA_ "GenSigStartValue" SG_ 1267 HU_Graphreset_Info 3;
BA_ "GenSigSendType" SG_ 1267 HU_Graphreset_Info 4;
BA_ "Description" SG_ 1267 HU_Graphreset_Info "18.08.09_";
BA_ "Version" SG_ 1267 HU_VRActivity "19.02.08";
BA_ "NetworkRequest" SG_ 1267 HU_VRActivity 0;
BA_ "UserSigValidity" SG_ 1267 HU_VRActivity 1;
BA_ "GenSigStartValue" SG_ 1267 HU_VRActivity 3;
BA_ "GenSigSendType" SG_ 1267 HU_VRActivity 4;
BA_ "Description" SG_ 1267 HU_VRActivity "18.08.09_";
BA_ "Version" SG_ 1267 HU_DATC_AirQuality_Info "18.09.04";
BA_ "UserSigValidity" SG_ 1267 HU_DATC_AirQuality_Info 3;
BA_ "GenSigStartValue" SG_ 1267 HU_DATC_AirQuality_Info 15;
BA_ "GenSigSendType" SG_ 1267 HU_DATC_AirQuality_Info 4;
BA_ "Description" SG_ 1267 HU_DATC_AirQuality_Info "18.08.09_";
BA_ "Version" SG_ 191 RL_SHVU_DTCdisplay "19.12.08";
BA_ "NetworkRequestHoldingTime" SG_ 191 RL_SHVU_DTCdisplay 5000;
BA_ "NetworkRequest" SG_ 191 RL_SHVU_DTCdisplay 0;
BA_ "UserSigValidity" SG_ 191 RL_SHVU_DTCdisplay 3;
BA_ "GenSigSendType" SG_ 191 RL_SHVU_DTCdisplay 4;
BA_ "Description" SG_ 191 RL_SHVU_DTCdisplay "0x00: DTC is not exist(Fail is not exist)/0x01:IGN2 Fuse Open Detection/0x02:Switch Input Detection at Same Time/0x03:NTC/Heating wire Open Detection/0x04:NTC+/NTC- Terminal Short Detection/0x05:NTC+/Heater+ Terminal Short Detection/0x06:NTC+/Heater-, He";
BA_ "Version" SG_ 191 RL_SHVU_DiagMode "19.12.08";
BA_ "NetworkRequestHoldingTime" SG_ 191 RL_SHVU_DiagMode 5000;
BA_ "NetworkRequest" SG_ 191 RL_SHVU_DiagMode 0;
BA_ "UserSigValidity" SG_ 191 RL_SHVU_DiagMode 3;
BA_ "GenSigSendType" SG_ 191 RL_SHVU_DiagMode 4;
BA_ "Description" SG_ 191 RL_SHVU_DiagMode "0x0:Default/0x1:DTC Mode/0x2:Normal Mode/0x3:Invalid";
BA_ "Version" SG_ 1264 HU_TimeSetting "18.09.02";
BA_ "NetworkRequest" SG_ 1264 HU_TimeSetting 0;
BA_ "UserSigValidity" SG_ 1264 HU_TimeSetting 0;
BA_ "GenSigStartValue" SG_ 1264 HU_TimeSetting 3;
BA_ "GenSigSendType" SG_ 1264 HU_TimeSetting 4;
BA_ "Description" SG_ 1264 HU_TimeSetting "18.08.09_";
BA_ "Version" SG_ 1264 HU_DisplayMinute "18.09.02";
BA_ "NetworkRequest" SG_ 1264 HU_DisplayMinute 0;
BA_ "UserSigValidity" SG_ 1264 HU_DisplayMinute 0;
BA_ "GenSigStartValue" SG_ 1264 HU_DisplayMinute 255;
BA_ "GenSigSendType" SG_ 1264 HU_DisplayMinute 4;
BA_ "Description" SG_ 1264 HU_DisplayMinute "18.08.09_";
BA_ "Version" SG_ 1264 HU_Status "18.09.02";
BA_ "NetworkRequest" SG_ 1264 HU_Status 0;
BA_ "UserSigValidity" SG_ 1264 HU_Status 0;
BA_ "GenSigStartValue" SG_ 1264 HU_Status 15;
BA_ "GenSigSendType" SG_ 1264 HU_Status 4;
BA_ "Description" SG_ 1264 HU_Status "18.08.09_";
BA_ "Version" SG_ 1264 HU_DisplaySecond "18.09.02";
BA_ "NetworkRequest" SG_ 1264 HU_DisplaySecond 0;
BA_ "UserSigValidity" SG_ 1264 HU_DisplaySecond 0;
BA_ "GenSigStartValue" SG_ 1264 HU_DisplaySecond 255;
BA_ "GenSigSendType" SG_ 1264 HU_DisplaySecond 4;
BA_ "Description" SG_ 1264 HU_DisplaySecond "18.08.09_";
BA_ "Version" SG_ 1264 HU_DisplayMonth "18.09.02";
BA_ "NetworkRequest" SG_ 1264 HU_DisplayMonth 0;
BA_ "UserSigValidity" SG_ 1264 HU_DisplayMonth 0;
BA_ "GenSigStartValue" SG_ 1264 HU_DisplayMonth 15;
BA_ "GenSigSendType" SG_ 1264 HU_DisplayMonth 4;
BA_ "Description" SG_ 1264 HU_DisplayMonth "18.08.09_";
BA_ "Version" SG_ 1264 HU_DisplayYear1 "18.09.02";
BA_ "NetworkRequest" SG_ 1264 HU_DisplayYear1 0;
BA_ "UserSigValidity" SG_ 1264 HU_DisplayYear1 0;
BA_ "GenSigStartValue" SG_ 1264 HU_DisplayYear1 3;
BA_ "GenSigSendType" SG_ 1264 HU_DisplayYear1 4;
BA_ "Description" SG_ 1264 HU_DisplayYear1 "18.08.09_";
BA_ "Version" SG_ 1264 HU_DisplayYear2 "18.09.02";
BA_ "NetworkRequest" SG_ 1264 HU_DisplayYear2 0;
BA_ "UserSigValidity" SG_ 1264 HU_DisplayYear2 0;
BA_ "GenSigStartValue" SG_ 1264 HU_DisplayYear2 255;
BA_ "GenSigSendType" SG_ 1264 HU_DisplayYear2 4;
BA_ "Description" SG_ 1264 HU_DisplayYear2 "18.08.09_";
BA_ "Version" SG_ 1264 HU_DisplayDay "18.09.02";
BA_ "NetworkRequest" SG_ 1264 HU_DisplayDay 0;
BA_ "UserSigValidity" SG_ 1264 HU_DisplayDay 0;
BA_ "GenSigStartValue" SG_ 1264 HU_DisplayDay 255;
BA_ "GenSigSendType" SG_ 1264 HU_DisplayDay 4;
BA_ "Description" SG_ 1264 HU_DisplayDay "18.08.09_";
BA_ "Version" SG_ 1264 HU_AM_PM_INFO "18.09.02";
BA_ "NetworkRequest" SG_ 1264 HU_AM_PM_INFO 0;
BA_ "UserSigValidity" SG_ 1264 HU_AM_PM_INFO 0;
BA_ "GenSigStartValue" SG_ 1264 HU_AM_PM_INFO 3;
BA_ "GenSigSendType" SG_ 1264 HU_AM_PM_INFO 4;
BA_ "Description" SG_ 1264 HU_AM_PM_INFO "18.08.09_";
BA_ "Version" SG_ 1264 HU_TimeFormat "18.09.02";
BA_ "NetworkRequest" SG_ 1264 HU_TimeFormat 0;
BA_ "UserSigValidity" SG_ 1264 HU_TimeFormat 0;
BA_ "GenSigStartValue" SG_ 1264 HU_TimeFormat 3;
BA_ "GenSigSendType" SG_ 1264 HU_TimeFormat 4;
BA_ "Description" SG_ 1264 HU_TimeFormat "18.08.09_";
BA_ "Version" SG_ 1264 HU_ComRefresh "18.09.02";
BA_ "NetworkRequest" SG_ 1264 HU_ComRefresh 0;
BA_ "UserSigValidity" SG_ 1264 HU_ComRefresh 0;
BA_ "GenSigStartValue" SG_ 1264 HU_ComRefresh 3;
BA_ "GenSigSendType" SG_ 1264 HU_ComRefresh 4;
BA_ "Description" SG_ 1264 HU_ComRefresh "18.08.09_";
BA_ "Version" SG_ 1264 HU_ClockInfo "18.09.02";
BA_ "NetworkRequest" SG_ 1264 HU_ClockInfo 0;
BA_ "UserSigValidity" SG_ 1264 HU_ClockInfo 0;
BA_ "GenSigStartValue" SG_ 1264 HU_ClockInfo 3;
BA_ "GenSigSendType" SG_ 1264 HU_ClockInfo 4;
BA_ "Description" SG_ 1264 HU_ClockInfo "18.08.09_";
BA_ "Version" SG_ 1264 HU_DisplayHour "18.09.02";
BA_ "NetworkRequest" SG_ 1264 HU_DisplayHour 0;
BA_ "UserSigValidity" SG_ 1264 HU_DisplayHour 0;
BA_ "GenSigStartValue" SG_ 1264 HU_DisplayHour 255;
BA_ "GenSigSendType" SG_ 1264 HU_DisplayHour 4;
BA_ "Description" SG_ 1264 HU_DisplayHour "18.08.09_";
BA_ "Version" SG_ 1265 HU_IG3_Request "20.03.05";
BA_ "UserSigValidity" SG_ 1265 HU_IG3_Request 0;
BA_ "GenSigStartValue" SG_ 1265 HU_IG3_Request 3;
BA_ "GenSigSendType" SG_ 1265 HU_IG3_Request 4;
BA_ "Description" SG_ 1265 HU_IG3_Request "IG3 wake up and sleep Request signal for EV/PHEV/HEV



Please apply this signal after checking ICU on your vehicle.";
BA_ "Version" SG_ 1265 HU_Background "21.01.06";
BA_ "UserSigValidity" SG_ 1265 HU_Background 1;
BA_ "GenSigStartValue" SG_ 1265 HU_Background 7;
BA_ "GenSigSendType" SG_ 1265 HU_Background 4;
BA_ "Description" SG_ 1265 HU_Background "HU Backgound image info";
BA_ "Version" SG_ 1265 ccIC_HUD_PbackSta "19.12.00";
BA_ "UserSigValidity" SG_ 1265 ccIC_HUD_PbackSta 3;
BA_ "GenSigSendType" SG_ 1265 ccIC_HUD_PbackSta 4;
BA_ "Description" SG_ 1265 ccIC_HUD_PbackSta "Status signal for HUD interoperation with IMS

(The number of memory is expanded.)";
BA_ "Version" SG_ 1265 HU_BackgroundFadeInOut "21.01.06";
BA_ "UserSigValidity" SG_ 1265 HU_BackgroundFadeInOut 1;
BA_ "GenSigStartValue" SG_ 1265 HU_BackgroundFadeInOut 1023;
BA_ "GenSigSendType" SG_ 1265 HU_BackgroundFadeInOut 4;
BA_ "Description" SG_ 1265 HU_BackgroundFadeInOut "HU Background Fade in/out info

(HEX * Factor) %";
BA_ "Version" SG_ 1265 CF_AVN_AutoWashModeSta "22.07.05";
BA_ "UserSigValidity" SG_ 1265 CF_AVN_AutoWashModeSta 3;
BA_ "GenSigSendType" SG_ 1265 CF_AVN_AutoWashModeSta 4;
BA_ "Description" SG_ 1265 CF_AVN_AutoWashModeSta "Washer Mode status signal";
BA_ "Version" SG_ 1265 OMUOSMirCtrl_Vr "22.05.04";
BA_ "UserSigValidity" SG_ 1265 OMUOSMirCtrl_Vr 3;
BA_ "GenSigStartValue" SG_ 1265 OMUOSMirCtrl_Vr 3;
BA_ "GenSigSendType" SG_ 1265 OMUOSMirCtrl_Vr 4;
BA_ "Version" SG_ 2328016132 VCU_LowSocDispPcVal "21.03.00";
BA_ "RoutingFactor" SG_ 2328016132 VCU_LowSocDispPcVal 2;
BA_ "UserSigValidity" SG_ 2328016132 VCU_LowSocDispPcVal 7;
BA_ "TimeoutValue" SG_ 2328016132 VCU_LowSocDispPcVal "0x0";
BA_ "Description" SG_ 2328016132 VCU_LowSocDispPcVal "Low SOC Display Percent Value";
BA_ "Version" SG_ 2328016132 VCU_DteSocBasedVal "20.12.04";
BA_ "RoutingFactor" SG_ 2328016132 VCU_DteSocBasedVal 2;
BA_ "UserSigValidity" SG_ 2328016132 VCU_DteSocBasedVal 7;
BA_ "Description" SG_ 2328016132 VCU_DteSocBasedVal "Maximum Drivable Distance with Soc Based (China Only Func)";
BA_ "Version" SG_ 2328016132 VCU_InstFuelEcoVal_Per100km "19.03.03";
BA_ "RoutingFactor" SG_ 2328016132 VCU_InstFuelEcoVal_Per100km 2;
BA_ "UserSigValidity" SG_ 2328016132 VCU_InstFuelEcoVal_Per100km 7;
BA_ "Description" SG_ 2328016132 VCU_InstFuelEcoVal_Per100km "Instant Fuel Economy(kWh/100km)";
BA_ "Version" SG_ 2328016132 VCU_InstFuelEcoVal_PerkWh "19.03.03";
BA_ "RoutingFactor" SG_ 2328016132 VCU_InstFuelEcoVal_PerkWh 2;
BA_ "UserSigValidity" SG_ 2328016132 VCU_InstFuelEcoVal_PerkWh 7;
BA_ "Description" SG_ 2328016132 VCU_InstFuelEcoVal_PerkWh "Fuel Economy in EV";
BA_ "Version" SG_ 2328016132 VCU_CO2RdcTripDistVal "19.03.03";
BA_ "RoutingFactor" SG_ 2328016132 VCU_CO2RdcTripDistVal 2;
BA_ "UserSigValidity" SG_ 2328016132 VCU_CO2RdcTripDistVal 7;
BA_ "Description" SG_ 2328016132 VCU_CO2RdcTripDistVal "Trip Distance for CO2 Reduction";
BA_ "Version" SG_ 2328016132 VCU_CO2RdcVal "19.03.03";
BA_ "RoutingFactor" SG_ 2328016132 VCU_CO2RdcVal 2;
BA_ "UserSigValidity" SG_ 2328016132 VCU_CO2RdcVal 7;
BA_ "Description" SG_ 2328016132 VCU_CO2RdcVal "CO2 Reduction Amount(Integrated Value)";
BA_ "Version" SG_ 2328016132 VCU_StopCtrlWarnMsgSta "21.12.02";
BA_ "RoutingFactor" SG_ 2328016132 VCU_StopCtrlWarnMsgSta 2;
BA_ "UserSigValidity" SG_ 2328016132 VCU_StopCtrlWarnMsgSta 7;
BA_ "Description" SG_ 2328016132 VCU_StopCtrlWarnMsgSta "i-Pedal Warning Message Status";
BA_ "Version" SG_ 2328016132 VCU_DrvModeDefault "21.09.07";
BA_ "RoutingFactor" SG_ 2328016132 VCU_DrvModeDefault 2;
BA_ "UserSigValidity" SG_ 2328016132 VCU_DrvModeDefault 7;
BA_ "Description" SG_ 2328016132 VCU_DrvModeDefault "This signal is the drive mode that needs to return to default on initial strat-up and restart. 

This signal is only used for cluster display.";
BA_ "Version" SG_ 2328016132 VCU_DrvModeLast "21.09.07";
BA_ "RoutingFactor" SG_ 2328016132 VCU_DrvModeLast 2;
BA_ "UserSigValidity" SG_ 2328016132 VCU_DrvModeLast 7;
BA_ "Description" SG_ 2328016132 VCU_DrvModeLast "This signal is the drive mode that needs to maintain on restart.This signal is only used for cluster display* If BitX is 1, the drive mode remains in the last mode on restart.* If BitX is 0, the drive mode returns to default mode on restart.";
BA_ "Version" SG_ 1278 HU_Type "21.05.00";
BA_ "NetworkRequestHoldingTime" SG_ 1278 HU_Type 7000;
BA_ "NetworkRequest" SG_ 1278 HU_Type 0;
BA_ "UserSigValidity" SG_ 1278 HU_Type 1;
BA_ "GenSigStartValue" SG_ 1278 HU_Type 255;
BA_ "GenSigSendType" SG_ 1278 HU_Type 4;
BA_ "Version" SG_ 1278 HU_DistributeInfo "20.09.00";
BA_ "NetworkRequestHoldingTime" SG_ 1278 HU_DistributeInfo 7000;
BA_ "NetworkRequest" SG_ 1278 HU_DistributeInfo 0;
BA_ "UserSigValidity" SG_ 1278 HU_DistributeInfo 1;
BA_ "GenSigStartValue" SG_ 1278 HU_DistributeInfo 255;
BA_ "GenSigSendType" SG_ 1278 HU_DistributeInfo 4;
BA_ "Version" SG_ 1278 HU_OptionInfo "21.04.03";
BA_ "UserSigValidity" SG_ 1278 HU_OptionInfo 0;
BA_ "GenSigStartValue" SG_ 1278 HU_OptionInfo 32768;
BA_ "GenSigSendType" SG_ 1278 HU_OptionInfo 4;
BA_ "Description" SG_ 1278 HU_OptionInfo "Bit0 : Navi (0: Not Support / 1: Support)

Bit1 : USM (0: Not Support / 1: Support)

Bit2 : TMS (0: Not Support / 1: Support)

Bit3 : Multi Profile (0: Not Support(No Profile or Single Profile)  / 1: Support)

Bit4 : Camera Guideline (0: Displayed by Cam";
BA_ "Version" SG_ 1278 HU_NaviMapInfo "20.05.03";
BA_ "UserSigValidity" SG_ 1278 HU_NaviMapInfo 1;
BA_ "GenSigSendType" SG_ 1278 HU_NaviMapInfo 4;
BA_ "Description" SG_ 1278 HU_NaviMapInfo "Information about map data  used in Navigation";
BA_ "Version" SG_ 1278 HU_NaviHandshakingSupport "20.05.02";
BA_ "UserSigValidity" SG_ 1278 HU_NaviHandshakingSupport 1;
BA_ "GenSigSendType" SG_ 1278 HU_NaviHandshakingSupport 4;
BA_ "Description" SG_ 1278 HU_NaviHandshakingSupport "This is a signal to send whether handshaking logic is applied related to Navigation's 'Map based ADAS' specification";
BA_ "Version" SG_ 1278 HU_AMP_EQVariant "20.08.06";
BA_ "UserSigValidity" SG_ 1278 HU_AMP_EQVariant 1;
BA_ "GenSigStartValue" SG_ 1278 HU_AMP_EQVariant 31;
BA_ "GenSigSendType" SG_ 1278 HU_AMP_EQVariant 4;
BA_ "Version" SG_ 1278 HU_AdasSupport "20.05.02";
BA_ "NetworkRequestHoldingTime" SG_ 1278 HU_AdasSupport 5000;
BA_ "NetworkRequest" SG_ 1278 HU_AdasSupport 0;
BA_ "UserSigValidity" SG_ 1278 HU_AdasSupport 1;
BA_ "GenSigStartValue" SG_ 1278 HU_AdasSupport 7;
BA_ "GenSigSendType" SG_ 1278 HU_AdasSupport 4;
BA_ "Description" SG_ 1278 HU_AdasSupport "0x0 : Not Support

0x1 : ADAS Support (General Map) - Send map information based on General Map

0x2 : ADAS Support (Map based ADAS v1) - Send map information based on Map based ADAS v1 or v1.5

0x3 : ADAS Support (Map based ADAS v2) - Send map informati";
BA_ "Version" SG_ 1278 HU_Navi_RspADASMapMsg "21.11.04";
BA_ "UserSigValidity" SG_ 1278 HU_Navi_RspADASMapMsg 3;
BA_ "GenSigSendType" SG_ 1278 HU_Navi_RspADASMapMsg 4;
BA_ "Description" SG_ 1278 HU_Navi_RspADASMapMsg "This signal indicates an ADAS map message response from H_U to ECU 

which is stored the  required Map based ADAS messages for each ECU



Each bit indicates the request messages as follows.

(1: Sending message / 0 : Doens't sending message)

- Bit 0 : ";
BA_REL_ "GenSigTimeoutTime" BU_SG_REL_ APSU SG_ 1218 CF_AVN_RRPSU_RLNValueSet 0;
BA_REL_ "GenSigTimeoutTime" BU_SG_REL_ RRPSU SG_ 1218 CF_AVN_RRPSU_RLNValueSet 0;
BA_REL_ "GenSigTimeoutTime" BU_SG_REL_ APSU SG_ 1218 CF_AVN_APSUNValueSet 0;
BA_REL_ "GenSigTimeoutTime" BU_SG_REL_ ASAU SG_ 1218 CF_AVN_APSUNValueSet 0;
BA_REL_ "GenSigTimeoutTime" BU_SG_REL_ APSU SG_ 1218 CF_AVN_RRPSU_RRNValueSet 0;
BA_REL_ "GenSigTimeoutTime" BU_SG_REL_ RRPSU SG_ 1218 CF_AVN_RRPSU_RRNValueSet 0;
BA_REL_ "GenSigTimeoutTime" BU_SG_REL_ APSU SG_ 1218 CF_AVN_HtBlcAstNValueSet 0;
BA_REL_ "GenSigTimeoutTime" BU_SG_REL_ SHVU_FR SG_ 1218 CF_AVN_HtBlcAstNValueSet 0;
BA_REL_ "GenSigTimeoutTime" BU_SG_REL_ APSU SG_ 1218 CF_AVN_HtBlcDrvNValueSet 0;
BA_REL_ "GenSigTimeoutTime" BU_SG_REL_ SHVU_FR SG_ 1218 CF_AVN_HtBlcDrvNValueSet 0;
BA_REL_ "GenSigTimeoutTime" BU_SG_REL_ DPSU SG_ 2323816450 C_EsyAcsProfileID_CCU 0;
BA_REL_ "GenSigTimeoutTime" BU_SG_REL_ SHVU_FR SG_ 2323816449 C_TeleDrvSeatOpCmdIBOX_Copy_2 0;
BA_REL_ "GenSigTimeoutTime" BU_SG_REL_ DPSU SG_ 2323816449 C_TeleDrvSeatOpCmdIBOX_Copy_2 0;
BA_REL_ "GenSigTimeoutTime" BU_SG_REL_ APSU SG_ 2323816449 C_TeleAstSeatOpCmdIBOX_Copy_2 0;
BA_REL_ "GenSigTimeoutTime" BU_SG_REL_ SHVU_FR SG_ 2323816449 C_TeleAstSeatOpCmdIBOX_Copy_2 0;
BA_REL_ "GenSigTimeoutTime" BU_SG_REL_ RRHV SG_ 2323816449 C_TeleRRSeatOpCmdIBOX_Copy_2 0;
BA_REL_ "GenSigTimeoutTime" BU_SG_REL_ SHVU_FR SG_ 2323816449 C_TeleRRSeatOpCmdIBOX_Copy_2 0;
BA_REL_ "GenSigTimeoutTime" BU_SG_REL_ SHVU_RR SG_ 2323816449 C_TeleRRSeatOpCmdIBOX_Copy_2 0;
BA_REL_ "GenSigTimeoutTime" BU_SG_REL_ RRPSU SG_ 2323816449 C_TeleRRSeatOpCmdIBOX_Copy_2 0;
BA_REL_ "GenSigTimeoutTime" BU_SG_REL_ ATS SG_ 2323816449 C_TeleRRSeatOpCmdIBOX_Copy_2 0;
BA_REL_ "GenSigTimeoutTime" BU_SG_REL_ RLHV SG_ 2323816449 C_TeleRLSeatOpCmdIBOX_Copy_1 0;
BA_REL_ "GenSigTimeoutTime" BU_SG_REL_ SHVU_FR SG_ 2323816449 C_TeleRLSeatOpCmdIBOX_Copy_1 0;
BA_REL_ "GenSigTimeoutTime" BU_SG_REL_ SHVU_RR SG_ 2323816449 C_TeleRLSeatOpCmdIBOX_Copy_1 0;
BA_REL_ "GenSigTimeoutTime" BU_SG_REL_ RLPSU SG_ 2323816449 C_TeleRLSeatOpCmdIBOX_Copy_1 0;
BA_REL_ "GenSigTimeoutTime" BU_SG_REL_ ATS SG_ 2323816449 C_TeleRLSeatOpCmdIBOX_Copy_1 0;
BA_REL_ "GenSigTimeoutTime" BU_SG_REL_ CGW_CCU SG_ 1227 DrvIMS_MemoryP1Req 0;
BA_REL_ "GenSigTimeoutTime" BU_SG_REL_ CGW_CCU SG_ 1227 DrvIMS_PlyBckP2Req 0;
BA_REL_ "GenSigTimeoutTime" BU_SG_REL_ CGW_CCU SG_ 1227 DrvIMS_PlyBckP3Req 0;
BA_REL_ "GenSigTimeoutTime" BU_SG_REL_ CGW_CCU SG_ 1227 DrvIMS_PlyBckStpReq 0;
BA_REL_ "GenSigTimeoutTime" BU_SG_REL_ CGW_CCU SG_ 1227 SmrtIMS_PlyBckReq 0;
BA_REL_ "GenSigTimeoutTime" BU_SG_REL_ CGW_CCU SG_ 1227 DrvIMS_MemoryP2Req 0;
BA_REL_ "GenSigTimeoutTime" BU_SG_REL_ CGW_CCU SG_ 1227 PSM_IMSReq 0;
BA_REL_ "GenSigTimeoutTime" BU_SG_REL_ CGW_CCU SG_ 1227 SmrtIMS_ImgDBVal 0;
BA_REL_ "GenSigTimeoutTime" BU_SG_REL_ CGW_CCU SG_ 1227 SmrtIMS_PlyBckStpReq 0;
BA_REL_ "GenSigTimeoutTime" BU_SG_REL_ CGW_CCU SG_ 1227 DrvIMS_MemoryP3Req 0;
BA_REL_ "GenSigTimeoutTime" BU_SG_REL_ CGW_CCU SG_ 1227 SmrtIMS_EnterSwSta 0;
BA_REL_ "GenSigTimeoutTime" BU_SG_REL_ CGW_CCU SG_ 1227 DrvIMS_BzrReq 0;
BA_REL_ "GenSigTimeoutTime" BU_SG_REL_ CGW_CCU SG_ 1227 DrvIMS_ErrConWmgDis 0;
BA_REL_ "GenSigTimeoutTime" BU_SG_REL_ CGW_CCU SG_ 1227 PSM_DrvRlxReturn_Req 0;
BA_REL_ "GenSigTimeoutTime" BU_SG_REL_ CGW_CCU SG_ 1227 Drv_AutoRlxWrngDis 0;
BA_REL_ "GenSigTimeoutTime" BU_SG_REL_ CGW_CCU SG_ 1227 DrvIMS_MemorySetEnaSta 0;
BA_REL_ "GenSigTimeoutTime" BU_SG_REL_ CGW_CCU SG_ 1227 DrvIMS_PlyBckP1Req 0;
BA_REL_ "GenSigTimeoutTime" BU_SG_REL_ CGW_CCU SG_ 1237 Audio_VolEncoderSta 0;
BA_REL_ "GenSigTimeoutTime" BU_SG_REL_ CGW_CCU SG_ 1237 Cluster_ScrlEncoderSta 0;
BA_REL_ "GenSigTimeoutTime" BU_SG_REL_ BLTN_CAM SG_ 1239 HU_PwrState 1500;
BA_REL_ "GenSigTimeoutTime" BU_SG_REL_ BLTN_CAM SG_ 1239 HU_VehiclePwr 1500;
BA_REL_ "GenSigTimeoutTime" BU_SG_REL_ SGU SG_ 1239 HU_VehiclePwr 1500;
BA_REL_ "GenSigTimeoutTime" BU_SG_REL_ SWRC SG_ 1239 HU_BtnShowReq 1500;
BA_REL_ "GenSigTimeoutTime" BU_SG_REL_ CGW_CCU SG_ 157 ATS_DATC_FrDrTempSetC 0;
BA_REL_ "GenSigTimeoutTime" BU_SG_REL_ CGW_CCU SG_ 157 ATS_DATC_RrDrBlowerUpDn 0;
BA_REL_ "GenSigTimeoutTime" BU_SG_REL_ CGW_CCU SG_ 157 ATS_DATC_FrSyncSet 0;
BA_REL_ "GenSigTimeoutTime" BU_SG_REL_ CGW_CCU SG_ 157 ATS_DATC_RrDrTempSetC 0;
BA_REL_ "GenSigTimeoutTime" BU_SG_REL_ CGW_CCU SG_ 157 ATS_DATC_RrDrTempSetF 0;
BA_REL_ "GenSigTimeoutTime" BU_SG_REL_ CGW_CCU SG_ 157 ATS_DATC_FrPsTempSetC 0;
BA_REL_ "GenSigTimeoutTime" BU_SG_REL_ CGW_CCU SG_ 157 ATS_DATC_FrPsTempSetF 0;
BA_REL_ "GenSigTimeoutTime" BU_SG_REL_ CGW_CCU SG_ 157 ATS_DATC_FrDrTempSetF 0;
BA_REL_ "GenSigTimeoutTime" BU_SG_REL_ CGW_CCU SG_ 158 ATS_DATC_FrDrBlowerSet 0;
BA_REL_ "GenSigTimeoutTime" BU_SG_REL_ CGW_CCU SG_ 158 ATS_DATC_RrDrTempUpDn 0;
BA_REL_ "GenSigTimeoutTime" BU_SG_REL_ CGW_CCU SG_ 158 ATS_DATC_RrDrBlowerSet 0;
BA_REL_ "GenSigTimeoutTime" BU_SG_REL_ CGW_CCU SG_ 158 ATS_DATC_RrDrModeSet 0;
BA_REL_ "GenSigTimeoutTime" BU_SG_REL_ CGW_CCU SG_ 158 ATS_DATC_FrDrModeSet 0;
BA_REL_ "GenSigTimeoutTime" BU_SG_REL_ CGW_CCU SG_ 158 ATS_DATC_IntakeSet 0;
BA_REL_ "GenSigTimeoutTime" BU_SG_REL_ CGW_CCU SG_ 158 ATS_DATC_FrDrAutoSet 0;
BA_REL_ "GenSigTimeoutTime" BU_SG_REL_ CGW_CCU SG_ 158 ATS_DATC_FrPsTempUpDn 0;
BA_REL_ "GenSigTimeoutTime" BU_SG_REL_ CGW_CCU SG_ 158 ATS_DATC_FrDefog 0;
BA_REL_ "GenSigTimeoutTime" BU_SG_REL_ CGW_CCU SG_ 158 ATS_DATC_RrSyncSet 0;
BA_REL_ "GenSigTimeoutTime" BU_SG_REL_ CGW_CCU SG_ 158 ATS_DATC_AcSet 0;
BA_REL_ "GenSigTimeoutTime" BU_SG_REL_ CGW_CCU SG_ 158 ATS_DATC_AirCleaningSet 0;
BA_REL_ "GenSigTimeoutTime" BU_SG_REL_ CGW_CCU SG_ 158 ATS_DATC_FrDrBlowerUpDn 0;
BA_REL_ "GenSigTimeoutTime" BU_SG_REL_ CGW_CCU SG_ 158 ATS_DATC_FrDrTempUpDn 0;
BA_REL_ "GenSigTimeoutTime" BU_SG_REL_ CGW_CCU SG_ 158 ATS_DATC_RrDrAutoSet 0;
BA_REL_ "GenSigTimeoutTime" BU_SG_REL_ RCM SG_ 1247 Navi_AirConditionWarning 1500;
BA_REL_ "GenSigTimeoutTime" BU_SG_REL_ ATS SG_ 1240 HU_ThemeType 1500;
BA_REL_ "GenSigTimeoutTime" BU_SG_REL_ BLTN_CAM SG_ 1240 HU_ThemeType 1500;
BA_REL_ "GenSigTimeoutTime" BU_SG_REL_ WPC SG_ 1240 CF_AVN_ProfileIDRValue 1500;
BA_REL_ "GenSigTimeoutTime" BU_SG_REL_ RWPC SG_ 1240 CF_AVN_ProfileIDRValue 1500;
BA_REL_ "GenSigTimeoutTime" BU_SG_REL_ DPSU SG_ 1240 CF_AVN_ProfileIDRValue 1500;
BA_REL_ "GenSigTimeoutTime" BU_SG_REL_ DLBCU SG_ 1240 CF_AVN_ProfileIDRValue 1500;
BA_REL_ "GenSigTimeoutTime" BU_SG_REL_ RCM SG_ 1240 CF_AVN_ProfileIDRValue 1500;
BA_REL_ "GenSigTimeoutTime" BU_SG_REL_ BLTN_CAM SG_ 1240 CF_AVN_ProfileIDRValue 1500;
BA_REL_ "GenSigTimeoutTime" BU_SG_REL_ SGU SG_ 1240 CF_AVN_ProfileIDRValue 1500;
BA_REL_ "GenSigTimeoutTime" BU_SG_REL_ WPC2 SG_ 1240 CF_AVN_ProfileIDRValue 1500;
BA_REL_ "GenSigTimeoutTime" BU_SG_REL_ APSU SG_ 1240 HU_RTCCheck 1500;
BA_REL_ "GenSigTimeoutTime" BU_SG_REL_ APSU SG_ 2424580353 DATC_FRStHtrSwReq 1500;
BA_REL_ "GenSigTimeoutTime" BU_SG_REL_ SHVU_FR SG_ 2424580353 DATC_FRStHtrSwReq 1500;
BA_REL_ "GenSigTimeoutTime" BU_SG_REL_ SHVU_RR SG_ 2424580353 DATC_FRStHtrSwReq 1500;
BA_REL_ "GenSigTimeoutTime" BU_SG_REL_ DPSU SG_ 2424580353 DATC_FRStHtrSwReq 1500;
BA_REL_ "GenSigTimeoutTime" BU_SG_REL_ APSU SG_ 2424580353 DATC_FRStVentSwReq 1500;
BA_REL_ "GenSigTimeoutTime" BU_SG_REL_ SHVU_FR SG_ 2424580353 DATC_FRStVentSwReq 1500;
BA_REL_ "GenSigTimeoutTime" BU_SG_REL_ SHVU_RR SG_ 2424580353 DATC_FRStVentSwReq 1500;
BA_REL_ "GenSigTimeoutTime" BU_SG_REL_ DPSU SG_ 2424580353 DATC_FRStVentSwReq 1500;
BA_REL_ "GenSigTimeoutTime" BU_SG_REL_ APSU SG_ 2424580353 DATC_FLStOpReq 1500;
BA_REL_ "GenSigTimeoutTime" BU_SG_REL_ SHVU_FR SG_ 2424580353 DATC_FLStOpReq 1500;
BA_REL_ "GenSigTimeoutTime" BU_SG_REL_ SHVU_RR SG_ 2424580353 DATC_FLStOpReq 1500;
BA_REL_ "GenSigTimeoutTime" BU_SG_REL_ DPSU SG_ 2424580353 DATC_FLStOpReq 1500;
BA_REL_ "GenSigTimeoutTime" BU_SG_REL_ APSU SG_ 2424580353 DATC_FRStOpReq 1500;
BA_REL_ "GenSigTimeoutTime" BU_SG_REL_ SHVU_FR SG_ 2424580353 DATC_FRStOpReq 1500;
BA_REL_ "GenSigTimeoutTime" BU_SG_REL_ SHVU_RR SG_ 2424580353 DATC_FRStOpReq 1500;
BA_REL_ "GenSigTimeoutTime" BU_SG_REL_ APSU SG_ 2424580353 DATC_FLStHtrSwReq 1500;
BA_REL_ "GenSigTimeoutTime" BU_SG_REL_ SHVU_FR SG_ 2424580353 DATC_FLStHtrSwReq 1500;
BA_REL_ "GenSigTimeoutTime" BU_SG_REL_ SHVU_RR SG_ 2424580353 DATC_FLStHtrSwReq 1500;
BA_REL_ "GenSigTimeoutTime" BU_SG_REL_ DPSU SG_ 2424580353 DATC_FLStHtrSwReq 1500;
BA_REL_ "GenSigTimeoutTime" BU_SG_REL_ APSU SG_ 2424580353 DATC_FLStVentSwReq 1500;
BA_REL_ "GenSigTimeoutTime" BU_SG_REL_ SHVU_FR SG_ 2424580353 DATC_FLStVentSwReq 1500;
BA_REL_ "GenSigTimeoutTime" BU_SG_REL_ SHVU_RR SG_ 2424580353 DATC_FLStVentSwReq 1500;
BA_REL_ "GenSigTimeoutTime" BU_SG_REL_ DPSU SG_ 2424580353 DATC_FLStVentSwReq 1500;
BA_REL_ "GenSigTimeoutTime" BU_SG_REL_ APSU SG_ 2424580353 DATC_FLStTmblrSwReq 1500;
BA_REL_ "GenSigTimeoutTime" BU_SG_REL_ SHVU_FR SG_ 2424580353 DATC_FLStTmblrSwReq 1500;
BA_REL_ "GenSigTimeoutTime" BU_SG_REL_ APSU SG_ 2424580353 DATC_FRStTmblrSwReq 1500;
BA_REL_ "GenSigTimeoutTime" BU_SG_REL_ SHVU_FR SG_ 2424580353 DATC_FRStTmblrSwReq 1500;
BA_REL_ "GenSigTimeoutTime" BU_SG_REL_ RRHV SG_ 2424580353 DATC_RRStHtrSwReq 1500;
BA_REL_ "GenSigTimeoutTime" BU_SG_REL_ SHVU_FR SG_ 2424580353 DATC_RRStHtrSwReq 1500;
BA_REL_ "GenSigTimeoutTime" BU_SG_REL_ SHVU_RR SG_ 2424580353 DATC_RRStHtrSwReq 1500;
BA_REL_ "GenSigTimeoutTime" BU_SG_REL_ RRPSU SG_ 2424580353 DATC_RRStHtrSwReq 1500;
BA_REL_ "GenSigTimeoutTime" BU_SG_REL_ RRHV SG_ 2424580353 DATC_RRStVentSwReq 1500;
BA_REL_ "GenSigTimeoutTime" BU_SG_REL_ SHVU_FR SG_ 2424580353 DATC_RRStVentSwReq 1500;
BA_REL_ "GenSigTimeoutTime" BU_SG_REL_ SHVU_RR SG_ 2424580353 DATC_RRStVentSwReq 1500;
BA_REL_ "GenSigTimeoutTime" BU_SG_REL_ RRPSU SG_ 2424580353 DATC_RRStVentSwReq 1500;
BA_REL_ "GenSigTimeoutTime" BU_SG_REL_ RLHV SG_ 2424580353 DATC_RLStHtrSwReq 1500;
BA_REL_ "GenSigTimeoutTime" BU_SG_REL_ SHVU_FR SG_ 2424580353 DATC_RLStHtrSwReq 1500;
BA_REL_ "GenSigTimeoutTime" BU_SG_REL_ SHVU_RR SG_ 2424580353 DATC_RLStHtrSwReq 1500;
BA_REL_ "GenSigTimeoutTime" BU_SG_REL_ RLPSU SG_ 2424580353 DATC_RLStHtrSwReq 1500;
BA_REL_ "GenSigTimeoutTime" BU_SG_REL_ RLHV SG_ 2424580353 DATC_RLStVentSwReq 1500;
BA_REL_ "GenSigTimeoutTime" BU_SG_REL_ SHVU_FR SG_ 2424580353 DATC_RLStVentSwReq 1500;
BA_REL_ "GenSigTimeoutTime" BU_SG_REL_ SHVU_RR SG_ 2424580353 DATC_RLStVentSwReq 1500;
BA_REL_ "GenSigTimeoutTime" BU_SG_REL_ RLPSU SG_ 2424580353 DATC_RLStVentSwReq 1500;
BA_REL_ "GenSigTimeoutTime" BU_SG_REL_ ATS SG_ 2424580353 DATC_RRSyncDis 1500;
BA_REL_ "GenSigTimeoutTime" BU_SG_REL_ CGW_CCU SG_ 171 BLTN_CAM_UI_Mode_Tmt_Req 0;
BA_REL_ "GenSigTimeoutTime" BU_SG_REL_ CGW_CCU SG_ 171 BLTN_CAM_PopUp_Req 0;
BA_REL_ "GenSigTimeoutTime" BU_SG_REL_ CGW_CCU SG_ 171 BLTN_CAM_File_List_Renew 0;
BA_REL_ "GenSigTimeoutTime" BU_SG_REL_ CGW_CCU SG_ 171 BLTN_CAM_Wifi_Pwd_Chg_State 0;
BA_REL_ "GenSigTimeoutTime" BU_SG_REL_ DPSU SG_ 1253 Auth_Method 0;
BA_REL_ "GenSigTimeoutTime" BU_SG_REL_ DPSU SG_ 1253 Auth_Event 0;
BA_REL_ "GenSigTimeoutTime" BU_SG_REL_ ATS SG_ 1252 RKE_BtnReq 0;
BA_REL_ "GenSigTimeoutTime" BU_SG_REL_ RCM SG_ 1252 RKE_WdwUpDnReq 0;
BA_REL_ "GenSigTimeoutTime" BU_SG_REL_ DPSU SG_ 1251 IAU_EsyAcsProfileID 0;
BA_REL_ "GenSigTimeoutTime" BU_SG_REL_ BLTN_CAM SG_ 172 BLTN_CAM_FR_VerPos_NvalueSet 0;
BA_REL_ "GenSigTimeoutTime" BU_SG_REL_ BLTN_CAM SG_ 172 BLTN_CAM_AppNoti_PEV_NvalueSet 0;
BA_REL_ "GenSigTimeoutTime" BU_SG_REL_ BLTN_CAM SG_ 172 BLTN_CAM_WiFi_AutoOn_NvalueSet 0;
BA_REL_ "GenSigTimeoutTime" BU_SG_REL_ BLTN_CAM SG_ 172 BLTN_CAM_StoProp_NvalueSet 0;
BA_REL_ "GenSigTimeoutTime" BU_SG_REL_ BLTN_CAM SG_ 172 CF_AVN_BLTN_CAM_USMReset 0;
BA_REL_ "GenSigTimeoutTime" BU_SG_REL_ BLTN_CAM SG_ 172 CF_AVN_BLTN_CAM_RecReset 0;
BA_REL_ "GenSigTimeoutTime" BU_SG_REL_ BLTN_CAM SG_ 172 BLTN_CAM_File_DEL_CPY_Cmd 0;
BA_REL_ "GenSigTimeoutTime" BU_SG_REL_ BLTN_CAM SG_ 172 BLTN_CAM_LVDS_Mode_Cmd 0;
BA_REL_ "GenSigTimeoutTime" BU_SG_REL_ BLTN_CAM SG_ 172 HU_BLTN_CAM_Disp_Touch_Pos_X 0;
BA_REL_ "GenSigTimeoutTime" BU_SG_REL_ BLTN_CAM SG_ 172 HU_BLTN_CAM_Disp_Touch_Pos_Y 0;
BA_REL_ "GenSigTimeoutTime" BU_SG_REL_ BLTN_CAM SG_ 172 MEV_Rec_Req 0;
BA_REL_ "GenSigTimeoutTime" BU_SG_REL_ BLTN_CAM SG_ 172 BLTN_CAM_RR_VerPos_NvalueSet 0;
BA_REL_ "GenSigTimeoutTime" BU_SG_REL_ BLTN_CAM SG_ 172 TML_Rec_Req 0;
BA_REL_ "GenSigTimeoutTime" BU_SG_REL_ BLTN_CAM SG_ 172 BLTN_CAM_SD_Card_UnMt_Mt_Req 0;
BA_REL_ "GenSigTimeoutTime" BU_SG_REL_ ATS SG_ 1266 HU_LanguageInfo 5000;
BA_REL_ "GenSigTimeoutTime" BU_SG_REL_ BLTN_CAM SG_ 1266 HU_LanguageInfo 5000;
BA_REL_ "GenSigTimeoutTime" BU_SG_REL_ APSU SG_ 1267 RSELockOnOff 5000;
BA_REL_ "GenSigTimeoutTime" BU_SG_REL_ ATS SG_ 1267 RSELockOnOff 5000;
BA_REL_ "GenSigTimeoutTime" BU_SG_REL_ ATS SG_ 191 RL_SHVU_DTCdisplay 1500;
BA_REL_ "GenSigTimeoutTime" BU_SG_REL_ ATS SG_ 191 RL_SHVU_DiagMode 1500;
BA_REL_ "GenSigTimeoutTime" BU_SG_REL_ ATS SG_ 1264 HU_TimeSetting 5000;
BA_REL_ "GenSigTimeoutTime" BU_SG_REL_ BLTN_CAM SG_ 1264 HU_TimeSetting 5000;
BA_REL_ "GenSigTimeoutTime" BU_SG_REL_ ATS SG_ 1264 HU_DisplayMinute 5000;
BA_REL_ "GenSigTimeoutTime" BU_SG_REL_ BLTN_CAM SG_ 1264 HU_DisplayMinute 5000;
BA_REL_ "GenSigTimeoutTime" BU_SG_REL_ ATS SG_ 1264 HU_Status 5000;
BA_REL_ "GenSigTimeoutTime" BU_SG_REL_ BLTN_CAM SG_ 1264 HU_Status 5000;
BA_REL_ "GenSigTimeoutTime" BU_SG_REL_ ATS SG_ 1264 HU_DisplaySecond 5000;
BA_REL_ "GenSigTimeoutTime" BU_SG_REL_ BLTN_CAM SG_ 1264 HU_DisplaySecond 5000;
BA_REL_ "GenSigTimeoutTime" BU_SG_REL_ ATS SG_ 1264 HU_DisplayMonth 5000;
BA_REL_ "GenSigTimeoutTime" BU_SG_REL_ BLTN_CAM SG_ 1264 HU_DisplayMonth 5000;
BA_REL_ "GenSigTimeoutTime" BU_SG_REL_ ATS SG_ 1264 HU_DisplayYear1 5000;
BA_REL_ "GenSigTimeoutTime" BU_SG_REL_ BLTN_CAM SG_ 1264 HU_DisplayYear1 5000;
BA_REL_ "GenSigTimeoutTime" BU_SG_REL_ ATS SG_ 1264 HU_DisplayYear2 5000;
BA_REL_ "GenSigTimeoutTime" BU_SG_REL_ BLTN_CAM SG_ 1264 HU_DisplayYear2 5000;
BA_REL_ "GenSigTimeoutTime" BU_SG_REL_ ATS SG_ 1264 HU_DisplayDay 5000;
BA_REL_ "GenSigTimeoutTime" BU_SG_REL_ BLTN_CAM SG_ 1264 HU_DisplayDay 5000;
BA_REL_ "GenSigTimeoutTime" BU_SG_REL_ ATS SG_ 1264 HU_AM_PM_INFO 5000;
BA_REL_ "GenSigTimeoutTime" BU_SG_REL_ BLTN_CAM SG_ 1264 HU_AM_PM_INFO 5000;
BA_REL_ "GenSigTimeoutTime" BU_SG_REL_ ATS SG_ 1264 HU_TimeFormat 5000;
BA_REL_ "GenSigTimeoutTime" BU_SG_REL_ BLTN_CAM SG_ 1264 HU_TimeFormat 5000;
BA_REL_ "GenSigTimeoutTime" BU_SG_REL_ ATS SG_ 1264 HU_ComRefresh 5000;
BA_REL_ "GenSigTimeoutTime" BU_SG_REL_ BLTN_CAM SG_ 1264 HU_ComRefresh 5000;
BA_REL_ "GenSigTimeoutTime" BU_SG_REL_ ATS SG_ 1264 HU_ClockInfo 5000;
BA_REL_ "GenSigTimeoutTime" BU_SG_REL_ BLTN_CAM SG_ 1264 HU_ClockInfo 5000;
BA_REL_ "GenSigTimeoutTime" BU_SG_REL_ ATS SG_ 1264 HU_DisplayHour 5000;
BA_REL_ "GenSigTimeoutTime" BU_SG_REL_ BLTN_CAM SG_ 1264 HU_DisplayHour 5000;
BA_REL_ "GenSigTimeoutTime" BU_SG_REL_ ATS SG_ 1265 HU_Background 5000;
BA_REL_ "GenSigTimeoutTime" BU_SG_REL_ BLTN_CAM SG_ 1265 HU_Background 5000;
BA_REL_ "GenSigTimeoutTime" BU_SG_REL_ DPSU SG_ 1265 ccIC_HUD_PbackSta 5000;
BA_REL_ "GenSigTimeoutTime" BU_SG_REL_ ATS SG_ 1265 HU_BackgroundFadeInOut 5000;
BA_REL_ "GenSigTimeoutTime" BU_SG_REL_ BLTN_CAM SG_ 1265 HU_BackgroundFadeInOut 5000;
BA_REL_ "GenSigTimeoutTime" BU_SG_REL_ BLTN_CAM SG_ 1278 HU_Type 5000;
BA_REL_ "GenSigTimeoutTime" BU_SG_REL_ BLTN_CAM SG_ 1278 HU_DistributeInfo 5000;
BA_REL_ "GenSigTimeoutTime" BU_SG_REL_ RCM SG_ 1278 HU_OptionInfo 5000;
BA_REL_ "GenSigTimeoutTime" BU_SG_REL_ BLTN_CAM SG_ 1278 HU_OptionInfo 5000;
BA_REL_ "GenSigTimeoutTime" BU_SG_REL_ WPC2 SG_ 1278 HU_OptionInfo 5000;
VAL_ 1218 C_AVN_PTGHeightNValueSet 0 "Default" 1 "Level 1" 2 "Level 2" 3 "Level 3" 4 "Level 4" 5 "Reserved" 6 "User Setting" 7 "Invalid" ;
VAL_ 1218 CF_AVN_SCCMLReset 0 "Default" 1 "Reset" 2 "Reserved" 3 "Invalid" ;
VAL_ 1218 C_TgltAwayCloseNValue 0 "Default" 1 "Off" 2 "On" 3 "Invalid" ;
VAL_ 1218 C_HAnBNValueSet 0 "Default" 1 "Arm Disarm Buzzer Off" 2 "Arm Disarm Buzzer On" 3 "Invalid" ;
VAL_ 1218 CF_AVN_RrSeatRemindNValueSet 0 "Default" 1 "Off  (Disable)" 2 "On (Enable)" 3 "Invalid" ;
VAL_ 1218 CF_AVN_DSWNValueSet 0 "Default" 1 "Off" 2 "On" 3 "Invalid" ;
VAL_ 1218 CF_AVN_RRPSU_RLNValueSet 0 "Default" 1 "Off (Disable)" 2 "On (Enable)" 3 "Reserved" 4 "Reserved" 5 "Reserved" 6 "Reserved" 7 "Invalid" ;
VAL_ 1218 CF_AVN_APSUNValueSet 0 "Default" 1 "Off (Disable)" 2 "50mm On (Enable)" 3 "75mm On (Enable)" 4 "Reserved" 5 "Reserved" 6 "Reserved" 7 "Invalid" ;
VAL_ 1218 CF_AVN_NCC_CameraNValueSet 0 "Default" 1 "Function Off" 2 "Manual Resume (Function On)" 3 "Automatic Resume (Function On)" 4 "Reserved" 5 "Reserved" 6 "Reserved" 7 "Invalid" ;
VAL_ 1218 CF_AVN_RRPSU_RRNValueSet 0 "Default" 1 "Off (Disable)" 2 "On (Enable)" 3 "Reserved" 4 "Reserved" 5 "Reserved" 6 "Reserved" 7 "Invalid" ;
VAL_ 1218 CF_AVN_HtBlcAstNValueSet 0 "Default" 1 "Normal" 2 "Back 1" 3 "Back 2" 4 "Back 3" 5 "Cush 1" 6 "Cush 2" 7 "Cush 3" 8 "Reserved" 9 "Reserved" 10 "Reserved" 11 "Reserved" 12 "Reserved" 13 "Reserved" 14 "Reserved" 15 "Invalid" ;
VAL_ 1218 CF_AVN_HtBlcDrvNValueSet 0 "Default" 1 "Normal" 2 "Back 1" 3 "Back 2" 4 "Back 3" 5 "Cush 1" 6 "Cush 2" 7 "Cush 3" 8 "Reserved" 9 "Reserved" 10 "Reserved" 11 "Reserved" 12 "Reserved" 13 "Reserved" 14 "Reserved" 15 "Invalid" ;
VAL_ 1218 CF_AVN_SCCModeNValueSet 0 "Not applied" 1 "Drive mode" 2 "SCC-ML" 3 "Invalid" ;
VAL_ 1218 CF_AVN_SCCMLChar1Set 0 "None" 1 "Level 1(Weak)" 2 "Level 2" 3 "Level 3" 4 "Level 4" 5 "Level 5(Strong)" 6 "Reserved" 7 "Invalid" ;
VAL_ 1218 CF_AVN_UIPNValueSet 0 "Default" 1 "Off (Disable)" 2 "On (Enable)" 3 "Invalid" ;
VAL_ 1218 CF_AVN_SCCMLChar2Set 0 "None" 1 "Level 1(Short)" 2 "Level 2" 3 "Level 3" 4 "Level 4" 5 "Reserved" 6 "Reserved" 7 "Invalid" ;
VAL_ 1218 CF_AVN_SCCMLChar3Set 0 "None" 1 "Level 1(Slow)" 2 "Level 2" 3 "Level 3" 4 "Level 4" 5 "Level 5(Fast)" 6 "Reserved" 7 "Invalid" ;
VAL_ 1218 CF_AVN_HDALCFuncNValueSet 0 "Default" 1 "Off" 2 "On" 3 "Invalid" ;
VAL_ 2323816450 HU_CDMOpenCmd_Copy_1 0 "Default" 1 "CDM Open" 2 "CDM Close" 3 "Invalid" ;
VAL_ 2323816450 HU_StrgWhlHeatingSet_CCS_Copy 0 "Default (off)" 1 "Step1 On" 2 "Step2 On" 3 "Reserved" 4 "Reserved" 5 "Reserved" 6 "Reserved" 7 "Invalid" ;
VAL_ 2323816450 FrunkCtrlReq 0 "No Action(Default)" 1 "Close" 2 "Open" 3 "invaild" ;
VAL_ 2323816450 C_EsyAcsProfileID_CCU 0 "Default" 1 "Gueset" 2 "Profile 1" 3 "Profile 2" 4 "Reserved" 5 "Reserved" 6 "Reserved" 7 "Reserved" 8 "Reserved" 9 "Reserved" 10 "Reserved" 11 "Reserved" 12 "Reserved" 13 "Reserved" 14 "Reserved" 15 "Invalid" ;
VAL_ 2323816449 C_CtrlDrLockRlyCCS_Copy_2 0 "Off (default)" 1 "On (remote Lock Command)" 2 "Reserved" 3 "Invalid" ;
VAL_ 2323816449 C_TeleHeatingCmdIBOX_Copy_2 0 "Off (default)" 1 "On(Remote Heating On)" 2 "Reserved" 3 "Invalid" ;
VAL_ 2323816449 C_TeleStrgWhlHeatingCmdIBOX_Copy 0 "Off (default)" 1 "On(Remote Heating On)" 2 "Reserved" 3 "Invalid" ;
VAL_ 2323816449 C_TeleDefoggerHeatingCmdIBOX_Cop 0 "Off (default)" 1 "On(Remote Heating On)" 2 "Reserved" 3 "Invalid" ;
VAL_ 2323816449 C_TeleDrvSeatOpCmdIBOX_Copy_2 0 "Init" 1 "Unused" 2 "Seat Heat&Vent OFF" 3 "Seat_Vent_Low" 4 "Seat_Vent_Mid" 5 "Seat_Vent_High" 6 "Seat_Heat_Low" 7 "Seat_Heat_Mid" 8 "Seat_Heat_High" 9 "Unused" 10 "Unused" 11 "Unused" 12 "Unused" 13 "Unused" 14 "Unused" 15 "Invalid" ;
VAL_ 2323816449 C_CtrlDrUnlockRlyCCS_Copy_2 0 "0ff" 1 "On (Remote Unlock Command)" 2 "Reserved" 3 "Invalid" ;
VAL_ 2323816449 C_TeleAstSeatOpCmdIBOX_Copy_2 0 "Init" 1 "Unused" 2 "Seat Heat&Vent OFF" 3 "Seat_Vent_Low" 4 "Seat_Vent_Mid" 5 "Seat_Vent_High" 6 "Seat_Heat_Low" 7 "Seat_Heat_Mid" 8 "Seat_Heat_High" 9 "Unused" 10 "Unused" 11 "Unused" 12 "Unused" 13 "Unused" 14 "Unused" 15 "Invalid" ;
VAL_ 2323816449 C_TeleRRSeatOpCmdIBOX_Copy_2 0 "Init" 1 "Unused" 2 "Seat Heat&Vent OFF" 3 "Seat_Vent_Low" 4 "Seat_Vent_Mid" 5 "Seat_Vent_High" 6 "Seat_Heat_Low" 7 "Seat_Heat_Mid" 8 "Seat_Heat_High" 9 "Unused" 10 "Unused" 11 "Unused" 12 "Unused" 13 "Unused" 14 "Unused" 15 "Invalid" ;
VAL_ 2323816449 C_TeleRLSeatOpCmdIBOX_Copy_1 0 "Init" 1 "Unused" 2 "Seat Heat&Vent OFF" 3 "Seat_Vent_Low" 4 "Seat_Vent_Mid" 5 "Seat_Vent_High" 6 "Seat_Heat_Low" 7 "Seat_Heat_Mid" 8 "Seat_Heat_High" 9 "Unused" 10 "Unused" 11 "Unused" 12 "Unused" 13 "Unused" 14 "Unused" 15 "Invalid" ;
VAL_ 2323816449 C_DrvWindowCmdAVN_Copy_2 0 "No action" 1 "Manual Down" 2 "Manual Up" 3 "25% Open" 4 "50% Open" 5 "Auto Down" 6 "Auto Up" 7 "15% Open" 8 "Unused" 9 "Unused" 10 "Unused" 11 "Unused" 12 "Unused" 13 "Unused" 14 "Unused" 15 "Invalid" ;
VAL_ 2323816449 C_HazardFromCCS_Copy_2 0 "Off" 1 "On (Remote Hazard On)" 2 "Reserved" 3 "Invalid" ;
VAL_ 2323816449 C_AstWindowCmdAVN_Copy_2 0 "No action" 1 "Manual Down" 2 "Manual Up" 3 "25% Open" 4 "50%Open" 5 "Auto Down" 6 "Auto Up" 7 "15% Open" 8 "Unused" 9 "Unused" 10 "Unused" 11 "Unused" 12 "Unused" 13 "Unused" 14 "Unused" 15 "Invalid" ;
VAL_ 2323816449 C_RRWindowCmdAVN_Copy_2 0 "No action" 1 "Manual Down" 2 "Manual Up" 3 "25% Open" 4 "50% Open" 5 "Auto Down" 6 "Auto Up" 7 "15% Open" 8 "Unused" 9 "Unused" 10 "Unused" 11 "Unused" 12 "Unused" 13 "Unused" 14 "Unused" 15 "Invalid" ;
VAL_ 2323816449 C_RLWindowCmdAVN_Copy_2 0 "No action" 1 "Manual Down" 2 "Manual Up" 3 "25% Open" 4 "50% Open" 5 "Auto Down" 6 "Auto UP" 7 "15% Open" 8 "Unused" 9 "Unused" 10 "Unused" 11 "Unused" 12 "Unused" 13 "Unused" 14 "Unused" 15 "Invalid" ;
VAL_ 2323816449 TailCtrlReq_Copy 0 "No Action(Default)" 1 "Tail Off" 2 "Tail On" 3 "Error Indicator" ;
VAL_ 2323816449 HazardCtrlReq_Copy 0 "No Action(Default)" 1 "Hazard Off" 2 "Hazard On" 3 "Error Indicator" ;
VAL_ 2323816449 HU_DATC_AirCleaningSet_Copy_1 0 "Air Cleaning System Off" 1 "Air Cleaning System On" 2 "Air Cleaning System Not Support" 3 "Invalid" ;
VAL_ 2323816449 C_PanicFromCCS_Copy_2 0 "Off" 1 "On (Remote Horn and Hazard On)" 2 "Reserved" 3 "Invalid" ;
VAL_ 2323816449 C_TeleFrontHeatingCmdIBOX_Copy_1 0 "Off (Default)" 1 "On (Remote Heating On)" 2 "Reserved" 3 "Invalid" ;
VAL_ 2323816449 RAC_AirCleaningCtrlReq_Copy_1 0 "Deactive air cleaning control" 1 "Active air cleaning control" 2 "Not used" 3 "invalid" ;
VAL_ 2323816449 C_PreCrankReq_Copy 0 "Default" 1 "Req On" 2 "Not Support" 3 "Invalid" ;
VAL_ 1227 DrvIMS_MemoryP1Req 0 "None" 1 "P1" 2 "Not Used" 3 "Error Indicator" ;
VAL_ 1227 DrvIMS_PlyBckP2Req 0 "None" 1 "P2" 2 "Not Used" 3 "Error Indicator" ;
VAL_ 1227 DrvIMS_PlyBckP3Req 0 "None" 1 "P3" 2 "Not Used" 3 "Error Indicator" ;
VAL_ 1227 DrvIMS_PlyBckStpReq 0 "Off" 1 "Stop" 2 "Not Used" 3 "Error Indicator" ;
VAL_ 1227 SmrtIMS_PlyBckReq 0 "None" 1 "0x1~0x97E:Smart IMS DB Number(1~2430)" 2430 "0x1~0x97E:Smart IMS DB Number(1~2430)" 2431 "0x97F~0xFFE:RESERVED" 4094 "0x97F~0xFFE:RESERVED" 4095 "Invalid" ;
VAL_ 1227 DrvIMS_MemoryP2Req 0 "None" 1 "P2" 2 "Not Used" 3 "Error Indicator" ;
VAL_ 1227 PSM_IMSReq 0 "None" 1 "Replay1" 2 "Replay2" 3 "Replay3" 4 "Memory1" 5 "Memory2" 6 "Memory3" 7 "Stop" ;
VAL_ 1227 SmrtIMS_ImgDBVal 0 "none" 1 "Smart IMS Image DB 1~30" 2 "Smart IMS Image DB 1~30" 3 "Smart IMS Image DB 1~30" 4 "Smart IMS Image DB 1~30" 5 "Smart IMS Image DB 1~30" 6 "Smart IMS Image DB 1~30" 7 "Smart IMS Image DB 1~30" 8 "Smart IMS Image DB 1~30" 9 "Smart IMS Image DB 1~30" 10 "Smart IMS Image DB 1~30" 11 "Smart IMS Image DB 1~30" 12 "Smart IMS Image DB 1~30" 13 "Smart IMS Image DB 1~30" 14 "Smart IMS Image DB 1~30" 15 "Smart IMS Image DB 1~30" 16 "Smart IMS Image DB 1~30" 17 "Smart IMS Image DB 1~30" 18 "Smart IMS Image DB 1~30" 19 "Smart IMS Image DB 1~30" 20 "Smart IMS Image DB 1~30" 21 "Smart IMS Image DB 1~30" 22 "Smart IMS Image DB 1~30" 23 "Smart IMS Image DB 1~30" 24 "Smart IMS Image DB 1~30" 25 "Smart IMS Image DB 1~30" 26 "Smart IMS Image DB 1~30" 27 "Smart IMS Image DB 1~30" 28 "Smart IMS Image DB 1~30" 29 "Smart IMS Image DB 1~30" 30 "Smart IMS Image DB 1~30" 31 "Invalid" ;
VAL_ 1227 SmrtIMS_PlyBckStpReq 0 "OFF" 1 "On" 2 "Not Used" 3 "Error Indicator" ;
VAL_ 1227 DrvIMS_MemoryP3Req 0 "None" 1 "P3" 2 "Not Used" 3 "Error Indicator" ;
VAL_ 1227 SmrtIMS_EnterSwSta 0 "off" 1 "on" 2 "reserved" 3 "invalid" ;
VAL_ 1227 DrvIMS_BzrReq 0 "Off" 1 "On" 2 "Not Used" 3 "Error Indicator" ;
VAL_ 1227 DrvIMS_ErrConWmgDis 0 "Off" 1 "On" 2 "Not Used" 3 "Error Indicator" ;
VAL_ 1227 PSM_DrvRlxReturn_Req 0 "Default" 1 "One touch relax" 2 "One touch return" 3 "Stop" 4 "Reserved" 5 "Reserved" 6 "Reserved" 7 "invalid" ;
VAL_ 1227 Drv_AutoRlxWrngDis 0 "Off" 1 "Auto Relax Enable" 2 "Mode-Fail (Vehicle Speed Warning)" 3 "Mode-Fail (Not P Warning)" 4 "Mode-Fail (2nd Seat Belted)" 5 "Mode-Fail (Not Initialized)" 6 "Mode-Fail (2nd Seat Position Warning)" 7 "Invalid" ;
VAL_ 1227 DrvIMS_MemorySetEnaSta 0 "Disable" 1 "Enable" 2 "Not Used" 3 "Error Indicator" ;
VAL_ 1227 DrvIMS_PlyBckP1Req 0 "None" 1 "P1" 2 "Not Used" 3 "Error Indicator" ;
VAL_ 1237 Audio_VolEncoderSta 0 "Reserved" 1 "0x01~0x7F:Clockwise(Up)" 127 "0x01~0x7F:Clockwise(Up)" 128 "0x80~0xFE:Counterclockwise (Down)" 254 "0x80~0xFE:Counterclockwise (Down)" 255 "Invalid" ;
VAL_ 1237 Cluster_ScrlEncoderSta 0 "Reserved" 1 "0x01~0x7F:Clockwise(Up)" 127 "0x01~0x7F:Clockwise(Up)" 128 "0x80~0xFE:Counterclockwise (Down)" 254 "0x80~0xFE:Counterclockwise (Down)" 255 "Invalid" ;
VAL_ 1239 HU_MKBD_BtnLEDCtr 0 "Default" 1 "OFF" 2 "ON" 3 "Invalid" ;
VAL_ 1239 HU_ADMSettingState 0 "ADM On (Setting Vaule in HU)" 1 "ADM Off" 2 "Reserved" 3 "Reserved" 4 "Reserved" 5 "Reserved" 6 "Reserved" 7 "Invalid" ;
VAL_ 1239 HU_PwrState 0 "Default" 1 "Normal On" 2 "ADM" 3 "Wait for door open" 4 "Logic Off" 5 "Remote Engine On" 6 "Reserved" 7 "Reserved" 8 "Reserved" 9 "Reserved" 10 "Reserved" 11 "Reserved" 12 "Reserved" 13 "Reserved" 14 "Reserved" 15 "Invalid" ;
VAL_ 1239 HU_MKBD_ModeSwitch 0 "Key off" 1 "AVNT mode on" 2 "DATC mode on" 3 "Invalid" ;
VAL_ 1239 HU_LCDState 0 "Default" 1 "On" 2 "Off" 3 "RESERVED" 4 "RESERVED" 5 "RESERVED" 6 "RESERVED" 7 "Invalid" ;
VAL_ 1239 HU_VehiclePwr 0 "Key out or Audio OFF" 1 "Not used" 2 "ACC or Audio ON" 3 "KBD Wake-up" 4 "Waiting for Good-Bye (Key out or Audio OFF)" 5 "Not used" 6 "Not used" 7 "Not used" 8 "Not used" 9 "Not used" 10 "Not used" 11 "Not used" 12 "Not used" 13 "Not used" 14 "Not used" 15 "Invalid" ;
VAL_ 1239 HU_BtnShowReq 0 "default" 1 "on" 2 "off" 3 "reserved" 4 "reserved" 5 "reserved" 6 "reserved" 7 "invalid" ;
VAL_ 157 ATS_DATC_FrDrTempSetC 0 "Blank" 1 "LO" 2 "PHY=HEX*0.5 + 14" 3 "PHY=HEX*0.5 + 14" 4 "PHY=HEX*0.5 + 14" 5 "PHY=HEX*0.5 + 14" 6 "PHY=HEX*0.5 + 14" 7 "PHY=HEX*0.5 + 14" 8 "PHY=HEX*0.5 + 14" 9 "PHY=HEX*0.5 + 14" 10 "PHY=HEX*0.5 + 14" 11 "PHY=HEX*0.5 + 14" 12 "PHY=HEX*0.5 + 14" 13 "PHY=HEX*0.5 + 14" 14 "PHY=HEX*0.5 + 14" 15 "PHY=HEX*0.5 + 14" 16 "PHY=HEX*0.5 + 14" 17 "PHY=HEX*0.5 + 14" 18 "PHY=HEX*0.5 + 14" 19 "PHY=HEX*0.5 + 14" 20 "PHY=HEX*0.5 + 14" 21 "PHY=HEX*0.5 + 14" 22 "PHY=HEX*0.5 + 14" 23 "PHY=HEX*0.5 + 14" 24 "PHY=HEX*0.5 + 14" 25 "PHY=HEX*0.5 + 14" 26 "PHY=HEX*0.5 + 14" 27 "PHY=HEX*0.5 + 14" 28 "PHY=HEX*0.5 + 14" 29 "PHY=HEX*0.5 + 14" 30 "PHY=HEX*0.5 + 14" 31 "PHY=HEX*0.5 + 14" 32 "PHY=HEX*0.5 + 14" 33 "PHY=HEX*0.5 + 14" 34 "PHY=HEX*0.5 + 14" 35 "PHY=HEX*0.5 + 14" 36 "PHY=HEX*0.5 + 14" 37 "0x25~0xFD:Reserved" 253 "0x25~0xFD:Reserved" 254 "HI" 255 "Invalid" ;
VAL_ 157 ATS_DATC_RrDrBlowerUpDn 0 "Reserved" 1 "Blower Up" 2 "Blower Down" 3 "Invalid" ;
VAL_ 157 ATS_DATC_FrSyncSet 0 "Reserved" 1 "NOT SYNC" 2 "SYNC" 3 "Invalid" ;
VAL_ 157 ATS_DATC_RrDrTempSetC 0 "Blank" 1 "LO" 2 "PHY=HEX*0.5 + 14" 3 "PHY=HEX*0.5 + 14" 4 "PHY=HEX*0.5 + 14" 5 "PHY=HEX*0.5 + 14" 6 "PHY=HEX*0.5 + 14" 7 "PHY=HEX*0.5 + 14" 8 "PHY=HEX*0.5 + 14" 9 "PHY=HEX*0.5 + 14" 10 "PHY=HEX*0.5 + 14" 11 "PHY=HEX*0.5 + 14" 12 "PHY=HEX*0.5 + 14" 13 "PHY=HEX*0.5 + 14" 14 "PHY=HEX*0.5 + 14" 15 "PHY=HEX*0.5 + 14" 16 "PHY=HEX*0.5 + 14" 17 "PHY=HEX*0.5 + 14" 18 "PHY=HEX*0.5 + 14" 19 "PHY=HEX*0.5 + 14" 20 "PHY=HEX*0.5 + 14" 21 "PHY=HEX*0.5 + 14" 22 "PHY=HEX*0.5 + 14" 23 "PHY=HEX*0.5 + 14" 24 "PHY=HEX*0.5 + 14" 25 "PHY=HEX*0.5 + 14" 26 "PHY=HEX*0.5 + 14" 27 "PHY=HEX*0.5 + 14" 28 "PHY=HEX*0.5 + 14" 29 "PHY=HEX*0.5 + 14" 30 "PHY=HEX*0.5 + 14" 31 "PHY=HEX*0.5 + 14" 32 "PHY=HEX*0.5 + 14" 33 "PHY=HEX*0.5 + 14" 34 "PHY=HEX*0.5 + 14" 35 "PHY=HEX*0.5 + 14" 36 "PHY=HEX*0.5 + 14" 37 "0x25~0xFC:Reserved" 252 "0x25~0xFC:Reserved" 254 "HI" 255 "Invalid" ;
VAL_ 157 ATS_DATC_RrDrTempSetF 0 "Blank" 1 "LO" 2 "PHY=HEX*1+56" 3 "PHY=HEX*1+56" 4 "PHY=HEX*1+56" 5 "PHY=HEX*1+56" 6 "PHY=HEX*1+56" 7 "PHY=HEX*1+56" 8 "PHY=HEX*1+56" 9 "PHY=HEX*1+56" 10 "PHY=HEX*1+56" 11 "PHY=HEX*1+56" 12 "PHY=HEX*1+56" 13 "PHY=HEX*1+56" 14 "PHY=HEX*1+56" 15 "PHY=HEX*1+56" 16 "PHY=HEX*1+56" 17 "PHY=HEX*1+56" 18 "PHY=HEX*1+56" 19 "PHY=HEX*1+56" 20 "PHY=HEX*1+56" 21 "PHY=HEX*1+56" 22 "PHY=HEX*1+56" 23 "PHY=HEX*1+56" 24 "PHY=HEX*1+56" 25 "PHY=HEX*1+56" 26 "PHY=HEX*1+56" 27 "PHY=HEX*1+56" 28 "PHY=HEX*1+56" 29 "PHY=HEX*1+56" 30 "PHY=HEX*1+56" 31 "PHY=HEX*1+56" 32 "PHY=HEX*1+56" 33 "PHY=HEX*1+56" 34 "PHY=HEX*1+56" 35 "PHY=HEX*1+56" 36 "PHY=HEX*1+56" 37 "0x25~0xFC:Reserved" 252 "0x25~0xFC:Reserved" 254 "HI" 255 "Invalid" ;
VAL_ 157 ATS_DATC_FrPsTempSetC 0 "Blank" 1 "LO" 2 "PHY=HEX*0.5 + 14" 3 "PHY=HEX*0.5 + 14" 4 "PHY=HEX*0.5 + 14" 5 "PHY=HEX*0.5 + 14" 6 "PHY=HEX*0.5 + 14" 7 "PHY=HEX*0.5 + 14" 8 "PHY=HEX*0.5 + 14" 9 "PHY=HEX*0.5 + 14" 10 "PHY=HEX*0.5 + 14" 11 "PHY=HEX*0.5 + 14" 12 "PHY=HEX*0.5 + 14" 13 "PHY=HEX*0.5 + 14" 14 "PHY=HEX*0.5 + 14" 15 "PHY=HEX*0.5 + 14" 16 "PHY=HEX*0.5 + 14" 17 "PHY=HEX*0.5 + 14" 18 "PHY=HEX*0.5 + 14" 19 "PHY=HEX*0.5 + 14" 20 "PHY=HEX*0.5 + 14" 21 "PHY=HEX*0.5 + 14" 22 "PHY=HEX*0.5 + 14" 23 "PHY=HEX*0.5 + 14" 24 "PHY=HEX*0.5 + 14" 25 "PHY=HEX*0.5 + 14" 26 "PHY=HEX*0.5 + 14" 27 "PHY=HEX*0.5 + 14" 28 "PHY=HEX*0.5 + 14" 29 "PHY=HEX*0.5 + 14" 30 "PHY=HEX*0.5 + 14" 31 "PHY=HEX*0.5 + 14" 32 "PHY=HEX*0.5 + 14" 33 "PHY=HEX*0.5 + 14" 34 "PHY=HEX*0.5 + 14" 35 "PHY=HEX*0.5 + 14" 36 "PHY=HEX*0.5 + 14" 37 "0x25~0xFD:Reserved" 253 "0x25~0xFD:Reserved" 254 "HI" 255 "Invalid" ;
VAL_ 157 ATS_DATC_FrPsTempSetF 0 "Blank" 1 "LO" 2 "PHY=HEX*1+56" 3 "PHY=HEX*1+56" 4 "PHY=HEX*1+56" 5 "PHY=HEX*1+56" 6 "PHY=HEX*1+56" 7 "PHY=HEX*1+56" 8 "PHY=HEX*1+56" 9 "PHY=HEX*1+56" 10 "PHY=HEX*1+56" 11 "PHY=HEX*1+56" 12 "PHY=HEX*1+56" 13 "PHY=HEX*1+56" 14 "PHY=HEX*1+56" 15 "PHY=HEX*1+56" 16 "PHY=HEX*1+56" 17 "PHY=HEX*1+56" 18 "PHY=HEX*1+56" 19 "PHY=HEX*1+56" 20 "PHY=HEX*1+56" 21 "PHY=HEX*1+56" 22 "PHY=HEX*1+56" 23 "PHY=HEX*1+56" 24 "PHY=HEX*1+56" 25 "PHY=HEX*1+56" 26 "PHY=HEX*1+56" 27 "PHY=HEX*1+56" 28 "PHY=HEX*1+56" 29 "PHY=HEX*1+56" 30 "PHY=HEX*1+56" 31 "PHY=HEX*1+56" 32 "PHY=HEX*1+56" 33 "PHY=HEX*1+56" 34 "PHY=HEX*1+56" 35 "PHY=HEX*1+56" 36 "PHY=HEX*1+56" 37 "0x25~0xFC:Reserved" 252 "0x25~0xFC:Reserved" 254 "HI" 255 "Invalid" ;
VAL_ 157 ATS_DATC_FrDrTempSetF 0 "Blank" 1 "LO" 2 "PHY=HEX*1 + 56" 3 "PHY=HEX*1 + 56" 4 "PHY=HEX*1 + 56" 5 "PHY=HEX*1 + 56" 6 "PHY=HEX*1 + 56" 7 "PHY=HEX*1 + 56" 8 "PHY=HEX*1 + 56" 9 "PHY=HEX*1 + 56" 10 "PHY=HEX*1 + 56" 11 "PHY=HEX*1 + 56" 12 "PHY=HEX*1 + 56" 13 "PHY=HEX*1 + 56" 14 "PHY=HEX*1 + 56" 15 "PHY=HEX*1 + 56" 16 "PHY=HEX*1 + 56" 17 "PHY=HEX*1 + 56" 18 "PHY=HEX*1 + 56" 19 "PHY=HEX*1 + 56" 20 "PHY=HEX*1 + 56" 21 "PHY=HEX*1 + 56" 22 "PHY=HEX*1 + 56" 23 "PHY=HEX*1 + 56" 24 "PHY=HEX*1 + 56" 25 "PHY=HEX*1 + 56" 26 "PHY=HEX*1 + 56" 27 "PHY=HEX*1 + 56" 28 "PHY=HEX*1 + 56" 29 "PHY=HEX*1 + 56" 30 "PHY=HEX*1 + 56" 31 "PHY=HEX*1 + 56" 32 "PHY=HEX*1 + 56" 33 "PHY=HEX*1 + 56" 34 "PHY=HEX*1 + 56" 35 "PHY=HEX*1 + 56" 36 "PHY=HEX*1 + 56" 37 "0x25~0xFD:Reserved" 253 "0x25~0xFD:Reserved" 254 "HI" 255 "Invalid" ;
VAL_ 158 ATS_DATC_FrDrBlowerSet 0 "DATC Off" 1 "0 level (Do not use)" 2 "1 level" 3 "2 level" 4 "3level" 5 "4 level" 6 "5 level" 7 "6 level" 8 "7 level" 9 "8 level" 15 "Invalid" ;
VAL_ 158 ATS_DATC_RrDrTempUpDn 0 "Reserved" 1 "Temp Up" 2 "Temp Down" 3 "Invalid" ;
VAL_ 158 ATS_DATC_RrDrBlowerSet 0 "Off" 1 "0 level" 2 "1 level" 3 "2 level" 4 "3 level" 5 "4 level" 6 "5 level" 7 "6 level" 8 "7 level" 9 "8 level" 14 "reserved" 15 "Invalid" ;
VAL_ 158 ATS_DATC_RrDrModeSet 0 "Off" 1 "VENT" 2 "BL" 3 "FLOOR" 12 "reserved" 13 "reserved" 14 "reserved" 15 "Invalid" ;
VAL_ 158 ATS_DATC_FrDrModeSet 0 "Reserved" 1 "VENT" 2 "BL" 3 "FLOOR" 4 "MIX" 5 "reserved" 6 "reserved" 7 "7 Mode DEF VENT" 8 "reserved" 9 "MODE DEF VENT FLOOR" 10 "7 Mode DEF" 11 "Reserved" 12 "Reserved" 13 "Reserved" 14 "Reserved" 15 "Invalid" ;
VAL_ 158 ATS_DATC_RrOnOffSet 0 "Function Off" 1 "Function On" 2 "reserved" 3 "Invalid" ;
VAL_ 158 ATS_DATC_IntakeSet 0 "REC Off (Fresh On)" 1 "REC ON (Fresh Off)" 2 "reserved" 3 "Invalid" ;
VAL_ 158 ATS_DATC_OffReq 0 "Reserved" 1 "Request" 2 "reserved" 3 "Invalid" ;
VAL_ 158 ATS_DATC_FrDrAutoSet 0 "reserved" 1 "AUTO ON" 2 "reserved" 3 "Invalid" ;
VAL_ 158 ATS_DATC_FrPsTempUpDn 0 "Reserved" 1 "Temp Up" 2 "Temp Down" 3 "Invalid" ;
VAL_ 158 ATS_DATC_FrDefog 0 "Defog Off" 1 "Defog On" 2 "reserved" 3 "Invalid" ;
VAL_ 158 ATS_DATC_RrSyncSet 0 "Reserved" 1 "NOT SYNC" 2 "Rear SYNC" 3 "Invalid" ;
VAL_ 158 ATS_DATC_AcSet 0 "AC Off" 1 "AC ON" 2 "reserved" 3 "Invalid" ;
VAL_ 158 ATS_DATC_AirCleaningSet 0 "Air Cleaning System Off" 1 "Air Cleaning System On" 2 "Air Cleaning System Not Support" 3 "Invalid" ;
VAL_ 158 ATS_DATC_FrDrBlowerUpDn 0 "Reserved" 1 "Up" 2 "Down" 3 "Invalid" ;
VAL_ 158 ATS_DATC_FrDrTempUpDn 0 "Reserved" 1 "Temp Up" 2 "Temp Down" 3 "Invalid" ;
VAL_ 158 ATS_DATC_RrDrAutoSet 0 "Auto Off" 1 "Auto On" 2 "Not Used" 3 "Invalid" ;
VAL_ 1247 Navi_ParkingLot 0 "Unknown" 1 "Parking Garage (Æó¼âÇü ÁÖÂ÷Àå)" 2 "Reserved" 3 "Invalid" ;
VAL_ 1247 Navi_AirConditionWarning 0 "Unknown" 1 "On(Close)" 2 "Off" 3 "Invalid" ;
VAL_ 1247 Navi_AirConditionType 0 "None" 1 "Defined Value" 2 "Defined Value" 3 "Defined Value" 4 "Defined Value" 5 "Defined Value" 6 "Defined Value" 7 "Defined Value" 8 "Defined Value" 9 "Defined Value" 10 "Defined Value" 11 "Defined Value" 12 "Defined Value" 13 "Defined Value" 14 "Defined Value" 15 "Defined Value" 16 "Defined Value" 17 "Defined Value" 18 "Defined Value" 19 "Defined Value" 20 "Defined Value" 21 "Defined Value" 22 "Defined Value" 23 "Defined Value" 24 "Defined Value" 25 "Defined Value" 26 "Defined Value" 27 "Defined Value" 28 "Defined Value" 29 "Defined Value" 30 "Defined Value" 31 "Defined Value" 32 "Defined Value" 33 "Defined Value" 34 "Defined Value" 35 "Defined Value" 36 "Defined Value" 37 "Defined Value" 38 "Defined Value" 39 "Defined Value" 40 "Defined Value" 41 "Defined Value" 42 "Defined Value" 43 "Defined Value" 44 "Defined Value" 45 "Defined Value" 46 "Defined Value" 47 "Defined Value" 48 "Defined Value" 49 "Defined Value" 50 "Defined Value" 51 "Defined Value" 52 "Defined Value" 53 "Defined Value" 54 "Defined Value" 55 "Defined Value" 56 "Defined Value" 57 "Defined Value" 58 "Defined Value" 59 "Defined Value" 60 "Defined Value" 61 "Defined Value" 62 "Defined Value" 63 "Invalid" ;
VAL_ 1240 HU_DistanceUnit 0 "Km" 1 "Mile" 2 "Reserved" 3 "Invalid" ;
VAL_ 1240 HU_ThemeType 0 "default" 1 "Aqua(Hyundai)" 16 "Copper" 17 "Copper Rust" 2 "Magenta(Kia)" 32 "ccIC Light" 33 "ccIC Dark" 3 "Eco White" 4 "Eco Black" 5 "Genesis(IKPE)" 6 "Magenta White" ;
VAL_ 1240 HU_MicActivity 0 "Deactivated" 1 "Activated" 2 "reserved" 3 "Invalid" ;
VAL_ 1240 HU_Scheduled_Setting 0 "Scheduled not set" 1 "Scheduled set" 2 "Reserved" 3 "Reserved" 4 "Reserved" 5 "Reserved" 6 "60% SoC Requested" 7 "70% SoC Requested" 8 "80% SoC Requested" 9 "90% SoC Requested" 10 "100% SoC Requested" 11 "Reserved" 12 "Reserved" 13 "Reserved" 14 "Reserved" 15 "Invalid" ;
VAL_ 1240 AVN_RSPA_ModeSelect 0 "None" 1 "CCP focus (1st menu on the left)" 2 "Touch or CCP confirm (1st menu on the left)" 3 "CCP focus (2nd menu on the left)" 4 "Touch or CCP confirm (2nd menu on the left)" 5 "CCP focus (1st menu on the right)" 6 "Touch or CCP confirm (1st menu on the right)" 7 "CCP focus (2nd menu on the right)" 8 "Touch or CCP confirm (2nd menu on the right)" 9 "Reserved" 10 "Reserved" 11 "Reserved" 12 "Reserved" 13 "Reserved" 14 "Reserved" 15 "Invalid" ;
VAL_ 1240 CF_HU_GPSFlt 0 "Normal" 1 "Fault operation" 2 "TimeOut" 3 "Invalid" ;
VAL_ 1240 AVN_RSPA_CancelInput 0 "Init" 1 "No Input" 2 "Cancel Input" 3 "Invalid" ;
VAL_ 1240 AVN_RSPA_Disp_Rdy 0 "Impossible to display" 1 "Possible to display" 2 "Reserved" 3 "Invalid" ;
VAL_ 1240 CF_AVN_ProfileIDRValue 0 "Default" 1 "Guest" 2 "Profile 1" 3 "Profile 2" 4 "reserved" 5 "reserved" 6 "reserved" 7 "reserved" 8 "reserved" 9 "reserved" 10 "reserved" 11 "reserved" 12 "reserved" 13 "reserved" 14 "reserved" 15 "Invalid" ;
VAL_ 1240 HazardFromHUSVM 0 "inactive" 1 "active" 2 "reserved" 3 "invalid" ;
VAL_ 1240 OMUOSMirCtrl 0 "Off" 1 "Fold" 2 "Unfold" 3 "invalid" ;
VAL_ 1240 OTAUIStatus 0 "Not Ready" 1 "Ready" 2 "Reserved" 3 "Invalid" ;
VAL_ 1240 C_TeleActiveStatus 0 "Active" 1 "Deactive" 2 "Reserved" 3 "Invalid" ;
VAL_ 1240 HU_AliveStatus 0 "Not Ready" 1 "On Mode" 2 "Head Unit Update Mode" 3 "Invalid" ;
VAL_ 1240 HU_RTCCheck 0 "Ready" 1 "Checking" 2 "Reserved" 3 "Invalid" ;
VAL_ 2424580353 DATC_Crc12Val 0 "0x0x0~0xFFFF:CRCValue" 65535 "0x0x0~0xFFFF:CRCValue" ;
VAL_ 2424580353 DATC_AlvCnt12Val 0 "0x0x0~0xFF:AlvCntValue" 255 "0x0x0~0xFF:AlvCntValue" ;
VAL_ 2424580353 DATC_StrWhlHtrSwReq 0 "Default" 1 "OFF" 2 "ON" 3 "Error Indicator" ;
VAL_ 2424580353 DATC_FRStHtrSwReq 0 "Default" 1 "OFF" 2 "ON" 3 "Error Indicator" ;
VAL_ 2424580353 DATC_FRStVentSwReq 0 "Default" 1 "OFF" 2 "ON" 3 "Error Indicator" ;
VAL_ 2424580353 DATC_RrDefSw 0 "Default" 1 "OFF" 2 "ON" 3 "Error Indicator" ;
VAL_ 2424580353 DATC_FLStOpReq 0 "Default" 1 "Integrated control OFF" 2 "OFF" 3 "Left Seat Ventilation 1st ON" 4 "Left Seat Ventilation 1st&2nd ON" 5 "Left Seat Ventilation 1st&2nd&3rd ON" 6 "Left Seat Warmer 1st ON" 7 "Left Seat Warmer 1st&2nd ON" 8 "Left Seat Warmer 1st&2nd&3rd ON" 9 "Not Used" 10 "Not Used" 11 "Not Used" 12 "Not Used" 13 "Not Used" 14 "Not Used" 15 "Error Indicator" ;
VAL_ 2424580353 DATC_FRStOpReq 0 "Default" 1 "Integrated control OFF" 2 "OFF" 3 "Right Seat Ventilation 1st ON" 4 "Right Seat Ventilation 1st&2nd ON" 5 "Right Seat Ventilation 1st&2nd&3rd ON" 6 "Right Seat Warmer 1st ON" 7 "Right Seat Warmer 1st&2nd ON" 8 "Right Seat Warmer 1st&2nd&3rd ON" 9 "Not Used" 10 "Not Used" 11 "Not Used" 12 "Not Used" 13 "Not Used" 14 "Not Used" 15 "Error Indicaotr" ;
VAL_ 2424580353 DATC_FLStHtrSwReq 0 "Default" 1 "OFF" 2 "ON" 3 "Error Indicator" ;
VAL_ 2424580353 DATC_FLStVentSwReq 0 "Default" 1 "OFF" 2 "ON" 3 "Error Indicator" ;
VAL_ 2424580353 DATC_FLStTmblrSwReq 0 "Default" 1 "Up" 2 "Down" 3 "Error Indicator" ;
VAL_ 2424580353 DATC_FRStTmblrSwReq 0 "Default" 1 "Up" 2 "Down" 3 "Error Indicator" ;
VAL_ 2424580353 DATC_RRStHtrSwReq 0 "Default" 1 "OFF" 2 "ON" 3 "Error Indicator" ;
VAL_ 2424580353 DATC_RRStVentSwReq 0 "Default" 1 "OFF" 2 "ON" 3 "Error Indicator" ;
VAL_ 2424580353 DATC_RLStHtrSwReq 0 "Default" 1 "OFF" 2 "ON" 3 "Error Indicator" ;
VAL_ 2424580353 DATC_RLStVentSwReq 0 "Default" 1 "OFF" 2 "ON" 3 "Error Indicator" ;
VAL_ 2424580353 DATC_FRWndShldHtSW 0 "Default" 1 "Off" 2 "On" 3 "Error Indicator" ;
VAL_ 2424580353 DATC_WhistlelNoise 0 "Default" 1 "Off" 2 "On (Whistle Noise Prevent)" 3 "Error Indicator" ;
VAL_ 2424580353 DATC_WdwClsReq 0 "Default" 1 "Close Request" 2 "Reserved" 3 "Error Indicator" ;
VAL_ 2424580353 DATC_RRSyncDis 0 "Rear SYNC Off" 1 "Rear SYNC On" 2 "Not used" 3 "Error Indicator" ;
VAL_ 171 BLTN_CAM_UI_Mode_Tmt_Req 0 "Default" 1 "BLTN_CAM UI Terminate Request" 2 "Reserved" 3 "invalid" ;
VAL_ 171 BLTN_CAM_Dis_Touch_BeepSound 0 "Off" 1 "ON" 2 "Keyboard On" 3 "invalid" ;
VAL_ 171 BLTN_CAM_PopUp_Req 0 "Default" 1 "Event Video Record On by manual switch" 2 "Time Lapse Record Started" 3 "Time Lapse Record Ended" 4 "micro SD card inserted" 5 "micro SD card removed" 6 "SD Card has problem(format required or need to be replaced)" 7 "Start Parking recording" 8 "Can not Start Parking recording (SD card is removed, not recognizable, or has problem)" 9 "Can not Record Event Video (SD card is removed, not recognizable, or has problem)" 10 "SD Card Unmounted" 11 "RESERVED" 12 "RESERVED" 13 "RESERVED" 14 "RESERVED" 15 "Invalid" ;
VAL_ 171 BLTN_CAM_File_List_Renew 0 "Defalut" 1 "the file list and storage space are renewed." 2 "reserved" 3 "Invalid" ;
VAL_ 171 BLTN_CAM_Wifi_Pwd_Chg_State 0 "Default" 1 "the password is changed" 2 "Failed, wrong password, can't change password" 3 "Invalid" ;
VAL_ 1253 SMK_Crc1Val 0 "0x0x0~0xFF:CRCValue" 255 "0x0x0~0xFF:CRCValue" ;
VAL_ 1253 SMK_AlvCnt1Val 0 "AlvCntValue" 1 "AlvCntValue" 2 "AlvCntValue" 3 "AlvCntValue" 4 "AlvCntValue" 5 "AlvCntValue" 6 "AlvCntValue" 7 "AlvCntValue" 8 "AlvCntValue" 9 "AlvCntValue" 10 "AlvCntValue" 11 "AlvCntValue" 12 "AlvCntValue" 13 "AlvCntValue" 14 "AlvCntValue" 15 "AlvCntValue" ;
VAL_ 1253 DoorLock_PsvDrLkReq 0 "None" 1 "Lock" 2 "PassiveTrunkLock" 3 "Reserved" 4 "Reserved" 5 "Reseved" 6 "Not Used" 7 "Error Indicator" ;
VAL_ 1253 DoorLock_PsvDrUnLkReq 0 "None" 1 "UnLock" 2 "Unlock only DRV Door" 3 "PIC_Key_Reminder" 4 "Reserved" 5 "Reseved" 6 "Not Used" 7 "Error Indicator" ;
VAL_ 1253 DoorLock_DrvDrPsvAcsReq 0 "Off" 1 "On" 2 "Not Used" 3 "Error Indicator" ;
VAL_ 1253 DoorLock_AsstDrPsvAcsReq 0 "Off" 1 "On" 2 "Not Used" 3 "Error Indicator" ;
VAL_ 1253 DoorLock_TrnkTlgtPsvAcsReq 0 "Off" 1 "On" 2 "Not Used" 3 "Error Indicator" ;
VAL_ 1253 DoorLock_RrLftDrPsvAcsReq 0 "Off" 1 "On" 2 "Not Used" 3 "Error Indicator" ;
VAL_ 1253 DoorLock_RrRtDrPsvAcsReq 0 "Off" 1 "On" 2 "Not Used" 3 "Error Indicator" ;
VAL_ 1253 DoorLock_PsdPsvAcsReq 0 "Off" 1 "Drv On" 2 "Ast On" 3 "Reserved" 4 "Reserved" 5 "Reseved" 6 "Not Used" 7 "Error Indicator" ;
VAL_ 1253 RSPA_DigitalKeyAuth 0 "Default" 1 "Digital Key Auth" 2 "Not used" 3 "Error Indicator" ;
VAL_ 1253 Auth_Method 0 "None Auth" 1 "Auth by FOB" 2 "Auth by TP" 3 "Auth by FP" 4 "Auth by NFC (DK or Card)" 5 "Auth Fail" 6 "Auth by BLE (CHINA)" 7 "FRU" 8 "Auth by Digital Key RKE" 9 "Auth by Digital Key Passive" 10 "Reserve" 11 "Reserve" 12 "Reserve" 13 "Reserve" 14 "Not used" 15 "Error Indicator" ;
VAL_ 1253 DoorLock_StrgbxPsvAcsReq 0 "Off" 1 "On" 2 "Not Used" 3 "Error Indicator" ;
VAL_ 1253 DoorLock_FrnkWrngOpnReq 0 "Off" 1 "On" 2 "Reserved" 3 "Error Indicator" ;
VAL_ 1253 DoorLock_SmrtPsdPsvAcsReq 0 "Off" 1 "Drv Door Open" 2 "Ast Door Open" 3 "Reserved" 4 "Reserved" 5 "Reserved" 6 "Not Used" 7 "Error Indicator" ;
VAL_ 1253 Auth_Event 0 "Default" 1 "Lock" 2 "Unlcok" 3 "Start" 4 "Trunk" 5 "Reserved" 6 "Reserved" 7 "Reserved" 8 "Reserved" 9 "Reserved" 10 "Reserved" 11 "Reserved" 12 "Reserved" 13 "Reserved" 14 "Not Used" 15 "Invalid" ;
VAL_ 1252 RKE_Crc1Val 0 "0x0x0~0xFF:CRCValue" 255 "0x0x0~0xFF:CRCValue" ;
VAL_ 1252 RKE_AlvCnt1Val 0 "AlvCntValue" 1 "AlvCntValue" 2 "AlvCntValue" 3 "AlvCntValue" 4 "AlvCntValue" 5 "AlvCntValue" 6 "AlvCntValue" 7 "AlvCntValue" 8 "AlvCntValue" 9 "AlvCntValue" 10 "AlvCntValue" 11 "AlvCntValue" 12 "AlvCntValue" 13 "AlvCntValue" 14 "AlvCntValue" 15 "AlvCntValue" ;
VAL_ 1252 RKE_BtnReq 0 "None" 1 "Lock" 2 "Unlock" 3 "Trunk(Or Tail Gate)" 4 "Panic" 5 "Panic Stop" 6 "Two Step Unlock Warning or India Door Lock/Unlock Sound ON/OFF Set" 7 "Remote Cranking Stop" 8 "Remote Cranking Start" 9 "Forward(RSPA)" 10 "Backward/Parking(RSPA)" 11 "Pause(RSPA)" 12 "Front Trunk" 13 "Reserved" 14 "Charge Door / ImmeChg" 15 "Error Indicator" ;
VAL_ 1252 RKE_PsdBtnReq 0 "Off" 1 "LH On" 2 "RH On" 3 "PanicStop_PSD LH" 4 "PanicStop_PSD RH" 5 "Reseved" 6 "Reseved" 7 "Reserved" 8 "Reserved" 9 "Reserved" 10 "Reserved" 11 "Reserved" 12 "Reserved" 13 "Reserved" 14 "Not Used" 15 "Error Indicator" ;
VAL_ 1252 RKE_WdwUpDnReq 0 "None" 1 "Remote Window Open" 2 "Remote Window Close" 3 "Remote Window Stop" 4 "Reseved" 5 "Reseved" 6 "Not Used" 7 "Error Indicator" ;
VAL_ 1252 RKE_TrnkTlgtBtnReq 0 "Default" 1 "TailgateTrunkOn" 2 "Off" 3 "Reserved" 4 "Reserved" 5 "Reseved" 6 "Reseved" 7 "Error Indiator" ;
VAL_ 1252 RKE_ID 0 "None" 1 "ID1" 2 "ID2" 3 "ID3" 4 "ID4" 5 "Reseved" 6 "Not Used" 7 "Error Indicator" ;
VAL_ 1252 RKE_PwrDrAllOpnClsReq 0 "None" 1 "Open" 2 "Close" 3 "Stop" 4 "Reserved" 5 "Reserved" 6 "Reserved" 7 "Reserved" ;
VAL_ 1251 IAU_EsyAcsProfileID 0 "Default" 1 "Profile 1" 2 "Profile 2" 3 "Guest" ;
VAL_ 1251 IAU_SmrtPhnID 0 "None" 1 "ID1" 2 "ID2" 3 "ID3" 4 "ID4" 5 "ID5" 6 "ID6" 7 "ID7" 8 "ID8" 9 "Reseved" 10 "Reseved" 11 "Reseved" 12 "Reseved" 13 "Reseved" 14 "Reseved" 15 "Reseved" ;
VAL_ 1251 IAU_SmrtPhnCmd 0 "None" 1 "Reserved" 2 "Reserved" 3 "Reserved" 4 "Reserved" 5 "Reserved" 6 "Reserved" 7 "Tele Cranking Stop" 8 "Reserved" 9 "Forward (RSPA)" 10 "Backward/Parking (RSPA)" 11 "Pause (RSPA)" 12 "PL Lft Out" 13 "PL Rt Out" 14 "Reserved" 15 "Reserved" ;
VAL_ 1251 IAUwFRU_ISK_LearningReq 0 "Default (Normal)" 1 "Start with PSK #1" 2 "Start with PSK #2" 3 "Start with PSK #3" 4 "Start with PSK #4" 5 "Start with PSK #5" 6 "Stop" 7 "Neutral" 8 "Reserved" 9 "Reserved" 10 "Reserved" 11 "Reserved" 12 "Reserved" 13 "Reserved" 14 "Reserved" 15 "Invalid" ;
VAL_ 1251 IAUwFPM_ISK_LearningReq 0 "Default" 1 "Start with PSK #1" 2 "Start with PSK #2" 3 "Start with PSK #3" 4 "Start with PSK #4" 5 "Start with PSK #5" 6 "Stop" 7 "Neutral" 8 "Reserved" 9 "Reserved" 10 "Reserved" 11 "Reserved" 12 "Reserved" 13 "Reserved" 14 "Reserved" 15 "Invalid" ;
VAL_ 1251 IAU2FRU_ISKLearnFdbck 0 "Default" 1 "Positive" 2 "Negative" 3 "Invalid" ;
VAL_ 1251 IAU2FPM_ISKLearnFdbck 0 "Default" 1 "Positive" 2 "Negative" 3 "Invalid" ;
VAL_ 172 BLTN_CAM_FR_VerPos_NvalueSet 0 "Mid" 1 "Upper Level (1 ~ 10)" 2 "Upper Level (1 ~ 10)" 3 "Upper Level (1 ~ 10)" 4 "Upper Level (1 ~ 10)" 5 "Upper Level (1 ~ 10)" 6 "Upper Level (1 ~ 10)" 7 "Upper Level (1 ~ 10)" 8 "Upper Level (1 ~ 10)" 9 "Upper Level (1 ~ 10)" 10 "Upper Level (1 ~ 10)" 11 "Reserved" 12 "Reserved" 13 "Reserved" 14 "Reserved" 15 "Reserved" 16 "Reserved" 17 "Lower Level (-1 ~ -10)" 18 "Lower Level (-1 ~ -10)" 19 "Lower Level (-1 ~ -10)" 20 "Lower Level (-1 ~ -10)" 21 "Lower Level (-1 ~ -10)" 22 "Lower Level (-1 ~ -10)" 23 "Lower Level (-1 ~ -10)" 24 "Lower Level (-1 ~ -10)" 25 "Lower Level (-1 ~ -10)" 26 "Lower Level (-1 ~ -10)" 27 "Reserved" 28 "Reserved" 29 "Reserved" 30 "Reserved" 31 "Invalid" ;
VAL_ 172 BLTN_CAM_AppNoti_PEV_NvalueSet 0 "Default" 1 "Off" 2 "On" 3 "Invalid" ;
VAL_ 172 BLTN_CAM_WiFi_AutoOn_NvalueSet 0 "Default" 1 "Off" 2 "On" 3 "Invalid" ;
VAL_ 172 BLTN_CAM_StoProp_NvalueSet 0 "Normal" 1 "On While Recordings" 2 "On While Parked" 3 "Driving Events" 4 "Parked Events" 5 "Reserved" 6 "Reserved" 7 "Reserved" 8 "Reserved" 9 "Reserved" 10 "Reserved" 11 "Reserved" 12 "Reserved" 13 "Reserved" 14 "Reserved" 15 "Invalid" ;
VAL_ 172 CF_AVN_BLTN_CAM_USMReset 0 "Default" 1 "Built-in CAM USM Reset" 2 "Reserved" 3 "Invalid" ;
VAL_ 172 CF_AVN_BLTN_CAM_RecReset 0 "Default" 1 "Record Data Reset(format)" 2 "Reserved" 3 "Invalid" ;
VAL_ 172 BLTN_CAM_File_DEL_CPY_Cmd 0 "Default" 1 "Pause the operation" 2 "Cancel the operation" 3 "Continue operation" 4 "Reserved" 5 "Reserved" 6 "Reserved" 7 "Reserved" 8 "Reserved" 9 "Reserved" 10 "Reserved" 11 "Reserved" 12 "Reserved" 13 "Reserved" 14 "Reserved" 15 "Invalid" ;
VAL_ 172 BLTN_CAM_LVDS_Mode_Cmd 0 "Front and Rear Camera" 1 "Front Camera for AR Navi." 2 "Built-In Cam Engineer Mode" 3 "Reserved" ;
VAL_ 172 HU_BLTN_CAM_Disp_Touch_Pos_X 0 "0x0x0~0x77F:X position of the touch(Pixel)" 1919 "0x0x0~0x77F:X position of the touch(Pixel)" 2046 "Default" 2047 "Invalid" ;
VAL_ 172 HU_BLTN_CAM_Disp_Touch_Pos_Y 0 "0x0x0~0x3FD:Y position of the touch(Pixel)" 1021 "0x0x0~0x3FD:Y position of the touch(Pixel)" 1022 "Default" 1023 "Invalid" ;
VAL_ 172 MEV_Rec_Req 0 "Default" 1 "On" 2 "RESERVED" 3 "Invalid" ;
VAL_ 172 BLTN_CAM_RR_VerPos_NvalueSet 0 "Mid" 1 "Upper Level (1 ~ 10)" 2 "Upper Level (1 ~ 10)" 3 "Upper Level (1 ~ 10)" 4 "Upper Level (1 ~ 10)" 5 "Upper Level (1 ~ 10)" 6 "Upper Level (1 ~ 10)" 7 "Upper Level (1 ~ 10)" 8 "Upper Level (1 ~ 10)" 9 "Upper Level (1 ~ 10)" 10 "Upper Level (1 ~ 10)" 11 "Reserved" 12 "Reserved" 13 "Reserved" 14 "Reserved" 15 "Reserved" 16 "Reserved" 17 "Lower Level (-1 ~ -10)" 18 "Lower Level (-1 ~ -10)" 19 "Lower Level (-1 ~ -10)" 20 "Lower Level (-1 ~ -10)" 21 "Lower Level (-1 ~ -10)" 22 "Lower Level (-1 ~ -10)" 23 "Lower Level (-1 ~ -10)" 24 "Lower Level (-1 ~ -10)" 25 "Lower Level (-1 ~ -10)" 26 "Lower Level (-1 ~ -10)" 27 "Reserved" 28 "Reserved" 29 "Reserved" 30 "Reserved" 31 "Invalid" ;
VAL_ 172 TML_Rec_Req 0 "Default" 1 "Start Request" 2 "End Request" 3 "Invalid" ;
VAL_ 172 BLTN_CAM_SD_Card_UnMt_Mt_Req 0 "Default" 1 "UnMount Request" 2 "Mount Request" 3 "Invalid" ;
VAL_ 2227254529 BAT_Crc1Val 0 "0x0x0~0xFFFF:CRCValue" 65535 "0x0x0~0xFFFF:CRCValue" ;
VAL_ 2227254529 BAT_AlvCnt1Val 0 "0x0x0~0xFF:AlvCntValue" 255 "0x0x0~0xFF:AlvCntValue" ;
VAL_ 2227254529 BAT_CurrVal 65535 "Error indicator" ;
VAL_ 2227254529 BAT_SocVal 255 "Error indicator" ;
VAL_ 2227254529 BAT_VoltVal 16383 "Error indicator" ;
VAL_ 2227254529 BAT_AuxBattOpt 0 "Not used" 1 "12V LFP Battery is applied" 2 "12V LFP Battery is not applied" 3 "Error indicator" ;
VAL_ 2227254530 BAT_TempVal 511 "Error indicator" ;
VAL_ 2227254530 BAT_SohVal 127 "Error indicator" ;
VAL_ 2227254530 BAT_SnsrInvldSta 0 "Valid Condition" 1 "Invalid Condition" 2 "Not used" 3 "Error indicator" ;
VAL_ 2227254530 BAT_SofVal 127 "Error indicator" ;
VAL_ 2227254530 BAT_RspErrSta 0 "Operating correctly" 1 "Response error" 2 "Not used" 3 "Error indicator" ;
VAL_ 2227254530 BAT_CapacityVal 255 "Error" ;
VAL_ 2227254530 BAT_SocErrSta 0 "Nomal State" 1 "Implausible State" 2 "Not used" 3 "Error indicator" ;
VAL_ 1266 HU_LanguageInfo 0 "Off" 1 "Korea" 2 "English(US)" 3 "English(UK)" 4 "Simplified chinese" 5 "Traditional chinese" 6 "French(EU)" 7 "Spanish(EU)" 8 "Arabic" 9 "Czech" 10 "Danish" 11 "German" 12 "Italian" 13 "Dutch" 14 "Polish" 15 "Portuguese" 16 "Russain" 17 "Slovak" 18 "Swedish" 19 "Turkish" 20 "French(US)" 21 "Spanish(US)" 22 "English(India)" 23 "Norwegian" 24 "Finnish" 25 "Indonesian" 26 "Brazilian Portuguese" 27 "Malay" 28 "Hungarian" 29 "English (Australia)" 30 "Japanese" 31 "Hindi" 32 "Hebrew" 33 "Greek" 34 "Ukrainian" 35 "Slovenian" 36 "Bulgarian" 37 "Croatian" 38 "Romanian" 39 "Bengali" 40 "Marathi" 41 "Telugu" 42 "Tamil" 43 "Gujarati" 44 "Kannada" 45 "Odia" 46 "Malayalam" 47 "Punjabi" 48 "Thai" 49 "Tagalog" 50 "Vietnamese" 51 "0x33~0xFE:Reserved" 254 "0x33~0xFE:Reserved" 255 "Invalid" ;
VAL_ 1266 HU_MuteStatus 0 "Off" 1 "Mute On" 2 "reserved" 3 "Invalid" ;
VAL_ 1266 HU_WelcomeReady 0 "Default" 1 "Welcome ready" 2 "Goodbye ready" 3 "Invalid" ;
VAL_ 1266 HU_UsmSupport 0 "Not support" 1 "Support" 2 "reserved" 3 "Invalid" ;
VAL_ 1266 HU_NaviStatus 0 "Booting" 1 "Normal Operation" 2 "No SD Card(Map)" 3 "Invalid" ;
VAL_ 1266 HU_NaviDisp 0 "Non_Navi" 1 "Navi" 2 "reserved" 3 "Invalid" ;
VAL_ 1266 HU_BVM_Display_Message 0 "Not Used" 1 "No Message" 2 "Rain_Warning Message" 3 "Reserved" 4 "Reserved" 5 "Reserved" 6 "Reserved" 7 "Invalid" ;
VAL_ 1266 HU_SVM_View_Display 0 "Not Used" 1 "AVM Display View OFF" 31 "Invalid" 2 "AVM Display View ON(LH)" 3 "AVM Display View ON(RH)" 4 "Reserved" 5 "Reserved" 6 "Reserved" 7 "Reserved" 8 "Reserved" 9 "Reserved" 10 "Reserved" 11 "Reserved" 12 "Reserved" 13 "Reserved" 14 "Reserved" 15 "Reserved" 16 "Reserved" 17 "Reserved" 18 "Reserved" 19 "Reserved" 20 "Reserved" 21 "Reserved" 22 "Reserved" 23 "Reserved" 24 "Reserved" 25 "Reserved" 26 "Reserved" 27 "Reserved" 28 "Reserved" 29 "Reserved" 30 "Reserved" ;
VAL_ 1266 HU_NaviCamSettingStatus 0 "Navi Camera Alert Setting Status" 1 "Navi Camera Alert Setting Status" 2 "Navi Camera Alert Setting Status" 3 "Navi Camera Alert Setting Status" 4 "Navi Camera Alert Setting Status" 5 "Navi Camera Alert Setting Status" 6 "Navi Camera Alert Setting Status" 7 "Navi Camera Alert Setting Status" 8 "Navi Camera Alert Setting Status" 9 "Navi Camera Alert Setting Status" 10 "Navi Camera Alert Setting Status" 11 "Navi Camera Alert Setting Status" 12 "Navi Camera Alert Setting Status" 13 "Navi Camera Alert Setting Status" 14 "Navi Camera Alert Setting Status" 15 "Navi Camera Alert Setting Status" 16 "Navi Camera Alert Setting Status" 17 "Navi Camera Alert Setting Status" 18 "Navi Camera Alert Setting Status" 19 "Navi Camera Alert Setting Status" 20 "Navi Camera Alert Setting Status" 21 "Navi Camera Alert Setting Status" 22 "Navi Camera Alert Setting Status" 23 "Navi Camera Alert Setting Status" 24 "Navi Camera Alert Setting Status" 25 "Navi Camera Alert Setting Status" 26 "Navi Camera Alert Setting Status" 27 "Navi Camera Alert Setting Status" 28 "Navi Camera Alert Setting Status" 29 "Navi Camera Alert Setting Status" 30 "Navi Camera Alert Setting Status" 31 "Navi Camera Alert Setting Status" 32 "0x20~0xFE:Reserved" 254 "0x20~0xFE:Reserved" 255 "Invalid" ;
VAL_ 1266 HU_EVSupport 0 "Not support" 1 "Support" 2 "Reserved" 3 "Invalid" ;
VAL_ 1266 HU_DayNightState 0 "Default" 1 "Day" 2 "Night" 3 "Invalid" ;
VAL_ 1266 HU_AutoBrightState_New 0 "Default" 1 "0x1~0x3FE:Brightness" 1022 "0x1~0x3FE:Brightness" 1023 "Invalid" ;
VAL_ 1266 HU_VolumeStatus 63 "Invalid" ;
VAL_ 1267 RSELockOnOff 0 "Unlock" 1 "LockOn" 2 "Reserved" 3 "Invalid" ;
VAL_ 1267 HU_ClimateScrnState 0 "Other Screen" 1 "Front Climate Screen" 2 "Rear Climate Screen" 3 "Invalid (Default)" ;
VAL_ 1267 HU_Graphreset_Info 0 "No Action" 1 "Clear Request" 2 "Reserved" 3 "Invalid" ;
VAL_ 1267 HU_VRActivity 0 "Deactivated" 1 "Activated" 2 "reserved" 3 "Invalid" ;
VAL_ 1267 HU_DATC_AirQuality_Info 0 "No information" 1 "level 1" 2 "level 2" 3 "level 3" 4 "level 4" 5 "level 5" 6 "level 6" 7 "reserved" 8 "reserved" 9 "reserved" 10 "reserved" 11 "reserved" 12 "reserved" 13 "reserved" 14 "reserved" 15 "invalid" ;
VAL_ 191 RL_SHVU_DTCdisplay 0 "DTC is not exist(Fail is not exist)" 1 "IGN2 Fuse Open Detection" 2 "Switch Input Detection at Same Time" 3 "NTC/Heating wire Open Detection" 4 "NTC+/NTC- Terminal Short Detection" 5 "NTC+/Heater+ Terminal Short Detection" 6 "NTC+/Heater-, Heater+/Heater-, Heater+/NTC- Terminal Short Detection" 7 "NTC+/Heater- Wiring Short Detection" 8 "NTC+/Heater-, Heater+/Heater-, Heater+/NTC- Wiring Short Detection" 9 "Target Temperature Dissatisfied" 10 "Blower+/Blower- Short, Blower+/Blower Speed, Blower-/Blower Speed Wiring Short Detection" 11 "Blower+/Blower RPM, Blower-/Blower RPM, Blower Speed/Blower RPM Short Detection" 12 "Blower+, Blower-, Blower Speed Signal open Detection" 13 "Blower RPM signal Open Detection" 14 "0xE~0xFD:Unused" 253 "0xE~0xFD:Unused" 254 "No Display" 255 "Invalid" ;
VAL_ 191 RL_SHVU_DiagMode 0 "Default" 1 "DTC Mode" 2 "Normal Mode" 3 "Invalid" ;
VAL_ 1264 HU_TimeSetting 0 "not used" 1 "User Time" 2 "GPS Time" 3 "invalid" ;
VAL_ 1264 HU_DisplayMinute 0 "0 minute" 59 "59 Minute" 255 "invalid" ;
VAL_ 1264 HU_Status 0 "not used" 1 "Booting Head Unit" 2 "GPS receiving" 3 "Setting Mode" 4 "GPS Unavailable Mode" 5 "No GPS" 15 "invalid" ;
VAL_ 1264 HU_DisplaySecond 0 "0 minute" 59 "59 second" 255 "invalid" ;
VAL_ 1264 HU_DisplayMonth 0 "not used" 1 "1 month" 12 "12 month" 15 "invalid" ;
VAL_ 1264 HU_DisplayYear1 0 "19" 1 "20" 2 "21" 3 "invalid" ;
VAL_ 1264 HU_DisplayYear2 0 "0 year" 99 "99 year" 255 "invalid" ;
VAL_ 1264 HU_DisplayDay 0 "not used" 1 "1 day" 31 "31 day" 255 "invalid" ;
VAL_ 1264 HU_AM_PM_INFO 0 "Not Used" 1 "AM" 2 "PM" 3 "invalid" ;
VAL_ 1264 HU_TimeFormat 0 "Not used" 1 "12Hour" 2 "24Hour" 3 "invalid" ;
VAL_ 1264 HU_ComRefresh 0 "Not Used" 1 "Internal Clock None" 2 "Internal Clock Exist" 3 "Invalid" ;
VAL_ 1264 HU_ClockInfo 0 "Not Used" 1 "ACLOCK Refresh" 2 "Not Used" 3 "invalid" ;
VAL_ 1264 HU_DisplayHour 0 "0 Hour" 23 "23 Hour" 255 "invalid" ;
VAL_ 1265 HU_IG3_Request 0 "Off" 1 "On" 2 "Reserved" 3 "Invalid" ;
VAL_ 1265 HU_Background 0 "Default" 1 "Day" 2 "Night" 3 "Reserved" 4 "Reserved" 5 "Reserved" 6 "Reserved" 7 "Invalid" ;
VAL_ 1265 ccIC_HUD_PbackSta 0 "Stop" 1 "Play 1" 2 "Play 2" 3 "Health Care IMS" 4 "Profile 1" 5 "Profile 2" 6 "Guest" 7 "Invalid" ;
VAL_ 1265 HU_BackgroundFadeInOut 0 "0x0x0~0x3E8:0.0~100.0%" 1000 "0x0x0~0x3E8:0.0~100.0%" 1001 "Reserved" 1002 "Reserved" 1003 "Reserved" 1004 "Reserved" 1005 "Reserved" 1006 "Reserved" 1007 "Reserved" 1008 "Reserved" 1009 "Reserved" 1010 "Reserved" 1011 "Reserved" 1012 "Reserved" 1013 "Reserved" 1014 "Reserved" 1015 "Reserved" 1016 "Reserved" 1017 "Reserved" 1018 "Reserved" 1019 "Reserved" 1020 "Reserved" 1021 "Reserved" 1022 "Default" 1023 "Invalid" ;
VAL_ 1265 CF_AVN_AutoWashModeSta 0 "Default" 1 "Non Auto Wash Mode" 2 "Auto Wash Mode" 3 "RESERVED" 4 "RESERVED" 5 "RESERVED" 6 "RESERVED" 7 "Invalid" ;
VAL_ 1265 OMUOSMirCtrl_Vr 0 "Off" 1 "Fold" 2 "Unfold" 3 "invalid" ;
VAL_ 2328016132 VCU_StopCtrlWarnMsgSta 0 "None" 1 "i-Pedal On Popup Request" 2 "i-Pedal Off Popup Request" 3 "i-Pedal Forced Off Popup Request" 4 "SAC Off Popup Request" 5 "Reserved" 6 "Reserved" 7 "Reserved" ;
VAL_ 2328016132 VCU_DrvModeDefault 0 "No Data" 1 "Normal (Comfort)" 2 "ECO" 3 "Reserved" ;
VAL_ 1278 HU_Type 16 "AVN(Tuner DVD KOR)" 17 "AVN(Tuner DVD EUR)" 18 "AVN(Tuner DVD China)" 19 "AVN(Tuner DVD Japan)" 20 "AVN(Tuner DVD EUR)" 21 "AVN(Tuner CDP KOR)" 22 "AVN(Tuner CDP EUR)" 23 "AVN(Tuner CDP China)" 24 "AVN(Tuner CDP Japan)" 25 "AVN(Tuner CDP EUR)" 32 "AVNT (Open)" 33 "AVNT (Not open)" 48 "Economic Audio" 64 "Standard Audio (3.0 below)" 65 "Standard Audio 4.0" 66 "STD Audio-3.0Below,No interwork" 67 "Audio 4.0 Value" 80 "AV(Tuner DVD KOR)" 81 "AV(Tuner DVD EUR)" 82 "AV(Tuner DVD China)" 83 "AV(Tuner DVD Japan)" 84 "AV(Tuner DVD EUR)" 85 "AV(Tuner CDP KOR)" 86 "AV(Tuner CDP EUR)" 87 "AV(Tuner CDP China)" 88 "AV(Tuner CDP Japan)" 89 "AV(Tuner CDP EUR)" 96 "AVN 4.0" 97 "Premium AVN2.0" 98 "EU AVN 2.0" 99 "Super Premium w Navi" 100 "Super Premium w_o Navi" 101 "Premium w Navi" 102 "Premium w_o Navi" 103 "Display Audio w_o Navi" 104 "Integrated AVN 1.0 Mobis" 105 "Gen5 Standard Nav Wide" 112 "Compact AVN & Integrated AVN 1.0 LG" 113 "Standard-class Gen6 Navigation" 128 "Premium Navi 5th Gen(w_Navi)" 129 "Premium Navi 5th Gen(w_o Navi)" 130 "Premium Navi 6th Gen(w_Navi)" 131 "Premium Navi 6th Gen(w_o Navi)" 132 "ccNC(w Navi)" 133 "ccNC(w_o Navi)" 134 "ccIC(w Navi)" 135 "ccIC(w_o Navi)" 238 "India PIO w_o CLU interface" 239 "India PIO w_CLU interface" 241 "Gen 1 China OEM Navigation" 250 "PIO AVN" 251 "China  Local OEM Display Audio" 252 "China OPIO w_o CLU interface" 253 "China OPIO w_CLU interface" 254 "China Local OEM AVNT" 255 "Invalid" ;
VAL_ 1278 HU_DistributeInfo 0 "Default (Korea)" 1 "Korea" 2 "North America" 3 "Canada" 4 "East Europe" 5 "West Europe" 6 "China" 7 "India" 8 "Australia" 9 "Middle East" 10 "Africa" 11 "South America" 12 "Russia" 13 "Japan" 14 "General" 15 "0x0F~0xFE:Reserved" 254 "0x0F~0xFE:Reserved" 255 "Invalid" ;
VAL_ 1278 HU_OptionInfo 32768 "Invalid" ;
VAL_ 1278 HU_NaviMapInfo 0 "Unknown" 1 "Korea" 2 "North America" 3 "Europe" 4 "Middle East" 5 "Australia" 6 "South America" 7 "China" 8 "Russia" 9 "Turkey" 10 "India" 11 "Japan" 15 "Invalid" ;
VAL_ 1278 HU_NaviHandshakingSupport 0 "Not Support" 1 "Support" 2 "Unknown" 3 "Invalid" ;
VAL_ 1278 HU_AMP_EQVariant 0 "Default" 1 "WGN" 2 "WGN PHEV" 3 "5DR" 4 "SB" 5 "CUV" 6 "HEV" 7 "PHEV" 8 "EV" 9 "Reserved" 10 "Reserved" 11 "Reserved" 12 "Reserved" 13 "Reserved" 14 "Reserved" 15 "Reserved" 16 "Reserved" 17 "Reserved" 18 "Reserved" 19 "Reserved" 20 "Reserved" 21 "Reserved" 22 "Reserved" 23 "Reserved" 24 "Reserved" 25 "Reserved" 26 "Reserved" 27 "Reserved" 28 "Reserved" 29 "Reserved" 30 "Reserved" ;
VAL_ 1278 HU_AdasSupport 0 "Not Support" 1 "ADAS Support(General Map)" 2 "ADAS Support(Map based ADAS v1)" 3 "ADAS Support(Map based ADAS v2)" 4 "ADAS Support(Map based ADAS v2 & Handshaking)" 5 "ADAS Support(Map based ADAS v2_3)" 6 "Reserved" 7 "Invalid" ;
VAL_ 1278 HU_Navi_RspADASMapMsg 0 "0x0x0~0xFFFF:Refer to Signal Description" 65535 "0x0x0~0xFFFF:Refer to Signal Description" ;
